VERSION "canboat-NMEA2000-curated"

NS_ :

BS_:

BU_: Vector__XXX
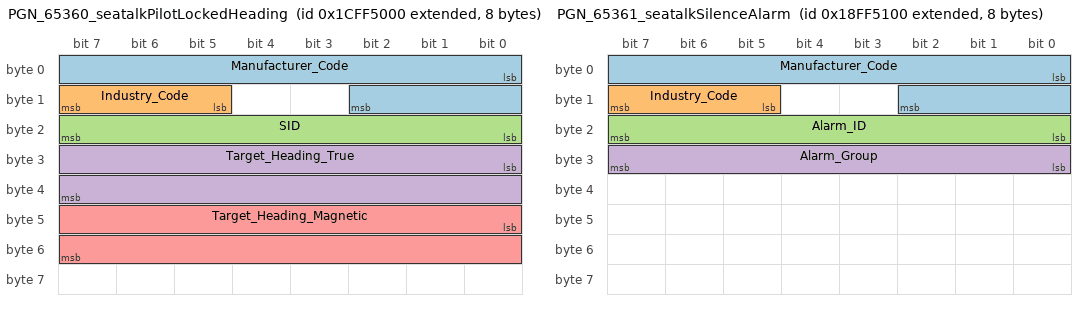
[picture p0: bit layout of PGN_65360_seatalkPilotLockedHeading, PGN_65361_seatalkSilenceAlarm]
BO_ 2633977856 PGN_65360_seatalkPilotLockedHeading: 8 Vector__XXX
 SG_ Manufacturer_Code : 0|11@1+ (1.0,0) [0|2047] "" Vector__XXX
 SG_ Industry_Code : 13|3@1+ (1.0,0) [0|7] "" Vector__XXX
 SG_ SID : 16|8@1+ (1.0,0) [0|255] "" Vector__XXX
 SG_ Target_Heading_True : 24|16@1+ (0.0001,0) [0.0|6.5535000000000005] "" Vector__XXX
 SG_ Target_Heading_Magnetic : 40|16@1+ (0.0001,0) [0.0|6.5535000000000005] "" Vector__XXX

BO_ 2566869248 PGN_65361_seatalkSilenceAlarm: 8 Vector__XXX
 SG_ Manufacturer_Code : 0|11@1+ (1.0,0) [0|2047] "" Vector__XXX
 SG_ Industry_Code : 13|3@1+ (1.0,0) [0|7] "" Vector__XXX
 SG_ Alarm_ID : 16|8@1+ (1.0,0) [0|255] "" Vector__XXX
 SG_ Alarm_Group : 24|8@1+ (1.0,0) [0|255] "" Vector__XXX

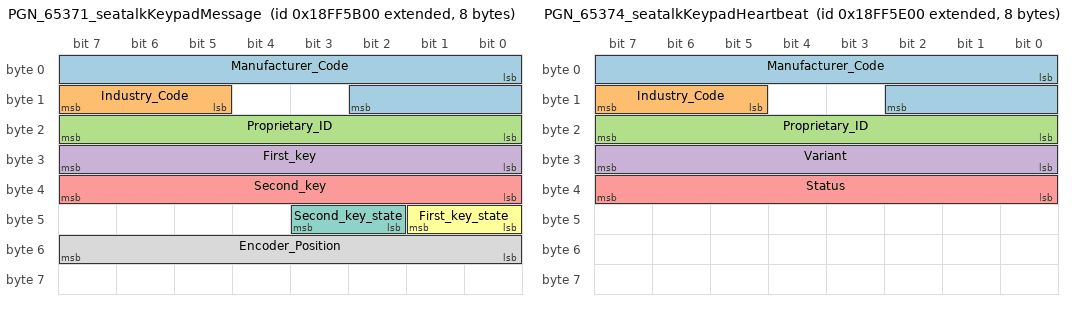
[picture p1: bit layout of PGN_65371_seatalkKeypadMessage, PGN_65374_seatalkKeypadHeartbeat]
BO_ 2566871808 PGN_65371_seatalkKeypadMessage: 8 Vector__XXX
 SG_ Manufacturer_Code : 0|11@1+ (1.0,0) [0|2047] "" Vector__XXX
 SG_ Industry_Code : 13|3@1+ (1.0,0) [0|7] "" Vector__XXX
 SG_ Proprietary_ID : 16|8@1+ (1.0,0) [0|255] "" Vector__XXX
 SG_ First_key : 24|8@1+ (1.0,0) [0|255] "" Vector__XXX
 SG_ Second_key : 32|8@1+ (1.0,0) [0|255] "" Vector__XXX
 SG_ First_key_state : 40|2@1+ (1.0,0) [0|3] "" Vector__XXX
 SG_ Second_key_state : 42|2@1+ (1.0,0) [0|3] "" Vector__XXX
 SG_ Encoder_Position : 48|8@1+ (1.0,0) [0|255] "" Vector__XXX

BO_ 2566872576 PGN_65374_seatalkKeypadHeartbeat: 8 Vector__XXX
 SG_ Manufacturer_Code : 0|11@1+ (1.0,0) [0|2047] "" Vector__XXX
 SG_ Industry_Code : 13|3@1+ (1.0,0) [0|7] "" Vector__XXX
 SG_ Proprietary_ID : 16|8@1+ (1.0,0) [0|255] "" Vector__XXX
 SG_ Variant : 24|8@1+ (1.0,0) [0|255] "" Vector__XXX
 SG_ Status : 32|8@1+ (1.0,0) [0|255] "" Vector__XXX

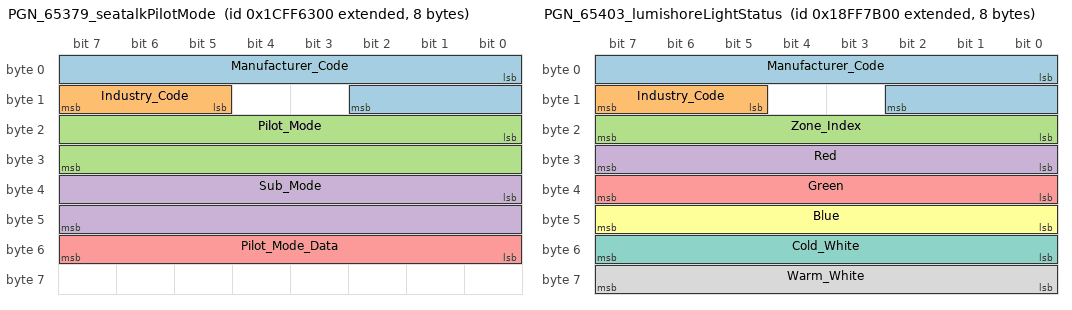
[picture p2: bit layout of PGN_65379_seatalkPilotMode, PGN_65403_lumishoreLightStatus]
BO_ 2633982720 PGN_65379_seatalkPilotMode: 8 Vector__XXX
 SG_ Manufacturer_Code : 0|11@1+ (1.0,0) [0|2047] "" Vector__XXX
 SG_ Industry_Code : 13|3@1+ (1.0,0) [0|7] "" Vector__XXX
 SG_ Pilot_Mode : 16|16@1+ (1.0,0) [0|65535] "" Vector__XXX
 SG_ Sub_Mode : 32|16@1+ (1.0,0) [0|65535] "" Vector__XXX
 SG_ Pilot_Mode_Data : 48|8@1+ (1.0,0) [0|255] "" Vector__XXX

BO_ 2566880000 PGN_65403_lumishoreLightStatus: 8 Vector__XXX
 SG_ Manufacturer_Code : 0|11@1+ (1.0,0) [0|2047] "" Vector__XXX
 SG_ Industry_Code : 13|3@1+ (1.0,0) [0|7] "" Vector__XXX
 SG_ Zone_Index : 16|8@1+ (1.0,0) [0|255] "" Vector__XXX
 SG_ Red : 24|8@1+ (1.0,0) [0|255] "" Vector__XXX
 SG_ Green : 32|8@1+ (1.0,0) [0|255] "" Vector__XXX
 SG_ Blue : 40|8@1+ (1.0,0) [0|255] "" Vector__XXX
 SG_ Cold_White : 48|8@1+ (1.0,0) [0|255] "" Vector__XXX
 SG_ Warm_White : 56|8@1+ (1.0,0) [0|255] "" Vector__XXX

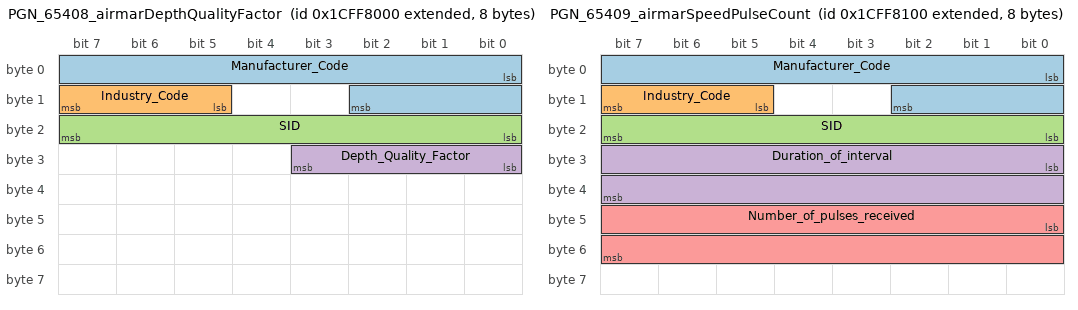
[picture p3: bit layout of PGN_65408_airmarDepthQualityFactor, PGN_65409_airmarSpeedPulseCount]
BO_ 2633990144 PGN_65408_airmarDepthQualityFactor: 8 Vector__XXX
 SG_ Manufacturer_Code : 0|11@1+ (1.0,0) [0|2047] "" Vector__XXX
 SG_ Industry_Code : 13|3@1+ (1.0,0) [0|7] "" Vector__XXX
 SG_ SID : 16|8@1+ (1.0,0) [0|255] "" Vector__XXX
 SG_ Depth_Quality_Factor : 24|4@1+ (1.0,0) [0|15] "" Vector__XXX

BO_ 2633990400 PGN_65409_airmarSpeedPulseCount: 8 Vector__XXX
 SG_ Manufacturer_Code : 0|11@1+ (1.0,0) [0|2047] "" Vector__XXX
 SG_ Industry_Code : 13|3@1+ (1.0,0) [0|7] "" Vector__XXX
 SG_ SID : 16|8@1+ (1.0,0) [0|255] "" Vector__XXX
 SG_ Duration_of_interval : 24|16@1+ (0.001,0) [0.0|65.535] "" Vector__XXX
 SG_ Number_of_pulses_received : 40|16@1+ (1.0,0) [0|65535] "" Vector__XXX

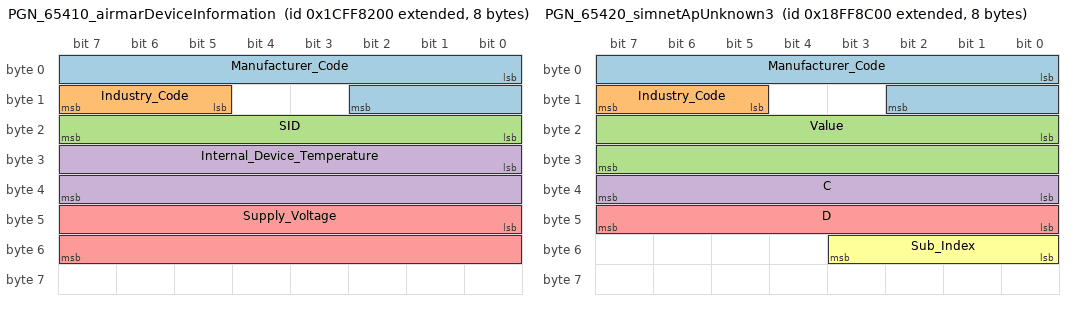
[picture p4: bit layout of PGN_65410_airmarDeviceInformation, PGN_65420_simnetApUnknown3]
BO_ 2633990656 PGN_65410_airmarDeviceInformation: 8 Vector__XXX
 SG_ Manufacturer_Code : 0|11@1+ (1.0,0) [0|2047] "" Vector__XXX
 SG_ Industry_Code : 13|3@1+ (1.0,0) [0|7] "" Vector__XXX
 SG_ SID : 16|8@1+ (1.0,0) [0|255] "" Vector__XXX
 SG_ Internal_Device_Temperature : 24|16@1+ (0.01,0) [0.0|655.35] "" Vector__XXX
 SG_ Supply_Voltage : 40|16@1+ (0.01,0) [0.0|655.35] "" Vector__XXX

BO_ 2566884352 PGN_65420_simnetApUnknown3: 8 Vector__XXX
 SG_ Manufacturer_Code : 0|11@1+ (1.0,0) [0|2047] "" Vector__XXX
 SG_ Industry_Code : 13|3@1+ (1.0,0) [0|7] "" Vector__XXX
 SG_ Value : 16|16@1+ (1.0,0) [0|65535] "" Vector__XXX
 SG_ C : 32|8@1+ (1.0,0) [0|255] "" Vector__XXX
 SG_ D : 40|8@1+ (1.0,0) [0|255] "" Vector__XXX
 SG_ Sub_Index : 48|4@1+ (1.0,0) [0|15] "" Vector__XXX

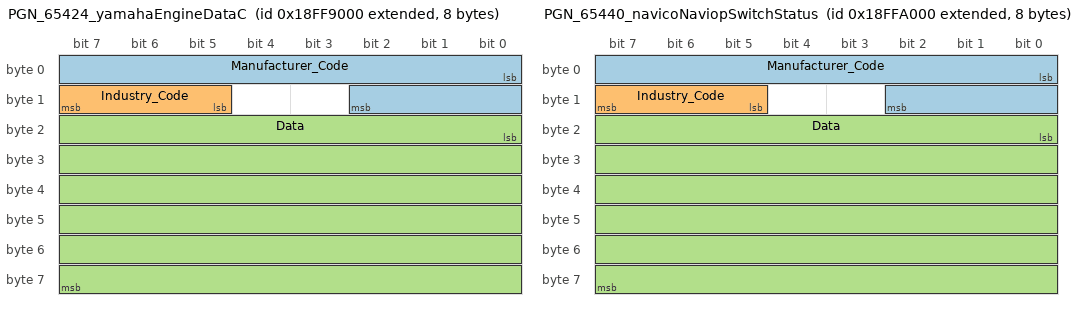
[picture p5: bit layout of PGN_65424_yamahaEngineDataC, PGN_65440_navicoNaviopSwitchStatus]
BO_ 2566885376 PGN_65424_yamahaEngineDataC: 8 Vector__XXX
 SG_ Manufacturer_Code : 0|11@1+ (1.0,0) [0|2047] "" Vector__XXX
 SG_ Industry_Code : 13|3@1+ (1.0,0) [0|7] "" Vector__XXX
 SG_ Data : 16|48@1+ (1.0,0) [0|281474976710655] "" Vector__XXX

BO_ 2566889472 PGN_65440_navicoNaviopSwitchStatus: 8 Vector__XXX
 SG_ Manufacturer_Code : 0|11@1+ (1.0,0) [0|2047] "" Vector__XXX
 SG_ Industry_Code : 13|3@1+ (1.0,0) [0|7] "" Vector__XXX
 SG_ Data : 16|48@1+ (1.0,0) [0|281474976710655] "" Vector__XXX

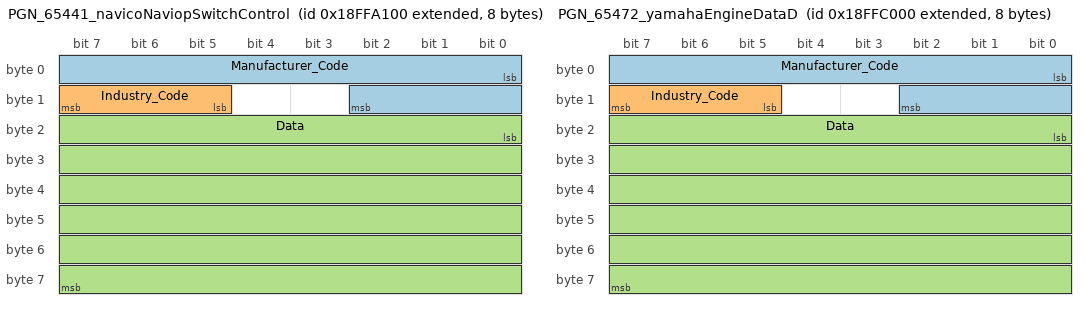
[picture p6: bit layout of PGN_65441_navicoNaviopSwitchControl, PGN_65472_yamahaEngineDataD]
BO_ 2566889728 PGN_65441_navicoNaviopSwitchControl: 8 Vector__XXX
 SG_ Manufacturer_Code : 0|11@1+ (1.0,0) [0|2047] "" Vector__XXX
 SG_ Industry_Code : 13|3@1+ (1.0,0) [0|7] "" Vector__XXX
 SG_ Data : 16|48@1+ (1.0,0) [0|281474976710655] "" Vector__XXX

BO_ 2566897664 PGN_65472_yamahaEngineDataD: 8 Vector__XXX
 SG_ Manufacturer_Code : 0|11@1+ (1.0,0) [0|2047] "" Vector__XXX
 SG_ Industry_Code : 13|3@1+ (1.0,0) [0|7] "" Vector__XXX
 SG_ Data : 16|48@1+ (1.0,0) [0|281474976710655] "" Vector__XXX

BO_ 2566899712 PGN_65480_simnetAutopilotMode: 8 Vector__XXX
 SG_ Manufacturer_Code : 0|11@1+ (1.0,0) [0|2047] "" Vector__XXX
 SG_ Industry_Code : 13|3@1+ (1.0,0) [0|7] "" Vector__XXX

BO_ 2381119488 PGN_126208: 223 Vector__XXX
 SG_ Data : 0|1784@1+ (1.0,0) [0|1090215279796298345343057319992441691038624747443985361781209060500115864369550760897269927218265076257224706224150656474098235960303036328065314058501678867531182833105052489870268422279120576700031813116210596361941430020414688522690787050244934600671795757515093047026287646566366777283893649942831776083163858446641848270013788759459916945946844663111358071639842481472666169361795887031940572252862030682746818684507336852618633070135215708762463263460541984102045620907003420426453486084172633338261276848631947315738747720031010815] "" Vector__XXX

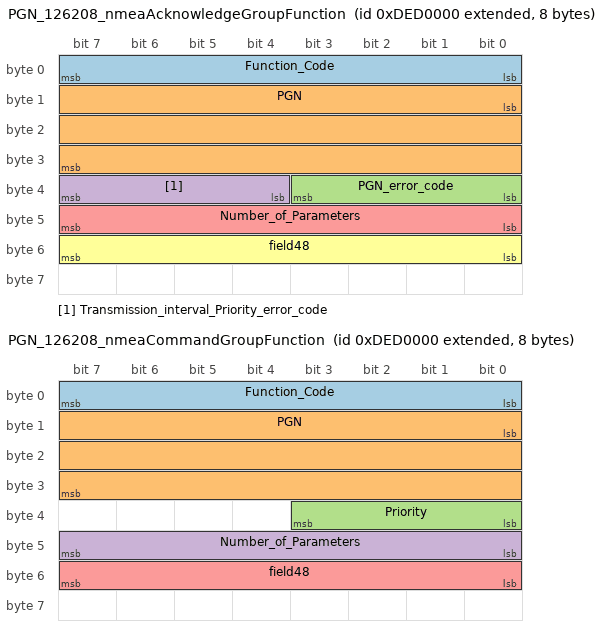
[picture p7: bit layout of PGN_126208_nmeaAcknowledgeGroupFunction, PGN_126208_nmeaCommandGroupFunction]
BO_ 2381119488 PGN_126208_nmeaAcknowledgeGroupFunction: 8 Vector__XXX
 SG_ Function_Code : 0|8@1+ (1.0,0) [0|255] "" Vector__XXX
 SG_ PGN : 8|24@1+ (1.0,0) [0.0|262143.0] "" Vector__XXX
 SG_ PGN_error_code : 32|4@1+ (1.0,0) [0|15] "" Vector__XXX
 SG_ Transmission_interval_Priority_error_code : 36|4@1+ (1.0,0) [0|15] "" Vector__XXX
 SG_ Number_of_Parameters : 40|8@1+ (1.0,0) [0|255] "" Vector__XXX
 SG_ field48 : 48|8@1+ (1.0,0) [0|255] "" Vector__XXX

BO_ 2381119488 PGN_126208_nmeaCommandGroupFunction: 8 Vector__XXX
 SG_ Function_Code : 0|8@1+ (1.0,0) [0|255] "" Vector__XXX
 SG_ PGN : 8|24@1+ (1.0,0) [0.0|262143.0] "" Vector__XXX
 SG_ Priority : 32|4@1+ (1.0,0) [0|15] "" Vector__XXX
 SG_ Number_of_Parameters : 40|8@1+ (1.0,0) [0|255] "" Vector__XXX
 SG_ field48 : 48|8@1+ (1.0,0) [0|255] "" Vector__XXX

BO_ 2381119488 PGN_126208_nmeaReadFieldsGroupFunction: 11 Vector__XXX
 SG_ Function_Code : 0|8@1+ (1.0,0) [0|255] "" Vector__XXX
 SG_ PGN : 8|24@1+ (1.0,0) [0.0|262143.0] "" Vector__XXX
 SG_ Manufacturer_Code : 32|11@1+ (1.0,0) [0|2047] "" Vector__XXX
 SG_ Industry_Code : 45|3@1+ (1.0,0) [0|7] "" Vector__XXX
 SG_ Unique_ID : 48|8@1+ (1.0,0) [0|255] "" Vector__XXX
 SG_ Number_of_Selection_Pairs : 56|8@1+ (1.0,0) [0|255] "" Vector__XXX
 SG_ Number_of_Parameters : 64|8@1+ (1.0,0) [0|255] "" Vector__XXX
 SG_ field72 : 72|8@1+ (1.0,0) [0|255] "" Vector__XXX
 SG_ field80 : 80|8@1+ (1.0,0) [0|255] "" Vector__XXX

BO_ 2381119488 PGN_126208_nmeaReadFieldsReplyGroupFunction: 11 Vector__XXX
 SG_ Function_Code : 0|8@1+ (1.0,0) [0|255] "" Vector__XXX
 SG_ PGN : 8|24@1+ (1.0,0) [0.0|262143.0] "" Vector__XXX
 SG_ Manufacturer_Code : 32|11@1+ (1.0,0) [0|2047] "" Vector__XXX
 SG_ Industry_Code : 45|3@1+ (1.0,0) [0|7] "" Vector__XXX
 SG_ Unique_ID : 48|8@1+ (1.0,0) [0|255] "" Vector__XXX
 SG_ Number_of_Selection_Pairs : 56|8@1+ (1.0,0) [0|255] "" Vector__XXX
 SG_ Number_of_Parameters : 64|8@1+ (1.0,0) [0|255] "" Vector__XXX
 SG_ field72 : 72|8@1+ (1.0,0) [0|255] "" Vector__XXX
 SG_ field80 : 80|8@1+ (1.0,0) [0|255] "" Vector__XXX

BO_ 2381119488 PGN_126208_nmeaRequestGroupFunction: 12 Vector__XXX
 SG_ Function_Code : 0|8@1+ (1.0,0) [0|255] "" Vector__XXX
 SG_ PGN : 8|24@1+ (1.0,0) [0.0|262143.0] "" Vector__XXX
 SG_ Transmission_interval : 32|32@1+ (0.001,0) [0.0|4294967.295] "" Vector__XXX
 SG_ Transmission_interval_offset : 64|16@1+ (0.01,0) [0.0|655.35] "" Vector__XXX
 SG_ Number_of_Parameters : 80|8@1+ (1.0,0) [0|255] "" Vector__XXX
 SG_ field88 : 88|8@1+ (1.0,0) [0|255] "" Vector__XXX

BO_ 2381119488 PGN_126208_nmeaWriteFieldsGroupFunction: 11 Vector__XXX
 SG_ Function_Code : 0|8@1+ (1.0,0) [0|255] "" Vector__XXX
 SG_ PGN : 8|24@1+ (1.0,0) [0.0|262143.0] "" Vector__XXX
 SG_ Manufacturer_Code : 32|11@1+ (1.0,0) [0|2047] "" Vector__XXX
 SG_ Industry_Code : 45|3@1+ (1.0,0) [0|7] "" Vector__XXX
 SG_ Unique_ID : 48|8@1+ (1.0,0) [0|255] "" Vector__XXX
 SG_ Number_of_Selection_Pairs : 56|8@1+ (1.0,0) [0|255] "" Vector__XXX
 SG_ Number_of_Parameters : 64|8@1+ (1.0,0) [0|255] "" Vector__XXX
 SG_ field72 : 72|8@1+ (1.0,0) [0|255] "" Vector__XXX
 SG_ field80 : 80|8@1+ (1.0,0) [0|255] "" Vector__XXX

BO_ 2381119488 PGN_126208_nmeaWriteFieldsReplyGroupFunction: 11 Vector__XXX
 SG_ Function_Code : 0|8@1+ (1.0,0) [0|255] "" Vector__XXX
 SG_ PGN : 8|24@1+ (1.0,0) [0.0|262143.0] "" Vector__XXX
 SG_ Manufacturer_Code : 32|11@1+ (1.0,0) [0|2047] "" Vector__XXX
 SG_ Industry_Code : 45|3@1+ (1.0,0) [0|7] "" Vector__XXX
 SG_ Unique_ID : 48|8@1+ (1.0,0) [0|255] "" Vector__XXX
 SG_ Number_of_Selection_Pairs : 56|8@1+ (1.0,0) [0|255] "" Vector__XXX
 SG_ Number_of_Parameters : 64|8@1+ (1.0,0) [0|255] "" Vector__XXX
 SG_ field72 : 72|8@1+ (1.0,0) [0|255] "" Vector__XXX
 SG_ field80 : 80|8@1+ (1.0,0) [0|255] "" Vector__XXX

BO_ 2582511616 PGN_126464_pgnListTransmitAndReceive: 8 Vector__XXX
 SG_ Function_Code : 0|8@1+ (1.0,0) [0|255] "" Vector__XXX
 SG_ field8 : 8|8@1+ (1.0,0) [0|255] "" Vector__XXX

BO_ 2582577152 PGN_126720_0x1ef00ManufacturerProprietaryFastPacketAddressed: 223 Vector__XXX

BO_ 2582577152 PGN_126720_airmarAddressableMultiFrame: 8 Vector__XXX

BO_ 2582577152 PGN_126720_airmarAttitudeOffset: 9 Vector__XXX

BO_ 2582577152 PGN_126720_airmarCalibrateCompass: 24 Vector__XXX

BO_ 2582577152 PGN_126720_airmarCalibrateDepth: 8 Vector__XXX

BO_ 2582577152 PGN_126720_airmarCalibrateSpeed: 8 Vector__XXX

BO_ 2582577152 PGN_126720_airmarCalibrateTemperature: 8 Vector__XXX

BO_ 2582577152 PGN_126720_airmarNmea2000Options: 8 Vector__XXX

BO_ 2582577152 PGN_126720_airmarSimulateMode: 8 Vector__XXX

BO_ 2582577152 PGN_126720_airmarSpeedFilterIir: 8 Vector__XXX

BO_ 2582577152 PGN_126720_airmarSpeedFilterNone: 8 Vector__XXX

BO_ 2582577152 PGN_126720_airmarTemperatureFilterIir: 8 Vector__XXX

BO_ 2582577152 PGN_126720_airmarTemperatureFilterNone: 8 Vector__XXX

BO_ 2582577152 PGN_126720_airmarTrueWindOptions: 8 Vector__XXX

BO_ 2582577152 PGN_126720_carlingDcConfigurationCommand: 13 Vector__XXX

BO_ 2582577152 PGN_126720_fusionMediaControl: 8 Vector__XXX

BO_ 2582577152 PGN_126720_fusionMenuActionCommand: 11 Vector__XXX

BO_ 2582577152 PGN_126720_fusionRequestMenuCount: 8 Vector__XXX

BO_ 2582577152 PGN_126720_fusionRequestMenuItems: 14 Vector__XXX

BO_ 2582577152 PGN_126720_fusionRequestStatus: 8 Vector__XXX

BO_ 2582577152 PGN_126720_fusionSetAllVolumes: 8 Vector__XXX

BO_ 2582577152 PGN_126720_fusionSetMute: 8 Vector__XXX

BO_ 2582577152 PGN_126720_fusionSetPower: 8 Vector__XXX

BO_ 2582577152 PGN_126720_fusionSetSetting: 12 Vector__XXX

BO_ 2582577152 PGN_126720_fusionSetSource: 8 Vector__XXX

BO_ 2582577152 PGN_126720_fusionSetZoneVolume: 8 Vector__XXX

BO_ 2582577152 PGN_126720_fusionSiriusControl: 8 Vector__XXX

BO_ 2582577152 PGN_126720_garminAhrsAttCogSourceValidFlag: 12 Vector__XXX

BO_ 2582577152 PGN_126720_garminAhrsAttDeviceFlags: 12 Vector__XXX

BO_ 2582577152 PGN_126720_garminAhrsAttNonDefaultCalibrationMatrixPresent: 9 Vector__XXX

BO_ 2582577152 PGN_126720_garminAhrsAttSetNorthState: 9 Vector__XXX

BO_ 2582577152 PGN_126720_garminColorMode: 11 Vector__XXX

BO_ 2582577152 PGN_126720_garminDayMode: 11 Vector__XXX

BO_ 2582577152 PGN_126720_garminNightMode: 11 Vector__XXX

BO_ 2582577152 PGN_126720_lumishoreProprietary: 225 Vector__XXX

BO_ 2582577152 PGN_126720_maretronDeviationCalibrationResponse: 8 Vector__XXX

BO_ 2582577152 PGN_126720_maretronProprietaryConfiguration: 230 Vector__XXX

BO_ 2582577152 PGN_126720_seatalk1DeviceIdentification: 8 Vector__XXX

BO_ 2582577152 PGN_126720_seatalk1DisplayBrightness: 9 Vector__XXX

BO_ 2582577152 PGN_126720_seatalk1DisplayColor: 9 Vector__XXX

BO_ 2582577152 PGN_126720_seatalk1Keystroke: 22 Vector__XXX

BO_ 2582577152 PGN_126720_seatalk1PilotHullType: 14 Vector__XXX

BO_ 2582577152 PGN_126720_seatalk1PilotMode: 21 Vector__XXX

BO_ 2582577152 PGN_126720_seatalkPilotAutoTurn: 9 Vector__XXX

CM_ BO_ 2633977856 "NMEA2000: PGN 65360 - Seatalk: Pilot Locked Heading (type: Single)";
CM_ BO_ 2566869248 "NMEA2000: PGN 65361 - Seatalk: Silence Alarm (type: Single)";
CM_ BO_ 2566871808 "NMEA2000: PGN 65371 - Seatalk: Keypad Message (type: Single)";
CM_ BO_ 2566872576 "NMEA2000: PGN 65374 - SeaTalk: Keypad Heartbeat (type: Single)";
CM_ BO_ 2633982720 "NMEA2000: PGN 65379 - Seatalk: Pilot Mode (type: Single)";
CM_ BO_ 2566880000 "NMEA2000: PGN 65403 - Lumishore: Light Status (type: Single)";
CM_ BO_ 2633990144 "NMEA2000: PGN 65408 - Airmar: Depth Quality Factor (type: Single)";
CM_ BO_ 2633990400 "NMEA2000: PGN 65409 - Airmar: Speed Pulse Count (type: Single)";
CM_ BO_ 2633990656 "NMEA2000: PGN 65410 - Airmar: Device Information (type: Single)";
CM_ BO_ 2566884352 "NMEA2000: PGN 65420 - Simnet: AP Unknown 3 (type: Single)";
CM_ BO_ 2566885376 "NMEA2000: PGN 65424 - Yamaha: Engine Data C (type: Single)";
CM_ BO_ 2566889472 "NMEA2000: PGN 65440 - Navico: Naviop Switch Status (type: Single)";
CM_ BO_ 2566889728 "NMEA2000: PGN 65441 - Navico: Naviop Switch Control (type: Single)";
CM_ BO_ 2566897664 "NMEA2000: PGN 65472 - Yamaha: Engine Data D (type: Single)";
CM_ BO_ 2566899712 "NMEA2000: PGN 65480 - Simnet: Autopilot Mode (type: Single)";
CM_ BO_ 2381119488 "NMEA2000: PGN 126208 - 0x1ED00 - 0x1EE00: Standardized fast-packet addressed (type: Fast)";
CM_ BO_ 2381119488 "NMEA2000: PGN 126208 - NMEA - Acknowledge group function (type: Fast)";
CM_ BO_ 2381119488 "NMEA2000: PGN 126208 - NMEA - Command group function (type: Fast)";
CM_ BO_ 2381119488 "NMEA2000: PGN 126208 - NMEA - Read Fields group function (type: Fast)";
CM_ BO_ 2381119488 "NMEA2000: PGN 126208 - NMEA - Read Fields reply group function (type: Fast)";
CM_ BO_ 2381119488 "NMEA2000: PGN 126208 - NMEA - Request group function (type: Fast)";
CM_ BO_ 2381119488 "NMEA2000: PGN 126208 - NMEA - Write Fields group function (type: Fast)";
CM_ BO_ 2381119488 "NMEA2000: PGN 126208 - NMEA - Write Fields reply group function (type: Fast)";
CM_ BO_ 2582511616 "NMEA2000: PGN 126464 - PGN List (Transmit and Receive) (type: Fast)";
CM_ BO_ 2582577152 "NMEA2000: PGN 126720 - 0x1EF00: Manufacturer Proprietary fast-packet addressed (type: Fast)";
CM_ BO_ 2582577152 "NMEA2000: PGN 126720 - Airmar: Addressable Multi-Frame (type: Fast)";
CM_ BO_ 2582577152 "NMEA2000: PGN 126720 - Airmar: Attitude Offset (type: Fast)";
CM_ BO_ 2582577152 "NMEA2000: PGN 126720 - Airmar: Calibrate Compass (type: Fast)";
CM_ BO_ 2582577152 "NMEA2000: PGN 126720 - Airmar: Calibrate Depth (type: Fast)";
CM_ BO_ 2582577152 "NMEA2000: PGN 126720 - Airmar: Calibrate Speed (type: Fast)";
CM_ BO_ 2582577152 "NMEA2000: PGN 126720 - Airmar: Calibrate Temperature (type: Fast)";
CM_ BO_ 2582577152 "NMEA2000: PGN 126720 - Airmar: NMEA 2000 options (type: Fast)";
CM_ BO_ 2582577152 "NMEA2000: PGN 126720 - Airmar: Simulate Mode (type: Fast)";
CM_ BO_ 2582577152 "NMEA2000: PGN 126720 - Airmar: Speed Filter IIR (type: Fast)";
CM_ BO_ 2582577152 "NMEA2000: PGN 126720 - Airmar: Speed Filter None (type: Fast)";
CM_ BO_ 2582577152 "NMEA2000: PGN 126720 - Airmar: Temperature Filter IIR (type: Fast)";
CM_ BO_ 2582577152 "NMEA2000: PGN 126720 - Airmar: Temperature Filter None (type: Fast)";
CM_ BO_ 2582577152 "NMEA2000: PGN 126720 - Airmar: True Wind Options (type: Fast)";
CM_ BO_ 2582577152 "NMEA2000: PGN 126720 - Carling: DC Configuration Command (type: Fast)";
CM_ BO_ 2582577152 "NMEA2000: PGN 126720 - Fusion: Media Control (type: Fast)";
CM_ BO_ 2582577152 "NMEA2000: PGN 126720 - Fusion: Menu Action Command (type: Fast)";
CM_ BO_ 2582577152 "NMEA2000: PGN 126720 - Fusion: Request Menu Count (type: Fast)";
CM_ BO_ 2582577152 "NMEA2000: PGN 126720 - Fusion: Request Menu Items (type: Fast)";
CM_ BO_ 2582577152 "NMEA2000: PGN 126720 - Fusion: Request Status (type: Fast)";
CM_ BO_ 2582577152 "NMEA2000: PGN 126720 - Fusion: Set All Volumes (type: Fast)";
CM_ BO_ 2582577152 "NMEA2000: PGN 126720 - Fusion: Set Mute (type: Fast)";
CM_ BO_ 2582577152 "NMEA2000: PGN 126720 - Fusion: Set Power (type: Fast)";
CM_ BO_ 2582577152 "NMEA2000: PGN 126720 - Fusion: Set Setting (type: Fast)";
CM_ BO_ 2582577152 "NMEA2000: PGN 126720 - Fusion: Set Source (type: Fast)";
CM_ BO_ 2582577152 "NMEA2000: PGN 126720 - Fusion: Set Zone Volume (type: Fast)";
CM_ BO_ 2582577152 "NMEA2000: PGN 126720 - Fusion: Sirius Control (type: Fast)";
CM_ BO_ 2582577152 "NMEA2000: PGN 126720 - Garmin AHRS ATT: COG Source Valid Flag (type: Fast)";
CM_ BO_ 2582577152 "NMEA2000: PGN 126720 - Garmin AHRS ATT: Device Flags (type: Fast)";
CM_ BO_ 2582577152 "NMEA2000: PGN 126720 - Garmin AHRS ATT: Non-default Calibration Matrix Present (type: Fast)";
CM_ BO_ 2582577152 "NMEA2000: PGN 126720 - Garmin AHRS ATT: Set North State (type: Fast)";
CM_ BO_ 2582577152 "NMEA2000: PGN 126720 - Garmin: Color mode (type: Fast)";
CM_ BO_ 2582577152 "NMEA2000: PGN 126720 - Garmin: Day Mode (type: Fast)";
CM_ BO_ 2582577152 "NMEA2000: PGN 126720 - Garmin: Night Mode (type: Fast)";
CM_ BO_ 2582577152 "NMEA2000: PGN 126720 - Lumishore: Proprietary (type: Fast)";
CM_ BO_ 2582577152 "NMEA2000: PGN 126720 - Maretron: Deviation Calibration Response (type: Fast)";
CM_ BO_ 2582577152 "NMEA2000: PGN 126720 - Maretron: Proprietary Configuration (type: Fast)";
CM_ BO_ 2582577152 "NMEA2000: PGN 126720 - Seatalk1: Device Identification (type: Fast)";
CM_ BO_ 2582577152 "NMEA2000: PGN 126720 - Seatalk1: Display Brightness (type: Fast)";
CM_ BO_ 2582577152 "NMEA2000: PGN 126720 - Seatalk1: Display Color (type: Fast)";
CM_ BO_ 2582577152 "NMEA2000: PGN 126720 - Seatalk1: Keystroke (type: Fast)";
CM_ BO_ 2582577152 "NMEA2000: PGN 126720 - Seatalk1: Pilot Hull Type (type: Fast)";
CM_ BO_ 2582577152 "NMEA2000: PGN 126720 - Seatalk1: Pilot Mode (type: Fast)";
CM_ BO_ 2582577152 "NMEA2000: PGN 126720 - Seatalk: Pilot Auto Turn (type: Fast)";
CM_ SG_ 2633977856 Manufacturer_Code "Raymarine; canboat type: LOOKUP";
CM_ SG_ 2633977856 Industry_Code "Marine Industry; canboat type: LOOKUP";
CM_ SG_ 2633977856 SID "canboat type: UINT8";
CM_ SG_ 2633977856 Target_Heading_True "canboat type: ANGLE_UFIX16";
CM_ SG_ 2633977856 Target_Heading_Magnetic "canboat type: ANGLE_UFIX16";
CM_ SG_ 2566869248 Manufacturer_Code "Raymarine; canboat type: LOOKUP";
CM_ SG_ 2566869248 Industry_Code "Marine Industry; canboat type: LOOKUP";
CM_ SG_ 2566869248 Alarm_ID "canboat type: LOOKUP";
CM_ SG_ 2566869248 Alarm_Group "canboat type: LOOKUP";
CM_ SG_ 2566871808 Manufacturer_Code "Raymarine; canboat type: LOOKUP";
CM_ SG_ 2566871808 Industry_Code "Marine Industry; canboat type: LOOKUP";
CM_ SG_ 2566871808 Proprietary_ID "canboat type: UINT8";
CM_ SG_ 2566871808 First_key "canboat type: UINT8";
CM_ SG_ 2566871808 Second_key "canboat type: UINT8";
CM_ SG_ 2566871808 First_key_state "canboat type: UNSIGNED_INTEGER";
CM_ SG_ 2566871808 Second_key_state "canboat type: UNSIGNED_INTEGER";
CM_ SG_ 2566871808 Encoder_Position "canboat type: UINT8";
CM_ SG_ 2566872576 Manufacturer_Code "Raymarine; canboat type: LOOKUP";
CM_ SG_ 2566872576 Industry_Code "Marine Industry; canboat type: LOOKUP";
CM_ SG_ 2566872576 Proprietary_ID "canboat type: UINT8";
CM_ SG_ 2566872576 Variant "canboat type: UINT8";
CM_ SG_ 2566872576 Status "canboat type: UINT8";
CM_ SG_ 2633982720 Manufacturer_Code "Raymarine; canboat type: LOOKUP";
CM_ SG_ 2633982720 Industry_Code "Marine Industry; canboat type: LOOKUP";
CM_ SG_ 2633982720 Pilot_Mode "canboat type: LOOKUP";
CM_ SG_ 2633982720 Sub_Mode "canboat type: BINARY";
CM_ SG_ 2633982720 Pilot_Mode_Data "canboat type: BINARY";
CM_ SG_ 2566880000 Manufacturer_Code "Lumishore; canboat type: LOOKUP";
CM_ SG_ 2566880000 Industry_Code "Marine Industry; canboat type: LOOKUP";
CM_ SG_ 2566880000 Zone_Index "canboat type: UINT8";
CM_ SG_ 2566880000 Red "canboat type: UINT8";
CM_ SG_ 2566880000 Green "canboat type: UINT8";
CM_ SG_ 2566880000 Blue "canboat type: UINT8";
CM_ SG_ 2566880000 Cold_White "canboat type: UINT8";
CM_ SG_ 2566880000 Warm_White "canboat type: UINT8";
CM_ SG_ 2633990144 Manufacturer_Code "Airmar; canboat type: LOOKUP";
CM_ SG_ 2633990144 Industry_Code "Marine Industry; canboat type: LOOKUP";
CM_ SG_ 2633990144 SID "canboat type: UINT8";
CM_ SG_ 2633990144 Depth_Quality_Factor "canboat type: LOOKUP";
CM_ SG_ 2633990400 Manufacturer_Code "Airmar; canboat type: LOOKUP";
CM_ SG_ 2633990400 Industry_Code "Marine Industry; canboat type: LOOKUP";
CM_ SG_ 2633990400 SID "canboat type: UINT8";
CM_ SG_ 2633990400 Duration_of_interval "canboat type: DURATION_UFIX16_MS";
CM_ SG_ 2633990400 Number_of_pulses_received "canboat type: UINT16";
CM_ SG_ 2633990656 Manufacturer_Code "Airmar; canboat type: LOOKUP";
CM_ SG_ 2633990656 Industry_Code "Marine Industry; canboat type: LOOKUP";
CM_ SG_ 2633990656 SID "canboat type: UINT8";
CM_ SG_ 2633990656 Internal_Device_Temperature "canboat type: TEMPERATURE";
CM_ SG_ 2633990656 Supply_Voltage "canboat type: VOLTAGE_UFIX16_10MV";
CM_ SG_ 2566884352 Manufacturer_Code "Simrad; canboat type: LOOKUP";
CM_ SG_ 2566884352 Industry_Code "Marine Industry; canboat type: LOOKUP";
CM_ SG_ 2566884352 Value "canboat type: UINT16";
CM_ SG_ 2566884352 C "canboat type: UINT8";
CM_ SG_ 2566884352 D "canboat type: UINT8";
CM_ SG_ 2566884352 Sub_Index "Selects the reported variable (0 and 1 seen); canboat type: UNSIGNED_INTEGER";
CM_ SG_ 2566885376 Manufacturer_Code "Mystic Valley Communications; canboat type: LOOKUP";
CM_ SG_ 2566885376 Industry_Code "Marine Industry; canboat type: LOOKUP";
CM_ SG_ 2566885376 Data "canboat type: BINARY";
CM_ SG_ 2566889472 Manufacturer_Code "Navico; canboat type: LOOKUP";
CM_ SG_ 2566889472 Industry_Code "Marine Industry; canboat type: LOOKUP";
CM_ SG_ 2566889472 Data "canboat type: BINARY";
CM_ SG_ 2566889728 Manufacturer_Code "Navico; canboat type: LOOKUP";
CM_ SG_ 2566889728 Industry_Code "Marine Industry; canboat type: LOOKUP";
CM_ SG_ 2566889728 Data "canboat type: BINARY";
CM_ SG_ 2566897664 Manufacturer_Code "Mystic Valley Communications; canboat type: LOOKUP";
CM_ SG_ 2566897664 Industry_Code "Marine Industry; canboat type: LOOKUP";
CM_ SG_ 2566897664 Data "canboat type: BINARY";
CM_ SG_ 2566899712 Manufacturer_Code "Simrad; canboat type: LOOKUP";
CM_ SG_ 2566899712 Industry_Code "Marine Industry; canboat type: LOOKUP";
CM_ SG_ 2381119488 Data "canboat type: BINARY";
CM_ SG_ 2381119488 Function_Code "Acknowledge; canboat type: LOOKUP";
CM_ SG_ 2381119488 PGN "Commanded PGN; canboat type: PGN";
CM_ SG_ 2381119488 PGN_error_code "canboat type: LOOKUP";
CM_ SG_ 2381119488 Transmission_interval_Priority_error_code "canboat type: LOOKUP";
CM_ SG_ 2381119488 Number_of_Parameters "canboat type: UINT8";
CM_ SG_ 2381119488 field48 "canboat type: NUMBER";
CM_ SG_ 2381119488 Function_Code "Command; canboat type: LOOKUP";
CM_ SG_ 2381119488 PGN "Commanded PGN; canboat type: PGN";
CM_ SG_ 2381119488 Priority "canboat type: LOOKUP";
CM_ SG_ 2381119488 Number_of_Parameters "How many parameter pairs will follow; canboat type: UINT8";
CM_ SG_ 2381119488 field48 "canboat type: NUMBER";
CM_ SG_ 2381119488 Function_Code "Read Fields; canboat type: LOOKUP";
CM_ SG_ 2381119488 PGN "Commanded PGN; canboat type: PGN";
CM_ SG_ 2381119488 Manufacturer_Code "Only in PGN when Commanded PGN is proprietary; canboat type: LOOKUP";
CM_ SG_ 2381119488 Industry_Code "Only in PGN when Commanded PGN is proprietary; canboat type: LOOKUP";
CM_ SG_ 2381119488 Unique_ID "canboat type: UINT8";
CM_ SG_ 2381119488 Number_of_Selection_Pairs "canboat type: UINT8";
CM_ SG_ 2381119488 Number_of_Parameters "canboat type: UINT8";
CM_ SG_ 2381119488 field72 "canboat type: NUMBER";
CM_ SG_ 2381119488 field80 "canboat type: NUMBER";
CM_ SG_ 2381119488 Function_Code "Read Fields Reply; canboat type: LOOKUP";
CM_ SG_ 2381119488 PGN "Commanded PGN; canboat type: PGN";
CM_ SG_ 2381119488 Manufacturer_Code "Only in PGN when Commanded PGN is proprietary; canboat type: LOOKUP";
CM_ SG_ 2381119488 Industry_Code "Only in PGN when Commanded PGN is proprietary; canboat type: LOOKUP";
CM_ SG_ 2381119488 Unique_ID "canboat type: UINT8";
CM_ SG_ 2381119488 Number_of_Selection_Pairs "canboat type: UINT8";
CM_ SG_ 2381119488 Number_of_Parameters "canboat type: UINT8";
CM_ SG_ 2381119488 field72 "canboat type: NUMBER";
CM_ SG_ 2381119488 field80 "canboat type: NUMBER";
CM_ SG_ 2381119488 Function_Code "Request; canboat type: LOOKUP";
CM_ SG_ 2381119488 PGN "Requested PGN; canboat type: PGN";
CM_ SG_ 2381119488 Transmission_interval "0x0: Turn off transmission; 0xFFFF FFFE = Restore default interval, 0xFFFF FFFF in this field and 0xFFFF in field 4 = Transmit now without changing timing variables; canboat type: DURATION_UFIX32_MS";
CM_ SG_ 2381119488 Transmission_interval_offset "canboat type: DURATION_UFIX16_CS";
CM_ SG_ 2381119488 Number_of_Parameters "How many parameter pairs will follow; canboat type: UINT8";
CM_ SG_ 2381119488 field88 "canboat type: NUMBER";
CM_ SG_ 2381119488 Function_Code "Write Fields; canboat type: LOOKUP";
CM_ SG_ 2381119488 PGN "Commanded PGN; canboat type: PGN";
CM_ SG_ 2381119488 Manufacturer_Code "Only in PGN when Commanded PGN is proprietary; canboat type: LOOKUP";
CM_ SG_ 2381119488 Industry_Code "Only in PGN when Commanded PGN is proprietary; canboat type: LOOKUP";
CM_ SG_ 2381119488 Unique_ID "canboat type: UINT8";
CM_ SG_ 2381119488 Number_of_Selection_Pairs "canboat type: UINT8";
CM_ SG_ 2381119488 Number_of_Parameters "canboat type: UINT8";
CM_ SG_ 2381119488 field72 "canboat type: NUMBER";
CM_ SG_ 2381119488 field80 "canboat type: NUMBER";
CM_ SG_ 2381119488 Function_Code "Write Fields Reply; canboat type: LOOKUP";
CM_ SG_ 2381119488 PGN "Commanded PGN; canboat type: PGN";
CM_ SG_ 2381119488 Manufacturer_Code "Only in PGN when Commanded PGN is proprietary; canboat type: LOOKUP";
CM_ SG_ 2381119488 Industry_Code "Only in PGN when Commanded PGN is proprietary; canboat type: LOOKUP";
CM_ SG_ 2381119488 Unique_ID "canboat type: UINT8";
CM_ SG_ 2381119488 Number_of_Selection_Pairs "canboat type: UINT8";
CM_ SG_ 2381119488 Number_of_Parameters "canboat type: UINT8";
CM_ SG_ 2381119488 field72 "canboat type: NUMBER";
CM_ SG_ 2381119488 field80 "canboat type: NUMBER";
CM_ SG_ 2582511616 Function_Code "canboat type: LOOKUP";
CM_ SG_ 2582511616 field8 "canboat type: NUMBER";
VAL_ 2633977856 Manufacturer_Code 69 "ARKS Enterprises" 78 "FW Murphy/Enovation Controls" 80 "Twin Disc" 85 "Kohler Power Systems" 88 "Hemisphere GPS" 135 "Airmar" 137 "Maretron" 140 "Lowrance" 144 "Mercury Marine" 147 "Nautibus Electronic" 148 "Blue Water Data" 154 "Westerbeke" 157 "ISSPRO" 161 "Offshore Systems (UK)" 163 "Evinrude/BRP" 165 "CPAC Systems" 168 "Xantrex Technology" 169 "Marlin Technologies" 172 "Yanmar Marine" 174 "Volvo Penta" 176 "Carling Technologies Inc. (Moritz Aerospace)" 185 "Beede Instruments" 192 "Floscan Instrument" 193 "Nobeltec" 198 "Mystic Valley Communications" 199 "Actia" 201 "Disenos Y Technologia" 211 "Digital Switching Systems" 215 "Xintex/Atena" 224 "EMMI NETWORK" 228 "ZF" 229 "Garmin" 233 "Yacht Monitoring Solutions" 235 "Sailormade Marine Telemetry/Tetra Technology" 243 "Eride" 257 "Honda Motor" 272 "Groco" 273 "Actisense" 274 "Amphenol LTW Technology" 275 "Navico" 283 "Hamilton Jet" 285 "Sea Recovery" 286 "Coelmo SRL Italy" 295 "BEP Marine" 304 "Empir Bus" 305 "NovAtel" 306 "Sleipner Motor" 307 "MBW Technologies" 315 "ICOM" 328 "Qwerty" 329 "Dief" 341 "Boening Automationstechnologie" 345 "Korean Maritime University" 351 "Thrane and Thrane" 355 "Mastervolt" 356 "Fischer Panda Generators" 358 "Victron Energy" 370 "Rolls Royce Marine" 373 "Electronic Design" 374 "Northern Lights" 378 "Glendinning" 381 "B & G" 384 "Rose Point Navigation Systems" 385 "Johnson Outdoors Marine Electronics Inc Geonav" 394 "Capi 2" 396 "Beyond Measure" 400 "Livorsi Marine" 404 "ComNav" 409 "Chetco" 419 "Fusion Electronics" 421 "Standard Horizon" 422 "True Heading" 426 "Egersund Marine Electronics" 427 "em-trak Marine Electronics" 431 "Tohatsu Co, JP" 437 "Digital Yacht" 438 "Comar Systems Limited" 440 "Cummins" 443 "VDO (aka Continental-Corporation)" 451 "Parker Hannifin aka Village Marine Tech" 459 "Alltek Marine Electronics" 460 "SAN GIORGIO S.E.I.N" 466 "Veethree Electronics & Marine" 470 "SI-TEX Marine Electronics" 471 "Sea Cross Marine" 475 "GME aka Standard Communications" 476 "Humminbird Marine Electronics" 478 "Ocean Sat" 481 "Chetco Digital Instruments" 493 "Watcheye" 499 "Lcj Capteurs" 502 "Attwood Marine" 503 "Naviop S.R.L." 504 "Vesper Marine" 510 "Marinesoft" 513 "Simarine" 517 "NoLand Engineering" 518 "Transas USA" 529 "National Instruments Korea" 530 "National Marine Electronics Association" 532 "Onwa Marine" 540 "Webasto" 571 "Marinecraft (South Korea)" 573 "McMurdo Group aka Orolia" 578 "Advansea" 579 "KVH" 580 "San Jose Technology" 583 "Yacht Control" 586 "Suzuki Motor" 591 "US Coast Guard" 595 "Ship Module aka Customware" 600 "Aquatic AV" 605 "Aventics" 606 "Intellian" 612 "SamwonIT" 614 "Arlt Tecnologies" 637 "Bavaria Yachts" 641 "Diverse Yacht Services" 644 "Wema U.S.A dba KUS" 658 "Shenzhen Jiuzhou Himunication" 688 "Rockford" 699 "Harman International" 704 "JL Audio" 708 "Lars Thrane" 715 "Autonnic" 717 "Yacht Devices" 734 "REAP Systems" 735 "AEM Performance Electronics" 739 "LxNav" 741 "Littelfuse, Inc (formerly Carling Technologies)" 743 "DaeMyung" 744 "Woosung" 748 "ISOTTA IFRA srl" 773 "Clarion US" 776 "HMI Systems" 777 "Ocean Signal" 778 "Seakeeper" 781 "Poly Planar" 785 "Fischer Panda DE" 795 "Broyda Industries" 796 "Canadian Automotive" 797 "Tides Marine" 798 "Lumishore" 799 "Still Water Designs and Audio" 802 "BJ Technologies (Beneteau)" 803 "Gill Sensors" 811 "Blue Water Desalination" 815 "FLIR" 824 "Undheim Systems" 826 "Lewmar" 838 "TeamSurv" 844 "Fell Marine" 847 "Oceanvolt" 862 "Prospec" 868 "Data Panel" 890 "L3 Technologies" 894 "Rhodan Marine Systems" 896 "Nexfour Solutions" 905 "ASA Electronics" 909 "Marines Co (South Korea)" 911 "Nautic-on" 917 "Sentinel" 929 "JL Marine Systems" 930 "Ecotronix" 944 "Zontisa Marine" 951 "EXOR International" 962 "Timbolier Industries" 963 "TJC Micro" 968 "Cox Powertrain" 969 "Blue Seas" 981 "Kobelt Manufacturing" 992 "Blue Ocean IOT" 997 "Xenta Systems" 999 "Signal K" 1004 "Ultraflex" 1008 "Lintest SmartBoat" 1011 "Soundmax" 1020 "Team Italia Marine (Onyx Marine Automation s.r.l)" 1021 "Entratech" 1022 "ITC" 1029 "The Marine Guardian" 1047 "Sonic" 1051 "ProNav" 1053 "Vetus Maxwell INC." 1056 "Lithium Pros" 1059 "Boatrax" 1062 "Marol Co ltd" 1065 "CALYPSO Instruments" 1066 "Spot Zero Water" 1069 "Lithionics Battery" 1070 "Quick-teck Electronics" 1075 "Uniden America" 1083 "Nauticoncept" 1084 "Shadow-Caster LED lighting" 1085 "Wet Sounds" 1088 "E-T-A Circuit Breakers" 1092 "Scheiber" 1100 "Smart Yachts International Limited" 1109 "Dockmate" 1114 "Bobs Machine" 1118 "L3Harris ASV" 1119 "Balmar" 1120 "Elettromedia" 1127 "Electromaax" 1140 "Across Oceans Systems" 1145 "Kiwi Yachting" 1150 "BSB Artificial Intelligence" 1151 "Orca Technologies" 1154 "TBS Electronics" 1158 "Technoton Electroics" 1160 "MG Energy Systems" 1169 "Sea Machine Robotics" 1171 "Vista Manufacturing" 1183 "Zipwake" 1186 "Sailmon" 1192 "Airmoniq Pro Kft" 1194 "Sierra Marine" 1200 "Xinuo Information Technology (Xiamen)" 1218 "Septentrio" 1233 "NKE Marine Electronics" 1238 "SuperTrack Aps" 1239 "Honda Electronics" 1245 "Raritan Engineering" 1249 "Integrated Power Solutions AG" 1260 "Interactive Technologies" 1283 "LTG-Tech" 1299 "Energy Solutions (UK)" 1300 "WATT Fuel Cell" 1302 "Pro Mainer" 1305 "Dragonfly Energy" 1306 "Koden Electronics" 1311 "Humphree" 1316 "Hinkley Yachts" 1317 "Global Marine Management GmbH (GMM)" 1320 "Triskel Marine" 1330 "Warwick Control Technologies" 1331 "Dolphin Charger" 1337 "Barnacle Systems" 1348 "Radian IoT" 1353 "Ocean LED Marine" 1359 "BluNav" 1361 "OVA (Nantong Saiyang Electronics Co., Ltd)" 1368 "RAD Propulsion" 1369 "Electric Yacht" 1372 "Elco Motor Yachts" 1384 "Tecnoseal Foundry S.r.l" 1385 "Pro Charging Systems" 1389 "EVEX" 1398 "Gobius Sensor Technology" 1403 "Arco Marine" 1408 "Lenco Marine" 1413 "Naocontrol" 1417 "Revatek" 1438 "Aeolionics" 1439 "PredictWind" 1440 "Egis Mobile Electric" 1445 "Starboard Yacht Group" 1446 "Roswell Marine" 1451 "ePropulsion (Guangdong ePropulsion Technology Ltd.)" 1452 "Micro-Air" 1453 "Vital Battery" 1458 "Ride Controller" 1460 "Tocaro Blue" 1461 "Vanquish Yachts" 1471 "FT Technologies" 1478 "Alps Alpine" 1481 "E-Force Marine" 1482 "CMC Marine" 1483 "Nanjing Sandemarine Information Technology" 1850 "Teleflex Marine (SeaStar Solutions)" 1851 "Raymarine" 1852 "Navionics" 1853 "Japan Radio" 1854 "Northstar Technologies" 1855 "Furuno" 1856 "Trimble" 1857 "Simrad" 1858 "Litton" 1859 "Kvasar" 1860 "MMP" 1861 "Vector Cantech" 1862 "Yamaha Marine" 1863 "Faria Instruments" ;
VAL_ 2633977856 Industry_Code 0 "Global" 1 "Highway" 2 "Agriculture" 3 "Construction" 4 "Marine Industry" 5 "Industrial" ;
VAL_ 2566869248 Manufacturer_Code 69 "ARKS Enterprises" 78 "FW Murphy/Enovation Controls" 80 "Twin Disc" 85 "Kohler Power Systems" 88 "Hemisphere GPS" 135 "Airmar" 137 "Maretron" 140 "Lowrance" 144 "Mercury Marine" 147 "Nautibus Electronic" 148 "Blue Water Data" 154 "Westerbeke" 157 "ISSPRO" 161 "Offshore Systems (UK)" 163 "Evinrude/BRP" 165 "CPAC Systems" 168 "Xantrex Technology" 169 "Marlin Technologies" 172 "Yanmar Marine" 174 "Volvo Penta" 176 "Carling Technologies Inc. (Moritz Aerospace)" 185 "Beede Instruments" 192 "Floscan Instrument" 193 "Nobeltec" 198 "Mystic Valley Communications" 199 "Actia" 201 "Disenos Y Technologia" 211 "Digital Switching Systems" 215 "Xintex/Atena" 224 "EMMI NETWORK" 228 "ZF" 229 "Garmin" 233 "Yacht Monitoring Solutions" 235 "Sailormade Marine Telemetry/Tetra Technology" 243 "Eride" 257 "Honda Motor" 272 "Groco" 273 "Actisense" 274 "Amphenol LTW Technology" 275 "Navico" 283 "Hamilton Jet" 285 "Sea Recovery" 286 "Coelmo SRL Italy" 295 "BEP Marine" 304 "Empir Bus" 305 "NovAtel" 306 "Sleipner Motor" 307 "MBW Technologies" 315 "ICOM" 328 "Qwerty" 329 "Dief" 341 "Boening Automationstechnologie" 345 "Korean Maritime University" 351 "Thrane and Thrane" 355 "Mastervolt" 356 "Fischer Panda Generators" 358 "Victron Energy" 370 "Rolls Royce Marine" 373 "Electronic Design" 374 "Northern Lights" 378 "Glendinning" 381 "B & G" 384 "Rose Point Navigation Systems" 385 "Johnson Outdoors Marine Electronics Inc Geonav" 394 "Capi 2" 396 "Beyond Measure" 400 "Livorsi Marine" 404 "ComNav" 409 "Chetco" 419 "Fusion Electronics" 421 "Standard Horizon" 422 "True Heading" 426 "Egersund Marine Electronics" 427 "em-trak Marine Electronics" 431 "Tohatsu Co, JP" 437 "Digital Yacht" 438 "Comar Systems Limited" 440 "Cummins" 443 "VDO (aka Continental-Corporation)" 451 "Parker Hannifin aka Village Marine Tech" 459 "Alltek Marine Electronics" 460 "SAN GIORGIO S.E.I.N" 466 "Veethree Electronics & Marine" 470 "SI-TEX Marine Electronics" 471 "Sea Cross Marine" 475 "GME aka Standard Communications" 476 "Humminbird Marine Electronics" 478 "Ocean Sat" 481 "Chetco Digital Instruments" 493 "Watcheye" 499 "Lcj Capteurs" 502 "Attwood Marine" 503 "Naviop S.R.L." 504 "Vesper Marine" 510 "Marinesoft" 513 "Simarine" 517 "NoLand Engineering" 518 "Transas USA" 529 "National Instruments Korea" 530 "National Marine Electronics Association" 532 "Onwa Marine" 540 "Webasto" 571 "Marinecraft (South Korea)" 573 "McMurdo Group aka Orolia" 578 "Advansea" 579 "KVH" 580 "San Jose Technology" 583 "Yacht Control" 586 "Suzuki Motor" 591 "US Coast Guard" 595 "Ship Module aka Customware" 600 "Aquatic AV" 605 "Aventics" 606 "Intellian" 612 "SamwonIT" 614 "Arlt Tecnologies" 637 "Bavaria Yachts" 641 "Diverse Yacht Services" 644 "Wema U.S.A dba KUS" 658 "Shenzhen Jiuzhou Himunication" 688 "Rockford" 699 "Harman International" 704 "JL Audio" 708 "Lars Thrane" 715 "Autonnic" 717 "Yacht Devices" 734 "REAP Systems" 735 "AEM Performance Electronics" 739 "LxNav" 741 "Littelfuse, Inc (formerly Carling Technologies)" 743 "DaeMyung" 744 "Woosung" 748 "ISOTTA IFRA srl" 773 "Clarion US" 776 "HMI Systems" 777 "Ocean Signal" 778 "Seakeeper" 781 "Poly Planar" 785 "Fischer Panda DE" 795 "Broyda Industries" 796 "Canadian Automotive" 797 "Tides Marine" 798 "Lumishore" 799 "Still Water Designs and Audio" 802 "BJ Technologies (Beneteau)" 803 "Gill Sensors" 811 "Blue Water Desalination" 815 "FLIR" 824 "Undheim Systems" 826 "Lewmar" 838 "TeamSurv" 844 "Fell Marine" 847 "Oceanvolt" 862 "Prospec" 868 "Data Panel" 890 "L3 Technologies" 894 "Rhodan Marine Systems" 896 "Nexfour Solutions" 905 "ASA Electronics" 909 "Marines Co (South Korea)" 911 "Nautic-on" 917 "Sentinel" 929 "JL Marine Systems" 930 "Ecotronix" 944 "Zontisa Marine" 951 "EXOR International" 962 "Timbolier Industries" 963 "TJC Micro" 968 "Cox Powertrain" 969 "Blue Seas" 981 "Kobelt Manufacturing" 992 "Blue Ocean IOT" 997 "Xenta Systems" 999 "Signal K" 1004 "Ultraflex" 1008 "Lintest SmartBoat" 1011 "Soundmax" 1020 "Team Italia Marine (Onyx Marine Automation s.r.l)" 1021 "Entratech" 1022 "ITC" 1029 "The Marine Guardian" 1047 "Sonic" 1051 "ProNav" 1053 "Vetus Maxwell INC." 1056 "Lithium Pros" 1059 "Boatrax" 1062 "Marol Co ltd" 1065 "CALYPSO Instruments" 1066 "Spot Zero Water" 1069 "Lithionics Battery" 1070 "Quick-teck Electronics" 1075 "Uniden America" 1083 "Nauticoncept" 1084 "Shadow-Caster LED lighting" 1085 "Wet Sounds" 1088 "E-T-A Circuit Breakers" 1092 "Scheiber" 1100 "Smart Yachts International Limited" 1109 "Dockmate" 1114 "Bobs Machine" 1118 "L3Harris ASV" 1119 "Balmar" 1120 "Elettromedia" 1127 "Electromaax" 1140 "Across Oceans Systems" 1145 "Kiwi Yachting" 1150 "BSB Artificial Intelligence" 1151 "Orca Technologies" 1154 "TBS Electronics" 1158 "Technoton Electroics" 1160 "MG Energy Systems" 1169 "Sea Machine Robotics" 1171 "Vista Manufacturing" 1183 "Zipwake" 1186 "Sailmon" 1192 "Airmoniq Pro Kft" 1194 "Sierra Marine" 1200 "Xinuo Information Technology (Xiamen)" 1218 "Septentrio" 1233 "NKE Marine Electronics" 1238 "SuperTrack Aps" 1239 "Honda Electronics" 1245 "Raritan Engineering" 1249 "Integrated Power Solutions AG" 1260 "Interactive Technologies" 1283 "LTG-Tech" 1299 "Energy Solutions (UK)" 1300 "WATT Fuel Cell" 1302 "Pro Mainer" 1305 "Dragonfly Energy" 1306 "Koden Electronics" 1311 "Humphree" 1316 "Hinkley Yachts" 1317 "Global Marine Management GmbH (GMM)" 1320 "Triskel Marine" 1330 "Warwick Control Technologies" 1331 "Dolphin Charger" 1337 "Barnacle Systems" 1348 "Radian IoT" 1353 "Ocean LED Marine" 1359 "BluNav" 1361 "OVA (Nantong Saiyang Electronics Co., Ltd)" 1368 "RAD Propulsion" 1369 "Electric Yacht" 1372 "Elco Motor Yachts" 1384 "Tecnoseal Foundry S.r.l" 1385 "Pro Charging Systems" 1389 "EVEX" 1398 "Gobius Sensor Technology" 1403 "Arco Marine" 1408 "Lenco Marine" 1413 "Naocontrol" 1417 "Revatek" 1438 "Aeolionics" 1439 "PredictWind" 1440 "Egis Mobile Electric" 1445 "Starboard Yacht Group" 1446 "Roswell Marine" 1451 "ePropulsion (Guangdong ePropulsion Technology Ltd.)" 1452 "Micro-Air" 1453 "Vital Battery" 1458 "Ride Controller" 1460 "Tocaro Blue" 1461 "Vanquish Yachts" 1471 "FT Technologies" 1478 "Alps Alpine" 1481 "E-Force Marine" 1482 "CMC Marine" 1483 "Nanjing Sandemarine Information Technology" 1850 "Teleflex Marine (SeaStar Solutions)" 1851 "Raymarine" 1852 "Navionics" 1853 "Japan Radio" 1854 "Northstar Technologies" 1855 "Furuno" 1856 "Trimble" 1857 "Simrad" 1858 "Litton" 1859 "Kvasar" 1860 "MMP" 1861 "Vector Cantech" 1862 "Yamaha Marine" 1863 "Faria Instruments" ;
VAL_ 2566869248 Industry_Code 0 "Global" 1 "Highway" 2 "Agriculture" 3 "Construction" 4 "Marine Industry" 5 "Industrial" ;
VAL_ 2566869248 Alarm_ID 0 "No Alarm" 1 "Shallow Depth" 2 "Deep Depth" 3 "Shallow Anchor" 4 "Deep Anchor" 5 "Off Course" 6 "AWA High" 7 "AWA Low" 8 "AWS High" 9 "AWS Low" 10 "TWA High" 11 "TWA Low" 12 "TWS High" 13 "TWS Low" 14 "WP Arrival" 15 "Boat Speed High" 16 "Boat Speed Low" 17 "Sea Temperature High" 18 "Sea Temperature Low" 19 "Pilot Watch" 20 "Pilot Off Course" 21 "Pilot Wind Shift" 22 "Pilot Low Battery" 23 "Pilot Last Minute Of Watch" 24 "Pilot No NMEA Data" 25 "Pilot Large XTE" 26 "Pilot NMEA DataError" 27 "Pilot CU Disconnected" 28 "Pilot Auto Release" 29 "Pilot Way Point Advance" 30 "Pilot Drive Stopped" 31 "Pilot Type Unspecified" 32 "Pilot Calibration Required" 33 "Pilot Last Heading" 34 "Pilot No Pilot" 35 "Pilot Route Complete" 36 "Pilot Variable Text" 37 "GPS Failure" 38 "MOB" 39 "Seatalk1 Anchor" 40 "Pilot Swapped Motor Power" 41 "Pilot Standby Too Fast To Fish" 42 "Pilot No GPS Fix" 43 "Pilot No GPS COG" 44 "Pilot Start Up" 45 "Pilot Too Slow" 46 "Pilot No Compass" 47 "Pilot Rate Gyro Fault" 48 "Pilot Current Limit" 49 "Pilot Way Point Advance Port" 50 "Pilot Way Point Advance Stbd" 51 "Pilot No Wind Data" 52 "Pilot No Speed Data" 53 "Pilot Seatalk Fail1" 54 "Pilot Seatalk Fail2" 55 "Pilot Warning Too Fast To Fish" 56 "Pilot Auto Dockside Fail" 57 "Pilot Turn Too Fast" 58 "Pilot No Nav Data" 59 "Pilot Lost Waypoint Data" 60 "Pilot EEPROM Corrupt" 61 "Pilot Rudder Feedback Fail" 62 "Pilot Autolearn Fail1" 63 "Pilot Autolearn Fail2" 64 "Pilot Autolearn Fail3" 65 "Pilot Autolearn Fail4" 66 "Pilot Autolearn Fail5" 67 "Pilot Autolearn Fail6" 68 "Pilot Warning Cal Required" 69 "Pilot Warning OffCourse" 70 "Pilot Warning XTE" 71 "Pilot Warning Wind Shift" 72 "Pilot Warning Drive Short" 73 "Pilot Warning Clutch Short" 74 "Pilot Warning Solenoid Short" 75 "Pilot Joystick Fault" 76 "Pilot No Joystick Data" 80 "Pilot Invalid Command" 81 "AIS TX Malfunction" 82 "AIS Antenna VSWR fault" 83 "AIS Rx channel 1 malfunction" 84 "AIS Rx channel 2 malfunction" 85 "AIS No sensor position in use" 86 "AIS No valid SOG information" 87 "AIS No valid COG information" 88 "AIS 12V alarm" 89 "AIS 6V alarm" 90 "AIS Noise threshold exceeded channel A" 91 "AIS Noise threshold exceeded channel B" 92 "AIS Transmitter PA fault" 93 "AIS 3V3 alarm" 94 "AIS Rx channel 70 malfunction" 95 "AIS Heading lost/invalid" 96 "AIS internal GPS lost" 97 "AIS No sensor position" 98 "AIS Lock failure" 99 "AIS Internal GGA timeout" 100 "AIS Protocol stack restart" 101 "Pilot No IPS communications" 102 "Pilot Power-On or Sleep-Switch Reset While Engaged" 103 "Pilot Unexpected Reset While Engaged" 104 "AIS Dangerous Target" 105 "AIS Lost Target" 106 "AIS Safety Related Message (used to silence)" 107 "AIS Connection Lost" 108 "No Fix" 112 "Pilot Compass Calibration Complete" 113 "AIS Transmitter Disabled - MMSI Required" 122 "Bluetooth Device Low Battery" 123 "Bluetooth Device Sleep Mode" 124 "Bluetooth Device High Battery Temperature" 125 "Bluetooth Device Lost Communications" ;
VAL_ 2566869248 Alarm_Group 0 "Instrument" 1 "Autopilot" 2 "Radar" 3 "Chart Plotter" 4 "AIS" 5 "Bluetooth Accessory" ;
VAL_ 2566871808 Manufacturer_Code 69 "ARKS Enterprises" 78 "FW Murphy/Enovation Controls" 80 "Twin Disc" 85 "Kohler Power Systems" 88 "Hemisphere GPS" 135 "Airmar" 137 "Maretron" 140 "Lowrance" 144 "Mercury Marine" 147 "Nautibus Electronic" 148 "Blue Water Data" 154 "Westerbeke" 157 "ISSPRO" 161 "Offshore Systems (UK)" 163 "Evinrude/BRP" 165 "CPAC Systems" 168 "Xantrex Technology" 169 "Marlin Technologies" 172 "Yanmar Marine" 174 "Volvo Penta" 176 "Carling Technologies Inc. (Moritz Aerospace)" 185 "Beede Instruments" 192 "Floscan Instrument" 193 "Nobeltec" 198 "Mystic Valley Communications" 199 "Actia" 201 "Disenos Y Technologia" 211 "Digital Switching Systems" 215 "Xintex/Atena" 224 "EMMI NETWORK" 228 "ZF" 229 "Garmin" 233 "Yacht Monitoring Solutions" 235 "Sailormade Marine Telemetry/Tetra Technology" 243 "Eride" 257 "Honda Motor" 272 "Groco" 273 "Actisense" 274 "Amphenol LTW Technology" 275 "Navico" 283 "Hamilton Jet" 285 "Sea Recovery" 286 "Coelmo SRL Italy" 295 "BEP Marine" 304 "Empir Bus" 305 "NovAtel" 306 "Sleipner Motor" 307 "MBW Technologies" 315 "ICOM" 328 "Qwerty" 329 "Dief" 341 "Boening Automationstechnologie" 345 "Korean Maritime University" 351 "Thrane and Thrane" 355 "Mastervolt" 356 "Fischer Panda Generators" 358 "Victron Energy" 370 "Rolls Royce Marine" 373 "Electronic Design" 374 "Northern Lights" 378 "Glendinning" 381 "B & G" 384 "Rose Point Navigation Systems" 385 "Johnson Outdoors Marine Electronics Inc Geonav" 394 "Capi 2" 396 "Beyond Measure" 400 "Livorsi Marine" 404 "ComNav" 409 "Chetco" 419 "Fusion Electronics" 421 "Standard Horizon" 422 "True Heading" 426 "Egersund Marine Electronics" 427 "em-trak Marine Electronics" 431 "Tohatsu Co, JP" 437 "Digital Yacht" 438 "Comar Systems Limited" 440 "Cummins" 443 "VDO (aka Continental-Corporation)" 451 "Parker Hannifin aka Village Marine Tech" 459 "Alltek Marine Electronics" 460 "SAN GIORGIO S.E.I.N" 466 "Veethree Electronics & Marine" 470 "SI-TEX Marine Electronics" 471 "Sea Cross Marine" 475 "GME aka Standard Communications" 476 "Humminbird Marine Electronics" 478 "Ocean Sat" 481 "Chetco Digital Instruments" 493 "Watcheye" 499 "Lcj Capteurs" 502 "Attwood Marine" 503 "Naviop S.R.L." 504 "Vesper Marine" 510 "Marinesoft" 513 "Simarine" 517 "NoLand Engineering" 518 "Transas USA" 529 "National Instruments Korea" 530 "National Marine Electronics Association" 532 "Onwa Marine" 540 "Webasto" 571 "Marinecraft (South Korea)" 573 "McMurdo Group aka Orolia" 578 "Advansea" 579 "KVH" 580 "San Jose Technology" 583 "Yacht Control" 586 "Suzuki Motor" 591 "US Coast Guard" 595 "Ship Module aka Customware" 600 "Aquatic AV" 605 "Aventics" 606 "Intellian" 612 "SamwonIT" 614 "Arlt Tecnologies" 637 "Bavaria Yachts" 641 "Diverse Yacht Services" 644 "Wema U.S.A dba KUS" 658 "Shenzhen Jiuzhou Himunication" 688 "Rockford" 699 "Harman International" 704 "JL Audio" 708 "Lars Thrane" 715 "Autonnic" 717 "Yacht Devices" 734 "REAP Systems" 735 "AEM Performance Electronics" 739 "LxNav" 741 "Littelfuse, Inc (formerly Carling Technologies)" 743 "DaeMyung" 744 "Woosung" 748 "ISOTTA IFRA srl" 773 "Clarion US" 776 "HMI Systems" 777 "Ocean Signal" 778 "Seakeeper" 781 "Poly Planar" 785 "Fischer Panda DE" 795 "Broyda Industries" 796 "Canadian Automotive" 797 "Tides Marine" 798 "Lumishore" 799 "Still Water Designs and Audio" 802 "BJ Technologies (Beneteau)" 803 "Gill Sensors" 811 "Blue Water Desalination" 815 "FLIR" 824 "Undheim Systems" 826 "Lewmar" 838 "TeamSurv" 844 "Fell Marine" 847 "Oceanvolt" 862 "Prospec" 868 "Data Panel" 890 "L3 Technologies" 894 "Rhodan Marine Systems" 896 "Nexfour Solutions" 905 "ASA Electronics" 909 "Marines Co (South Korea)" 911 "Nautic-on" 917 "Sentinel" 929 "JL Marine Systems" 930 "Ecotronix" 944 "Zontisa Marine" 951 "EXOR International" 962 "Timbolier Industries" 963 "TJC Micro" 968 "Cox Powertrain" 969 "Blue Seas" 981 "Kobelt Manufacturing" 992 "Blue Ocean IOT" 997 "Xenta Systems" 999 "Signal K" 1004 "Ultraflex" 1008 "Lintest SmartBoat" 1011 "Soundmax" 1020 "Team Italia Marine (Onyx Marine Automation s.r.l)" 1021 "Entratech" 1022 "ITC" 1029 "The Marine Guardian" 1047 "Sonic" 1051 "ProNav" 1053 "Vetus Maxwell INC." 1056 "Lithium Pros" 1059 "Boatrax" 1062 "Marol Co ltd" 1065 "CALYPSO Instruments" 1066 "Spot Zero Water" 1069 "Lithionics Battery" 1070 "Quick-teck Electronics" 1075 "Uniden America" 1083 "Nauticoncept" 1084 "Shadow-Caster LED lighting" 1085 "Wet Sounds" 1088 "E-T-A Circuit Breakers" 1092 "Scheiber" 1100 "Smart Yachts International Limited" 1109 "Dockmate" 1114 "Bobs Machine" 1118 "L3Harris ASV" 1119 "Balmar" 1120 "Elettromedia" 1127 "Electromaax" 1140 "Across Oceans Systems" 1145 "Kiwi Yachting" 1150 "BSB Artificial Intelligence" 1151 "Orca Technologies" 1154 "TBS Electronics" 1158 "Technoton Electroics" 1160 "MG Energy Systems" 1169 "Sea Machine Robotics" 1171 "Vista Manufacturing" 1183 "Zipwake" 1186 "Sailmon" 1192 "Airmoniq Pro Kft" 1194 "Sierra Marine" 1200 "Xinuo Information Technology (Xiamen)" 1218 "Septentrio" 1233 "NKE Marine Electronics" 1238 "SuperTrack Aps" 1239 "Honda Electronics" 1245 "Raritan Engineering" 1249 "Integrated Power Solutions AG" 1260 "Interactive Technologies" 1283 "LTG-Tech" 1299 "Energy Solutions (UK)" 1300 "WATT Fuel Cell" 1302 "Pro Mainer" 1305 "Dragonfly Energy" 1306 "Koden Electronics" 1311 "Humphree" 1316 "Hinkley Yachts" 1317 "Global Marine Management GmbH (GMM)" 1320 "Triskel Marine" 1330 "Warwick Control Technologies" 1331 "Dolphin Charger" 1337 "Barnacle Systems" 1348 "Radian IoT" 1353 "Ocean LED Marine" 1359 "BluNav" 1361 "OVA (Nantong Saiyang Electronics Co., Ltd)" 1368 "RAD Propulsion" 1369 "Electric Yacht" 1372 "Elco Motor Yachts" 1384 "Tecnoseal Foundry S.r.l" 1385 "Pro Charging Systems" 1389 "EVEX" 1398 "Gobius Sensor Technology" 1403 "Arco Marine" 1408 "Lenco Marine" 1413 "Naocontrol" 1417 "Revatek" 1438 "Aeolionics" 1439 "PredictWind" 1440 "Egis Mobile Electric" 1445 "Starboard Yacht Group" 1446 "Roswell Marine" 1451 "ePropulsion (Guangdong ePropulsion Technology Ltd.)" 1452 "Micro-Air" 1453 "Vital Battery" 1458 "Ride Controller" 1460 "Tocaro Blue" 1461 "Vanquish Yachts" 1471 "FT Technologies" 1478 "Alps Alpine" 1481 "E-Force Marine" 1482 "CMC Marine" 1483 "Nanjing Sandemarine Information Technology" 1850 "Teleflex Marine (SeaStar Solutions)" 1851 "Raymarine" 1852 "Navionics" 1853 "Japan Radio" 1854 "Northstar Technologies" 1855 "Furuno" 1856 "Trimble" 1857 "Simrad" 1858 "Litton" 1859 "Kvasar" 1860 "MMP" 1861 "Vector Cantech" 1862 "Yamaha Marine" 1863 "Faria Instruments" ;
VAL_ 2566871808 Industry_Code 0 "Global" 1 "Highway" 2 "Agriculture" 3 "Construction" 4 "Marine Industry" 5 "Industrial" ;
VAL_ 2566872576 Manufacturer_Code 69 "ARKS Enterprises" 78 "FW Murphy/Enovation Controls" 80 "Twin Disc" 85 "Kohler Power Systems" 88 "Hemisphere GPS" 135 "Airmar" 137 "Maretron" 140 "Lowrance" 144 "Mercury Marine" 147 "Nautibus Electronic" 148 "Blue Water Data" 154 "Westerbeke" 157 "ISSPRO" 161 "Offshore Systems (UK)" 163 "Evinrude/BRP" 165 "CPAC Systems" 168 "Xantrex Technology" 169 "Marlin Technologies" 172 "Yanmar Marine" 174 "Volvo Penta" 176 "Carling Technologies Inc. (Moritz Aerospace)" 185 "Beede Instruments" 192 "Floscan Instrument" 193 "Nobeltec" 198 "Mystic Valley Communications" 199 "Actia" 201 "Disenos Y Technologia" 211 "Digital Switching Systems" 215 "Xintex/Atena" 224 "EMMI NETWORK" 228 "ZF" 229 "Garmin" 233 "Yacht Monitoring Solutions" 235 "Sailormade Marine Telemetry/Tetra Technology" 243 "Eride" 257 "Honda Motor" 272 "Groco" 273 "Actisense" 274 "Amphenol LTW Technology" 275 "Navico" 283 "Hamilton Jet" 285 "Sea Recovery" 286 "Coelmo SRL Italy" 295 "BEP Marine" 304 "Empir Bus" 305 "NovAtel" 306 "Sleipner Motor" 307 "MBW Technologies" 315 "ICOM" 328 "Qwerty" 329 "Dief" 341 "Boening Automationstechnologie" 345 "Korean Maritime University" 351 "Thrane and Thrane" 355 "Mastervolt" 356 "Fischer Panda Generators" 358 "Victron Energy" 370 "Rolls Royce Marine" 373 "Electronic Design" 374 "Northern Lights" 378 "Glendinning" 381 "B & G" 384 "Rose Point Navigation Systems" 385 "Johnson Outdoors Marine Electronics Inc Geonav" 394 "Capi 2" 396 "Beyond Measure" 400 "Livorsi Marine" 404 "ComNav" 409 "Chetco" 419 "Fusion Electronics" 421 "Standard Horizon" 422 "True Heading" 426 "Egersund Marine Electronics" 427 "em-trak Marine Electronics" 431 "Tohatsu Co, JP" 437 "Digital Yacht" 438 "Comar Systems Limited" 440 "Cummins" 443 "VDO (aka Continental-Corporation)" 451 "Parker Hannifin aka Village Marine Tech" 459 "Alltek Marine Electronics" 460 "SAN GIORGIO S.E.I.N" 466 "Veethree Electronics & Marine" 470 "SI-TEX Marine Electronics" 471 "Sea Cross Marine" 475 "GME aka Standard Communications" 476 "Humminbird Marine Electronics" 478 "Ocean Sat" 481 "Chetco Digital Instruments" 493 "Watcheye" 499 "Lcj Capteurs" 502 "Attwood Marine" 503 "Naviop S.R.L." 504 "Vesper Marine" 510 "Marinesoft" 513 "Simarine" 517 "NoLand Engineering" 518 "Transas USA" 529 "National Instruments Korea" 530 "National Marine Electronics Association" 532 "Onwa Marine" 540 "Webasto" 571 "Marinecraft (South Korea)" 573 "McMurdo Group aka Orolia" 578 "Advansea" 579 "KVH" 580 "San Jose Technology" 583 "Yacht Control" 586 "Suzuki Motor" 591 "US Coast Guard" 595 "Ship Module aka Customware" 600 "Aquatic AV" 605 "Aventics" 606 "Intellian" 612 "SamwonIT" 614 "Arlt Tecnologies" 637 "Bavaria Yachts" 641 "Diverse Yacht Services" 644 "Wema U.S.A dba KUS" 658 "Shenzhen Jiuzhou Himunication" 688 "Rockford" 699 "Harman International" 704 "JL Audio" 708 "Lars Thrane" 715 "Autonnic" 717 "Yacht Devices" 734 "REAP Systems" 735 "AEM Performance Electronics" 739 "LxNav" 741 "Littelfuse, Inc (formerly Carling Technologies)" 743 "DaeMyung" 744 "Woosung" 748 "ISOTTA IFRA srl" 773 "Clarion US" 776 "HMI Systems" 777 "Ocean Signal" 778 "Seakeeper" 781 "Poly Planar" 785 "Fischer Panda DE" 795 "Broyda Industries" 796 "Canadian Automotive" 797 "Tides Marine" 798 "Lumishore" 799 "Still Water Designs and Audio" 802 "BJ Technologies (Beneteau)" 803 "Gill Sensors" 811 "Blue Water Desalination" 815 "FLIR" 824 "Undheim Systems" 826 "Lewmar" 838 "TeamSurv" 844 "Fell Marine" 847 "Oceanvolt" 862 "Prospec" 868 "Data Panel" 890 "L3 Technologies" 894 "Rhodan Marine Systems" 896 "Nexfour Solutions" 905 "ASA Electronics" 909 "Marines Co (South Korea)" 911 "Nautic-on" 917 "Sentinel" 929 "JL Marine Systems" 930 "Ecotronix" 944 "Zontisa Marine" 951 "EXOR International" 962 "Timbolier Industries" 963 "TJC Micro" 968 "Cox Powertrain" 969 "Blue Seas" 981 "Kobelt Manufacturing" 992 "Blue Ocean IOT" 997 "Xenta Systems" 999 "Signal K" 1004 "Ultraflex" 1008 "Lintest SmartBoat" 1011 "Soundmax" 1020 "Team Italia Marine (Onyx Marine Automation s.r.l)" 1021 "Entratech" 1022 "ITC" 1029 "The Marine Guardian" 1047 "Sonic" 1051 "ProNav" 1053 "Vetus Maxwell INC." 1056 "Lithium Pros" 1059 "Boatrax" 1062 "Marol Co ltd" 1065 "CALYPSO Instruments" 1066 "Spot Zero Water" 1069 "Lithionics Battery" 1070 "Quick-teck Electronics" 1075 "Uniden America" 1083 "Nauticoncept" 1084 "Shadow-Caster LED lighting" 1085 "Wet Sounds" 1088 "E-T-A Circuit Breakers" 1092 "Scheiber" 1100 "Smart Yachts International Limited" 1109 "Dockmate" 1114 "Bobs Machine" 1118 "L3Harris ASV" 1119 "Balmar" 1120 "Elettromedia" 1127 "Electromaax" 1140 "Across Oceans Systems" 1145 "Kiwi Yachting" 1150 "BSB Artificial Intelligence" 1151 "Orca Technologies" 1154 "TBS Electronics" 1158 "Technoton Electroics" 1160 "MG Energy Systems" 1169 "Sea Machine Robotics" 1171 "Vista Manufacturing" 1183 "Zipwake" 1186 "Sailmon" 1192 "Airmoniq Pro Kft" 1194 "Sierra Marine" 1200 "Xinuo Information Technology (Xiamen)" 1218 "Septentrio" 1233 "NKE Marine Electronics" 1238 "SuperTrack Aps" 1239 "Honda Electronics" 1245 "Raritan Engineering" 1249 "Integrated Power Solutions AG" 1260 "Interactive Technologies" 1283 "LTG-Tech" 1299 "Energy Solutions (UK)" 1300 "WATT Fuel Cell" 1302 "Pro Mainer" 1305 "Dragonfly Energy" 1306 "Koden Electronics" 1311 "Humphree" 1316 "Hinkley Yachts" 1317 "Global Marine Management GmbH (GMM)" 1320 "Triskel Marine" 1330 "Warwick Control Technologies" 1331 "Dolphin Charger" 1337 "Barnacle Systems" 1348 "Radian IoT" 1353 "Ocean LED Marine" 1359 "BluNav" 1361 "OVA (Nantong Saiyang Electronics Co., Ltd)" 1368 "RAD Propulsion" 1369 "Electric Yacht" 1372 "Elco Motor Yachts" 1384 "Tecnoseal Foundry S.r.l" 1385 "Pro Charging Systems" 1389 "EVEX" 1398 "Gobius Sensor Technology" 1403 "Arco Marine" 1408 "Lenco Marine" 1413 "Naocontrol" 1417 "Revatek" 1438 "Aeolionics" 1439 "PredictWind" 1440 "Egis Mobile Electric" 1445 "Starboard Yacht Group" 1446 "Roswell Marine" 1451 "ePropulsion (Guangdong ePropulsion Technology Ltd.)" 1452 "Micro-Air" 1453 "Vital Battery" 1458 "Ride Controller" 1460 "Tocaro Blue" 1461 "Vanquish Yachts" 1471 "FT Technologies" 1478 "Alps Alpine" 1481 "E-Force Marine" 1482 "CMC Marine" 1483 "Nanjing Sandemarine Information Technology" 1850 "Teleflex Marine (SeaStar Solutions)" 1851 "Raymarine" 1852 "Navionics" 1853 "Japan Radio" 1854 "Northstar Technologies" 1855 "Furuno" 1856 "Trimble" 1857 "Simrad" 1858 "Litton" 1859 "Kvasar" 1860 "MMP" 1861 "Vector Cantech" 1862 "Yamaha Marine" 1863 "Faria Instruments" ;
VAL_ 2566872576 Industry_Code 0 "Global" 1 "Highway" 2 "Agriculture" 3 "Construction" 4 "Marine Industry" 5 "Industrial" ;
VAL_ 2633982720 Manufacturer_Code 69 "ARKS Enterprises" 78 "FW Murphy/Enovation Controls" 80 "Twin Disc" 85 "Kohler Power Systems" 88 "Hemisphere GPS" 135 "Airmar" 137 "Maretron" 140 "Lowrance" 144 "Mercury Marine" 147 "Nautibus Electronic" 148 "Blue Water Data" 154 "Westerbeke" 157 "ISSPRO" 161 "Offshore Systems (UK)" 163 "Evinrude/BRP" 165 "CPAC Systems" 168 "Xantrex Technology" 169 "Marlin Technologies" 172 "Yanmar Marine" 174 "Volvo Penta" 176 "Carling Technologies Inc. (Moritz Aerospace)" 185 "Beede Instruments" 192 "Floscan Instrument" 193 "Nobeltec" 198 "Mystic Valley Communications" 199 "Actia" 201 "Disenos Y Technologia" 211 "Digital Switching Systems" 215 "Xintex/Atena" 224 "EMMI NETWORK" 228 "ZF" 229 "Garmin" 233 "Yacht Monitoring Solutions" 235 "Sailormade Marine Telemetry/Tetra Technology" 243 "Eride" 257 "Honda Motor" 272 "Groco" 273 "Actisense" 274 "Amphenol LTW Technology" 275 "Navico" 283 "Hamilton Jet" 285 "Sea Recovery" 286 "Coelmo SRL Italy" 295 "BEP Marine" 304 "Empir Bus" 305 "NovAtel" 306 "Sleipner Motor" 307 "MBW Technologies" 315 "ICOM" 328 "Qwerty" 329 "Dief" 341 "Boening Automationstechnologie" 345 "Korean Maritime University" 351 "Thrane and Thrane" 355 "Mastervolt" 356 "Fischer Panda Generators" 358 "Victron Energy" 370 "Rolls Royce Marine" 373 "Electronic Design" 374 "Northern Lights" 378 "Glendinning" 381 "B & G" 384 "Rose Point Navigation Systems" 385 "Johnson Outdoors Marine Electronics Inc Geonav" 394 "Capi 2" 396 "Beyond Measure" 400 "Livorsi Marine" 404 "ComNav" 409 "Chetco" 419 "Fusion Electronics" 421 "Standard Horizon" 422 "True Heading" 426 "Egersund Marine Electronics" 427 "em-trak Marine Electronics" 431 "Tohatsu Co, JP" 437 "Digital Yacht" 438 "Comar Systems Limited" 440 "Cummins" 443 "VDO (aka Continental-Corporation)" 451 "Parker Hannifin aka Village Marine Tech" 459 "Alltek Marine Electronics" 460 "SAN GIORGIO S.E.I.N" 466 "Veethree Electronics & Marine" 470 "SI-TEX Marine Electronics" 471 "Sea Cross Marine" 475 "GME aka Standard Communications" 476 "Humminbird Marine Electronics" 478 "Ocean Sat" 481 "Chetco Digital Instruments" 493 "Watcheye" 499 "Lcj Capteurs" 502 "Attwood Marine" 503 "Naviop S.R.L." 504 "Vesper Marine" 510 "Marinesoft" 513 "Simarine" 517 "NoLand Engineering" 518 "Transas USA" 529 "National Instruments Korea" 530 "National Marine Electronics Association" 532 "Onwa Marine" 540 "Webasto" 571 "Marinecraft (South Korea)" 573 "McMurdo Group aka Orolia" 578 "Advansea" 579 "KVH" 580 "San Jose Technology" 583 "Yacht Control" 586 "Suzuki Motor" 591 "US Coast Guard" 595 "Ship Module aka Customware" 600 "Aquatic AV" 605 "Aventics" 606 "Intellian" 612 "SamwonIT" 614 "Arlt Tecnologies" 637 "Bavaria Yachts" 641 "Diverse Yacht Services" 644 "Wema U.S.A dba KUS" 658 "Shenzhen Jiuzhou Himunication" 688 "Rockford" 699 "Harman International" 704 "JL Audio" 708 "Lars Thrane" 715 "Autonnic" 717 "Yacht Devices" 734 "REAP Systems" 735 "AEM Performance Electronics" 739 "LxNav" 741 "Littelfuse, Inc (formerly Carling Technologies)" 743 "DaeMyung" 744 "Woosung" 748 "ISOTTA IFRA srl" 773 "Clarion US" 776 "HMI Systems" 777 "Ocean Signal" 778 "Seakeeper" 781 "Poly Planar" 785 "Fischer Panda DE" 795 "Broyda Industries" 796 "Canadian Automotive" 797 "Tides Marine" 798 "Lumishore" 799 "Still Water Designs and Audio" 802 "BJ Technologies (Beneteau)" 803 "Gill Sensors" 811 "Blue Water Desalination" 815 "FLIR" 824 "Undheim Systems" 826 "Lewmar" 838 "TeamSurv" 844 "Fell Marine" 847 "Oceanvolt" 862 "Prospec" 868 "Data Panel" 890 "L3 Technologies" 894 "Rhodan Marine Systems" 896 "Nexfour Solutions" 905 "ASA Electronics" 909 "Marines Co (South Korea)" 911 "Nautic-on" 917 "Sentinel" 929 "JL Marine Systems" 930 "Ecotronix" 944 "Zontisa Marine" 951 "EXOR International" 962 "Timbolier Industries" 963 "TJC Micro" 968 "Cox Powertrain" 969 "Blue Seas" 981 "Kobelt Manufacturing" 992 "Blue Ocean IOT" 997 "Xenta Systems" 999 "Signal K" 1004 "Ultraflex" 1008 "Lintest SmartBoat" 1011 "Soundmax" 1020 "Team Italia Marine (Onyx Marine Automation s.r.l)" 1021 "Entratech" 1022 "ITC" 1029 "The Marine Guardian" 1047 "Sonic" 1051 "ProNav" 1053 "Vetus Maxwell INC." 1056 "Lithium Pros" 1059 "Boatrax" 1062 "Marol Co ltd" 1065 "CALYPSO Instruments" 1066 "Spot Zero Water" 1069 "Lithionics Battery" 1070 "Quick-teck Electronics" 1075 "Uniden America" 1083 "Nauticoncept" 1084 "Shadow-Caster LED lighting" 1085 "Wet Sounds" 1088 "E-T-A Circuit Breakers" 1092 "Scheiber" 1100 "Smart Yachts International Limited" 1109 "Dockmate" 1114 "Bobs Machine" 1118 "L3Harris ASV" 1119 "Balmar" 1120 "Elettromedia" 1127 "Electromaax" 1140 "Across Oceans Systems" 1145 "Kiwi Yachting" 1150 "BSB Artificial Intelligence" 1151 "Orca Technologies" 1154 "TBS Electronics" 1158 "Technoton Electroics" 1160 "MG Energy Systems" 1169 "Sea Machine Robotics" 1171 "Vista Manufacturing" 1183 "Zipwake" 1186 "Sailmon" 1192 "Airmoniq Pro Kft" 1194 "Sierra Marine" 1200 "Xinuo Information Technology (Xiamen)" 1218 "Septentrio" 1233 "NKE Marine Electronics" 1238 "SuperTrack Aps" 1239 "Honda Electronics" 1245 "Raritan Engineering" 1249 "Integrated Power Solutions AG" 1260 "Interactive Technologies" 1283 "LTG-Tech" 1299 "Energy Solutions (UK)" 1300 "WATT Fuel Cell" 1302 "Pro Mainer" 1305 "Dragonfly Energy" 1306 "Koden Electronics" 1311 "Humphree" 1316 "Hinkley Yachts" 1317 "Global Marine Management GmbH (GMM)" 1320 "Triskel Marine" 1330 "Warwick Control Technologies" 1331 "Dolphin Charger" 1337 "Barnacle Systems" 1348 "Radian IoT" 1353 "Ocean LED Marine" 1359 "BluNav" 1361 "OVA (Nantong Saiyang Electronics Co., Ltd)" 1368 "RAD Propulsion" 1369 "Electric Yacht" 1372 "Elco Motor Yachts" 1384 "Tecnoseal Foundry S.r.l" 1385 "Pro Charging Systems" 1389 "EVEX" 1398 "Gobius Sensor Technology" 1403 "Arco Marine" 1408 "Lenco Marine" 1413 "Naocontrol" 1417 "Revatek" 1438 "Aeolionics" 1439 "PredictWind" 1440 "Egis Mobile Electric" 1445 "Starboard Yacht Group" 1446 "Roswell Marine" 1451 "ePropulsion (Guangdong ePropulsion Technology Ltd.)" 1452 "Micro-Air" 1453 "Vital Battery" 1458 "Ride Controller" 1460 "Tocaro Blue" 1461 "Vanquish Yachts" 1471 "FT Technologies" 1478 "Alps Alpine" 1481 "E-Force Marine" 1482 "CMC Marine" 1483 "Nanjing Sandemarine Information Technology" 1850 "Teleflex Marine (SeaStar Solutions)" 1851 "Raymarine" 1852 "Navionics" 1853 "Japan Radio" 1854 "Northstar Technologies" 1855 "Furuno" 1856 "Trimble" 1857 "Simrad" 1858 "Litton" 1859 "Kvasar" 1860 "MMP" 1861 "Vector Cantech" 1862 "Yamaha Marine" 1863 "Faria Instruments" ;
VAL_ 2633982720 Industry_Code 0 "Global" 1 "Highway" 2 "Agriculture" 3 "Construction" 4 "Marine Industry" 5 "Industrial" ;
VAL_ 2633982720 Pilot_Mode 0 "Standby" 64 "Auto, compass commanded" 256 "Vane, Wind Mode" 384 "Track Mode" 385 "No Drift, COG referenced (In track, course changes)" ;
VAL_ 2566880000 Manufacturer_Code 69 "ARKS Enterprises" 78 "FW Murphy/Enovation Controls" 80 "Twin Disc" 85 "Kohler Power Systems" 88 "Hemisphere GPS" 135 "Airmar" 137 "Maretron" 140 "Lowrance" 144 "Mercury Marine" 147 "Nautibus Electronic" 148 "Blue Water Data" 154 "Westerbeke" 157 "ISSPRO" 161 "Offshore Systems (UK)" 163 "Evinrude/BRP" 165 "CPAC Systems" 168 "Xantrex Technology" 169 "Marlin Technologies" 172 "Yanmar Marine" 174 "Volvo Penta" 176 "Carling Technologies Inc. (Moritz Aerospace)" 185 "Beede Instruments" 192 "Floscan Instrument" 193 "Nobeltec" 198 "Mystic Valley Communications" 199 "Actia" 201 "Disenos Y Technologia" 211 "Digital Switching Systems" 215 "Xintex/Atena" 224 "EMMI NETWORK" 228 "ZF" 229 "Garmin" 233 "Yacht Monitoring Solutions" 235 "Sailormade Marine Telemetry/Tetra Technology" 243 "Eride" 257 "Honda Motor" 272 "Groco" 273 "Actisense" 274 "Amphenol LTW Technology" 275 "Navico" 283 "Hamilton Jet" 285 "Sea Recovery" 286 "Coelmo SRL Italy" 295 "BEP Marine" 304 "Empir Bus" 305 "NovAtel" 306 "Sleipner Motor" 307 "MBW Technologies" 315 "ICOM" 328 "Qwerty" 329 "Dief" 341 "Boening Automationstechnologie" 345 "Korean Maritime University" 351 "Thrane and Thrane" 355 "Mastervolt" 356 "Fischer Panda Generators" 358 "Victron Energy" 370 "Rolls Royce Marine" 373 "Electronic Design" 374 "Northern Lights" 378 "Glendinning" 381 "B & G" 384 "Rose Point Navigation Systems" 385 "Johnson Outdoors Marine Electronics Inc Geonav" 394 "Capi 2" 396 "Beyond Measure" 400 "Livorsi Marine" 404 "ComNav" 409 "Chetco" 419 "Fusion Electronics" 421 "Standard Horizon" 422 "True Heading" 426 "Egersund Marine Electronics" 427 "em-trak Marine Electronics" 431 "Tohatsu Co, JP" 437 "Digital Yacht" 438 "Comar Systems Limited" 440 "Cummins" 443 "VDO (aka Continental-Corporation)" 451 "Parker Hannifin aka Village Marine Tech" 459 "Alltek Marine Electronics" 460 "SAN GIORGIO S.E.I.N" 466 "Veethree Electronics & Marine" 470 "SI-TEX Marine Electronics" 471 "Sea Cross Marine" 475 "GME aka Standard Communications" 476 "Humminbird Marine Electronics" 478 "Ocean Sat" 481 "Chetco Digital Instruments" 493 "Watcheye" 499 "Lcj Capteurs" 502 "Attwood Marine" 503 "Naviop S.R.L." 504 "Vesper Marine" 510 "Marinesoft" 513 "Simarine" 517 "NoLand Engineering" 518 "Transas USA" 529 "National Instruments Korea" 530 "National Marine Electronics Association" 532 "Onwa Marine" 540 "Webasto" 571 "Marinecraft (South Korea)" 573 "McMurdo Group aka Orolia" 578 "Advansea" 579 "KVH" 580 "San Jose Technology" 583 "Yacht Control" 586 "Suzuki Motor" 591 "US Coast Guard" 595 "Ship Module aka Customware" 600 "Aquatic AV" 605 "Aventics" 606 "Intellian" 612 "SamwonIT" 614 "Arlt Tecnologies" 637 "Bavaria Yachts" 641 "Diverse Yacht Services" 644 "Wema U.S.A dba KUS" 658 "Shenzhen Jiuzhou Himunication" 688 "Rockford" 699 "Harman International" 704 "JL Audio" 708 "Lars Thrane" 715 "Autonnic" 717 "Yacht Devices" 734 "REAP Systems" 735 "AEM Performance Electronics" 739 "LxNav" 741 "Littelfuse, Inc (formerly Carling Technologies)" 743 "DaeMyung" 744 "Woosung" 748 "ISOTTA IFRA srl" 773 "Clarion US" 776 "HMI Systems" 777 "Ocean Signal" 778 "Seakeeper" 781 "Poly Planar" 785 "Fischer Panda DE" 795 "Broyda Industries" 796 "Canadian Automotive" 797 "Tides Marine" 798 "Lumishore" 799 "Still Water Designs and Audio" 802 "BJ Technologies (Beneteau)" 803 "Gill Sensors" 811 "Blue Water Desalination" 815 "FLIR" 824 "Undheim Systems" 826 "Lewmar" 838 "TeamSurv" 844 "Fell Marine" 847 "Oceanvolt" 862 "Prospec" 868 "Data Panel" 890 "L3 Technologies" 894 "Rhodan Marine Systems" 896 "Nexfour Solutions" 905 "ASA Electronics" 909 "Marines Co (South Korea)" 911 "Nautic-on" 917 "Sentinel" 929 "JL Marine Systems" 930 "Ecotronix" 944 "Zontisa Marine" 951 "EXOR International" 962 "Timbolier Industries" 963 "TJC Micro" 968 "Cox Powertrain" 969 "Blue Seas" 981 "Kobelt Manufacturing" 992 "Blue Ocean IOT" 997 "Xenta Systems" 999 "Signal K" 1004 "Ultraflex" 1008 "Lintest SmartBoat" 1011 "Soundmax" 1020 "Team Italia Marine (Onyx Marine Automation s.r.l)" 1021 "Entratech" 1022 "ITC" 1029 "The Marine Guardian" 1047 "Sonic" 1051 "ProNav" 1053 "Vetus Maxwell INC." 1056 "Lithium Pros" 1059 "Boatrax" 1062 "Marol Co ltd" 1065 "CALYPSO Instruments" 1066 "Spot Zero Water" 1069 "Lithionics Battery" 1070 "Quick-teck Electronics" 1075 "Uniden America" 1083 "Nauticoncept" 1084 "Shadow-Caster LED lighting" 1085 "Wet Sounds" 1088 "E-T-A Circuit Breakers" 1092 "Scheiber" 1100 "Smart Yachts International Limited" 1109 "Dockmate" 1114 "Bobs Machine" 1118 "L3Harris ASV" 1119 "Balmar" 1120 "Elettromedia" 1127 "Electromaax" 1140 "Across Oceans Systems" 1145 "Kiwi Yachting" 1150 "BSB Artificial Intelligence" 1151 "Orca Technologies" 1154 "TBS Electronics" 1158 "Technoton Electroics" 1160 "MG Energy Systems" 1169 "Sea Machine Robotics" 1171 "Vista Manufacturing" 1183 "Zipwake" 1186 "Sailmon" 1192 "Airmoniq Pro Kft" 1194 "Sierra Marine" 1200 "Xinuo Information Technology (Xiamen)" 1218 "Septentrio" 1233 "NKE Marine Electronics" 1238 "SuperTrack Aps" 1239 "Honda Electronics" 1245 "Raritan Engineering" 1249 "Integrated Power Solutions AG" 1260 "Interactive Technologies" 1283 "LTG-Tech" 1299 "Energy Solutions (UK)" 1300 "WATT Fuel Cell" 1302 "Pro Mainer" 1305 "Dragonfly Energy" 1306 "Koden Electronics" 1311 "Humphree" 1316 "Hinkley Yachts" 1317 "Global Marine Management GmbH (GMM)" 1320 "Triskel Marine" 1330 "Warwick Control Technologies" 1331 "Dolphin Charger" 1337 "Barnacle Systems" 1348 "Radian IoT" 1353 "Ocean LED Marine" 1359 "BluNav" 1361 "OVA (Nantong Saiyang Electronics Co., Ltd)" 1368 "RAD Propulsion" 1369 "Electric Yacht" 1372 "Elco Motor Yachts" 1384 "Tecnoseal Foundry S.r.l" 1385 "Pro Charging Systems" 1389 "EVEX" 1398 "Gobius Sensor Technology" 1403 "Arco Marine" 1408 "Lenco Marine" 1413 "Naocontrol" 1417 "Revatek" 1438 "Aeolionics" 1439 "PredictWind" 1440 "Egis Mobile Electric" 1445 "Starboard Yacht Group" 1446 "Roswell Marine" 1451 "ePropulsion (Guangdong ePropulsion Technology Ltd.)" 1452 "Micro-Air" 1453 "Vital Battery" 1458 "Ride Controller" 1460 "Tocaro Blue" 1461 "Vanquish Yachts" 1471 "FT Technologies" 1478 "Alps Alpine" 1481 "E-Force Marine" 1482 "CMC Marine" 1483 "Nanjing Sandemarine Information Technology" 1850 "Teleflex Marine (SeaStar Solutions)" 1851 "Raymarine" 1852 "Navionics" 1853 "Japan Radio" 1854 "Northstar Technologies" 1855 "Furuno" 1856 "Trimble" 1857 "Simrad" 1858 "Litton" 1859 "Kvasar" 1860 "MMP" 1861 "Vector Cantech" 1862 "Yamaha Marine" 1863 "Faria Instruments" ;
VAL_ 2566880000 Industry_Code 0 "Global" 1 "Highway" 2 "Agriculture" 3 "Construction" 4 "Marine Industry" 5 "Industrial" ;
VAL_ 2633990144 Manufacturer_Code 69 "ARKS Enterprises" 78 "FW Murphy/Enovation Controls" 80 "Twin Disc" 85 "Kohler Power Systems" 88 "Hemisphere GPS" 135 "Airmar" 137 "Maretron" 140 "Lowrance" 144 "Mercury Marine" 147 "Nautibus Electronic" 148 "Blue Water Data" 154 "Westerbeke" 157 "ISSPRO" 161 "Offshore Systems (UK)" 163 "Evinrude/BRP" 165 "CPAC Systems" 168 "Xantrex Technology" 169 "Marlin Technologies" 172 "Yanmar Marine" 174 "Volvo Penta" 176 "Carling Technologies Inc. (Moritz Aerospace)" 185 "Beede Instruments" 192 "Floscan Instrument" 193 "Nobeltec" 198 "Mystic Valley Communications" 199 "Actia" 201 "Disenos Y Technologia" 211 "Digital Switching Systems" 215 "Xintex/Atena" 224 "EMMI NETWORK" 228 "ZF" 229 "Garmin" 233 "Yacht Monitoring Solutions" 235 "Sailormade Marine Telemetry/Tetra Technology" 243 "Eride" 257 "Honda Motor" 272 "Groco" 273 "Actisense" 274 "Amphenol LTW Technology" 275 "Navico" 283 "Hamilton Jet" 285 "Sea Recovery" 286 "Coelmo SRL Italy" 295 "BEP Marine" 304 "Empir Bus" 305 "NovAtel" 306 "Sleipner Motor" 307 "MBW Technologies" 315 "ICOM" 328 "Qwerty" 329 "Dief" 341 "Boening Automationstechnologie" 345 "Korean Maritime University" 351 "Thrane and Thrane" 355 "Mastervolt" 356 "Fischer Panda Generators" 358 "Victron Energy" 370 "Rolls Royce Marine" 373 "Electronic Design" 374 "Northern Lights" 378 "Glendinning" 381 "B & G" 384 "Rose Point Navigation Systems" 385 "Johnson Outdoors Marine Electronics Inc Geonav" 394 "Capi 2" 396 "Beyond Measure" 400 "Livorsi Marine" 404 "ComNav" 409 "Chetco" 419 "Fusion Electronics" 421 "Standard Horizon" 422 "True Heading" 426 "Egersund Marine Electronics" 427 "em-trak Marine Electronics" 431 "Tohatsu Co, JP" 437 "Digital Yacht" 438 "Comar Systems Limited" 440 "Cummins" 443 "VDO (aka Continental-Corporation)" 451 "Parker Hannifin aka Village Marine Tech" 459 "Alltek Marine Electronics" 460 "SAN GIORGIO S.E.I.N" 466 "Veethree Electronics & Marine" 470 "SI-TEX Marine Electronics" 471 "Sea Cross Marine" 475 "GME aka Standard Communications" 476 "Humminbird Marine Electronics" 478 "Ocean Sat" 481 "Chetco Digital Instruments" 493 "Watcheye" 499 "Lcj Capteurs" 502 "Attwood Marine" 503 "Naviop S.R.L." 504 "Vesper Marine" 510 "Marinesoft" 513 "Simarine" 517 "NoLand Engineering" 518 "Transas USA" 529 "National Instruments Korea" 530 "National Marine Electronics Association" 532 "Onwa Marine" 540 "Webasto" 571 "Marinecraft (South Korea)" 573 "McMurdo Group aka Orolia" 578 "Advansea" 579 "KVH" 580 "San Jose Technology" 583 "Yacht Control" 586 "Suzuki Motor" 591 "US Coast Guard" 595 "Ship Module aka Customware" 600 "Aquatic AV" 605 "Aventics" 606 "Intellian" 612 "SamwonIT" 614 "Arlt Tecnologies" 637 "Bavaria Yachts" 641 "Diverse Yacht Services" 644 "Wema U.S.A dba KUS" 658 "Shenzhen Jiuzhou Himunication" 688 "Rockford" 699 "Harman International" 704 "JL Audio" 708 "Lars Thrane" 715 "Autonnic" 717 "Yacht Devices" 734 "REAP Systems" 735 "AEM Performance Electronics" 739 "LxNav" 741 "Littelfuse, Inc (formerly Carling Technologies)" 743 "DaeMyung" 744 "Woosung" 748 "ISOTTA IFRA srl" 773 "Clarion US" 776 "HMI Systems" 777 "Ocean Signal" 778 "Seakeeper" 781 "Poly Planar" 785 "Fischer Panda DE" 795 "Broyda Industries" 796 "Canadian Automotive" 797 "Tides Marine" 798 "Lumishore" 799 "Still Water Designs and Audio" 802 "BJ Technologies (Beneteau)" 803 "Gill Sensors" 811 "Blue Water Desalination" 815 "FLIR" 824 "Undheim Systems" 826 "Lewmar" 838 "TeamSurv" 844 "Fell Marine" 847 "Oceanvolt" 862 "Prospec" 868 "Data Panel" 890 "L3 Technologies" 894 "Rhodan Marine Systems" 896 "Nexfour Solutions" 905 "ASA Electronics" 909 "Marines Co (South Korea)" 911 "Nautic-on" 917 "Sentinel" 929 "JL Marine Systems" 930 "Ecotronix" 944 "Zontisa Marine" 951 "EXOR International" 962 "Timbolier Industries" 963 "TJC Micro" 968 "Cox Powertrain" 969 "Blue Seas" 981 "Kobelt Manufacturing" 992 "Blue Ocean IOT" 997 "Xenta Systems" 999 "Signal K" 1004 "Ultraflex" 1008 "Lintest SmartBoat" 1011 "Soundmax" 1020 "Team Italia Marine (Onyx Marine Automation s.r.l)" 1021 "Entratech" 1022 "ITC" 1029 "The Marine Guardian" 1047 "Sonic" 1051 "ProNav" 1053 "Vetus Maxwell INC." 1056 "Lithium Pros" 1059 "Boatrax" 1062 "Marol Co ltd" 1065 "CALYPSO Instruments" 1066 "Spot Zero Water" 1069 "Lithionics Battery" 1070 "Quick-teck Electronics" 1075 "Uniden America" 1083 "Nauticoncept" 1084 "Shadow-Caster LED lighting" 1085 "Wet Sounds" 1088 "E-T-A Circuit Breakers" 1092 "Scheiber" 1100 "Smart Yachts International Limited" 1109 "Dockmate" 1114 "Bobs Machine" 1118 "L3Harris ASV" 1119 "Balmar" 1120 "Elettromedia" 1127 "Electromaax" 1140 "Across Oceans Systems" 1145 "Kiwi Yachting" 1150 "BSB Artificial Intelligence" 1151 "Orca Technologies" 1154 "TBS Electronics" 1158 "Technoton Electroics" 1160 "MG Energy Systems" 1169 "Sea Machine Robotics" 1171 "Vista Manufacturing" 1183 "Zipwake" 1186 "Sailmon" 1192 "Airmoniq Pro Kft" 1194 "Sierra Marine" 1200 "Xinuo Information Technology (Xiamen)" 1218 "Septentrio" 1233 "NKE Marine Electronics" 1238 "SuperTrack Aps" 1239 "Honda Electronics" 1245 "Raritan Engineering" 1249 "Integrated Power Solutions AG" 1260 "Interactive Technologies" 1283 "LTG-Tech" 1299 "Energy Solutions (UK)" 1300 "WATT Fuel Cell" 1302 "Pro Mainer" 1305 "Dragonfly Energy" 1306 "Koden Electronics" 1311 "Humphree" 1316 "Hinkley Yachts" 1317 "Global Marine Management GmbH (GMM)" 1320 "Triskel Marine" 1330 "Warwick Control Technologies" 1331 "Dolphin Charger" 1337 "Barnacle Systems" 1348 "Radian IoT" 1353 "Ocean LED Marine" 1359 "BluNav" 1361 "OVA (Nantong Saiyang Electronics Co., Ltd)" 1368 "RAD Propulsion" 1369 "Electric Yacht" 1372 "Elco Motor Yachts" 1384 "Tecnoseal Foundry S.r.l" 1385 "Pro Charging Systems" 1389 "EVEX" 1398 "Gobius Sensor Technology" 1403 "Arco Marine" 1408 "Lenco Marine" 1413 "Naocontrol" 1417 "Revatek" 1438 "Aeolionics" 1439 "PredictWind" 1440 "Egis Mobile Electric" 1445 "Starboard Yacht Group" 1446 "Roswell Marine" 1451 "ePropulsion (Guangdong ePropulsion Technology Ltd.)" 1452 "Micro-Air" 1453 "Vital Battery" 1458 "Ride Controller" 1460 "Tocaro Blue" 1461 "Vanquish Yachts" 1471 "FT Technologies" 1478 "Alps Alpine" 1481 "E-Force Marine" 1482 "CMC Marine" 1483 "Nanjing Sandemarine Information Technology" 1850 "Teleflex Marine (SeaStar Solutions)" 1851 "Raymarine" 1852 "Navionics" 1853 "Japan Radio" 1854 "Northstar Technologies" 1855 "Furuno" 1856 "Trimble" 1857 "Simrad" 1858 "Litton" 1859 "Kvasar" 1860 "MMP" 1861 "Vector Cantech" 1862 "Yamaha Marine" 1863 "Faria Instruments" ;
VAL_ 2633990144 Industry_Code 0 "Global" 1 "Highway" 2 "Agriculture" 3 "Construction" 4 "Marine Industry" 5 "Industrial" ;
VAL_ 2633990144 Depth_Quality_Factor 0 "Depth unlocked" 1 "Quality 10%" 2 "Quality 20%" 3 "Quality 30%" 4 "Quality 40%" 5 "Quality 50%" 6 "Quality 60%" 7 "Quality 70%" 8 "Quality 80%" 9 "Quality 90%" 10 "Quality 100%" ;
VAL_ 2633990400 Manufacturer_Code 69 "ARKS Enterprises" 78 "FW Murphy/Enovation Controls" 80 "Twin Disc" 85 "Kohler Power Systems" 88 "Hemisphere GPS" 135 "Airmar" 137 "Maretron" 140 "Lowrance" 144 "Mercury Marine" 147 "Nautibus Electronic" 148 "Blue Water Data" 154 "Westerbeke" 157 "ISSPRO" 161 "Offshore Systems (UK)" 163 "Evinrude/BRP" 165 "CPAC Systems" 168 "Xantrex Technology" 169 "Marlin Technologies" 172 "Yanmar Marine" 174 "Volvo Penta" 176 "Carling Technologies Inc. (Moritz Aerospace)" 185 "Beede Instruments" 192 "Floscan Instrument" 193 "Nobeltec" 198 "Mystic Valley Communications" 199 "Actia" 201 "Disenos Y Technologia" 211 "Digital Switching Systems" 215 "Xintex/Atena" 224 "EMMI NETWORK" 228 "ZF" 229 "Garmin" 233 "Yacht Monitoring Solutions" 235 "Sailormade Marine Telemetry/Tetra Technology" 243 "Eride" 257 "Honda Motor" 272 "Groco" 273 "Actisense" 274 "Amphenol LTW Technology" 275 "Navico" 283 "Hamilton Jet" 285 "Sea Recovery" 286 "Coelmo SRL Italy" 295 "BEP Marine" 304 "Empir Bus" 305 "NovAtel" 306 "Sleipner Motor" 307 "MBW Technologies" 315 "ICOM" 328 "Qwerty" 329 "Dief" 341 "Boening Automationstechnologie" 345 "Korean Maritime University" 351 "Thrane and Thrane" 355 "Mastervolt" 356 "Fischer Panda Generators" 358 "Victron Energy" 370 "Rolls Royce Marine" 373 "Electronic Design" 374 "Northern Lights" 378 "Glendinning" 381 "B & G" 384 "Rose Point Navigation Systems" 385 "Johnson Outdoors Marine Electronics Inc Geonav" 394 "Capi 2" 396 "Beyond Measure" 400 "Livorsi Marine" 404 "ComNav" 409 "Chetco" 419 "Fusion Electronics" 421 "Standard Horizon" 422 "True Heading" 426 "Egersund Marine Electronics" 427 "em-trak Marine Electronics" 431 "Tohatsu Co, JP" 437 "Digital Yacht" 438 "Comar Systems Limited" 440 "Cummins" 443 "VDO (aka Continental-Corporation)" 451 "Parker Hannifin aka Village Marine Tech" 459 "Alltek Marine Electronics" 460 "SAN GIORGIO S.E.I.N" 466 "Veethree Electronics & Marine" 470 "SI-TEX Marine Electronics" 471 "Sea Cross Marine" 475 "GME aka Standard Communications" 476 "Humminbird Marine Electronics" 478 "Ocean Sat" 481 "Chetco Digital Instruments" 493 "Watcheye" 499 "Lcj Capteurs" 502 "Attwood Marine" 503 "Naviop S.R.L." 504 "Vesper Marine" 510 "Marinesoft" 513 "Simarine" 517 "NoLand Engineering" 518 "Transas USA" 529 "National Instruments Korea" 530 "National Marine Electronics Association" 532 "Onwa Marine" 540 "Webasto" 571 "Marinecraft (South Korea)" 573 "McMurdo Group aka Orolia" 578 "Advansea" 579 "KVH" 580 "San Jose Technology" 583 "Yacht Control" 586 "Suzuki Motor" 591 "US Coast Guard" 595 "Ship Module aka Customware" 600 "Aquatic AV" 605 "Aventics" 606 "Intellian" 612 "SamwonIT" 614 "Arlt Tecnologies" 637 "Bavaria Yachts" 641 "Diverse Yacht Services" 644 "Wema U.S.A dba KUS" 658 "Shenzhen Jiuzhou Himunication" 688 "Rockford" 699 "Harman International" 704 "JL Audio" 708 "Lars Thrane" 715 "Autonnic" 717 "Yacht Devices" 734 "REAP Systems" 735 "AEM Performance Electronics" 739 "LxNav" 741 "Littelfuse, Inc (formerly Carling Technologies)" 743 "DaeMyung" 744 "Woosung" 748 "ISOTTA IFRA srl" 773 "Clarion US" 776 "HMI Systems" 777 "Ocean Signal" 778 "Seakeeper" 781 "Poly Planar" 785 "Fischer Panda DE" 795 "Broyda Industries" 796 "Canadian Automotive" 797 "Tides Marine" 798 "Lumishore" 799 "Still Water Designs and Audio" 802 "BJ Technologies (Beneteau)" 803 "Gill Sensors" 811 "Blue Water Desalination" 815 "FLIR" 824 "Undheim Systems" 826 "Lewmar" 838 "TeamSurv" 844 "Fell Marine" 847 "Oceanvolt" 862 "Prospec" 868 "Data Panel" 890 "L3 Technologies" 894 "Rhodan Marine Systems" 896 "Nexfour Solutions" 905 "ASA Electronics" 909 "Marines Co (South Korea)" 911 "Nautic-on" 917 "Sentinel" 929 "JL Marine Systems" 930 "Ecotronix" 944 "Zontisa Marine" 951 "EXOR International" 962 "Timbolier Industries" 963 "TJC Micro" 968 "Cox Powertrain" 969 "Blue Seas" 981 "Kobelt Manufacturing" 992 "Blue Ocean IOT" 997 "Xenta Systems" 999 "Signal K" 1004 "Ultraflex" 1008 "Lintest SmartBoat" 1011 "Soundmax" 1020 "Team Italia Marine (Onyx Marine Automation s.r.l)" 1021 "Entratech" 1022 "ITC" 1029 "The Marine Guardian" 1047 "Sonic" 1051 "ProNav" 1053 "Vetus Maxwell INC." 1056 "Lithium Pros" 1059 "Boatrax" 1062 "Marol Co ltd" 1065 "CALYPSO Instruments" 1066 "Spot Zero Water" 1069 "Lithionics Battery" 1070 "Quick-teck Electronics" 1075 "Uniden America" 1083 "Nauticoncept" 1084 "Shadow-Caster LED lighting" 1085 "Wet Sounds" 1088 "E-T-A Circuit Breakers" 1092 "Scheiber" 1100 "Smart Yachts International Limited" 1109 "Dockmate" 1114 "Bobs Machine" 1118 "L3Harris ASV" 1119 "Balmar" 1120 "Elettromedia" 1127 "Electromaax" 1140 "Across Oceans Systems" 1145 "Kiwi Yachting" 1150 "BSB Artificial Intelligence" 1151 "Orca Technologies" 1154 "TBS Electronics" 1158 "Technoton Electroics" 1160 "MG Energy Systems" 1169 "Sea Machine Robotics" 1171 "Vista Manufacturing" 1183 "Zipwake" 1186 "Sailmon" 1192 "Airmoniq Pro Kft" 1194 "Sierra Marine" 1200 "Xinuo Information Technology (Xiamen)" 1218 "Septentrio" 1233 "NKE Marine Electronics" 1238 "SuperTrack Aps" 1239 "Honda Electronics" 1245 "Raritan Engineering" 1249 "Integrated Power Solutions AG" 1260 "Interactive Technologies" 1283 "LTG-Tech" 1299 "Energy Solutions (UK)" 1300 "WATT Fuel Cell" 1302 "Pro Mainer" 1305 "Dragonfly Energy" 1306 "Koden Electronics" 1311 "Humphree" 1316 "Hinkley Yachts" 1317 "Global Marine Management GmbH (GMM)" 1320 "Triskel Marine" 1330 "Warwick Control Technologies" 1331 "Dolphin Charger" 1337 "Barnacle Systems" 1348 "Radian IoT" 1353 "Ocean LED Marine" 1359 "BluNav" 1361 "OVA (Nantong Saiyang Electronics Co., Ltd)" 1368 "RAD Propulsion" 1369 "Electric Yacht" 1372 "Elco Motor Yachts" 1384 "Tecnoseal Foundry S.r.l" 1385 "Pro Charging Systems" 1389 "EVEX" 1398 "Gobius Sensor Technology" 1403 "Arco Marine" 1408 "Lenco Marine" 1413 "Naocontrol" 1417 "Revatek" 1438 "Aeolionics" 1439 "PredictWind" 1440 "Egis Mobile Electric" 1445 "Starboard Yacht Group" 1446 "Roswell Marine" 1451 "ePropulsion (Guangdong ePropulsion Technology Ltd.)" 1452 "Micro-Air" 1453 "Vital Battery" 1458 "Ride Controller" 1460 "Tocaro Blue" 1461 "Vanquish Yachts" 1471 "FT Technologies" 1478 "Alps Alpine" 1481 "E-Force Marine" 1482 "CMC Marine" 1483 "Nanjing Sandemarine Information Technology" 1850 "Teleflex Marine (SeaStar Solutions)" 1851 "Raymarine" 1852 "Navionics" 1853 "Japan Radio" 1854 "Northstar Technologies" 1855 "Furuno" 1856 "Trimble" 1857 "Simrad" 1858 "Litton" 1859 "Kvasar" 1860 "MMP" 1861 "Vector Cantech" 1862 "Yamaha Marine" 1863 "Faria Instruments" ;
VAL_ 2633990400 Industry_Code 0 "Global" 1 "Highway" 2 "Agriculture" 3 "Construction" 4 "Marine Industry" 5 "Industrial" ;
VAL_ 2633990656 Manufacturer_Code 69 "ARKS Enterprises" 78 "FW Murphy/Enovation Controls" 80 "Twin Disc" 85 "Kohler Power Systems" 88 "Hemisphere GPS" 135 "Airmar" 137 "Maretron" 140 "Lowrance" 144 "Mercury Marine" 147 "Nautibus Electronic" 148 "Blue Water Data" 154 "Westerbeke" 157 "ISSPRO" 161 "Offshore Systems (UK)" 163 "Evinrude/BRP" 165 "CPAC Systems" 168 "Xantrex Technology" 169 "Marlin Technologies" 172 "Yanmar Marine" 174 "Volvo Penta" 176 "Carling Technologies Inc. (Moritz Aerospace)" 185 "Beede Instruments" 192 "Floscan Instrument" 193 "Nobeltec" 198 "Mystic Valley Communications" 199 "Actia" 201 "Disenos Y Technologia" 211 "Digital Switching Systems" 215 "Xintex/Atena" 224 "EMMI NETWORK" 228 "ZF" 229 "Garmin" 233 "Yacht Monitoring Solutions" 235 "Sailormade Marine Telemetry/Tetra Technology" 243 "Eride" 257 "Honda Motor" 272 "Groco" 273 "Actisense" 274 "Amphenol LTW Technology" 275 "Navico" 283 "Hamilton Jet" 285 "Sea Recovery" 286 "Coelmo SRL Italy" 295 "BEP Marine" 304 "Empir Bus" 305 "NovAtel" 306 "Sleipner Motor" 307 "MBW Technologies" 315 "ICOM" 328 "Qwerty" 329 "Dief" 341 "Boening Automationstechnologie" 345 "Korean Maritime University" 351 "Thrane and Thrane" 355 "Mastervolt" 356 "Fischer Panda Generators" 358 "Victron Energy" 370 "Rolls Royce Marine" 373 "Electronic Design" 374 "Northern Lights" 378 "Glendinning" 381 "B & G" 384 "Rose Point Navigation Systems" 385 "Johnson Outdoors Marine Electronics Inc Geonav" 394 "Capi 2" 396 "Beyond Measure" 400 "Livorsi Marine" 404 "ComNav" 409 "Chetco" 419 "Fusion Electronics" 421 "Standard Horizon" 422 "True Heading" 426 "Egersund Marine Electronics" 427 "em-trak Marine Electronics" 431 "Tohatsu Co, JP" 437 "Digital Yacht" 438 "Comar Systems Limited" 440 "Cummins" 443 "VDO (aka Continental-Corporation)" 451 "Parker Hannifin aka Village Marine Tech" 459 "Alltek Marine Electronics" 460 "SAN GIORGIO S.E.I.N" 466 "Veethree Electronics & Marine" 470 "SI-TEX Marine Electronics" 471 "Sea Cross Marine" 475 "GME aka Standard Communications" 476 "Humminbird Marine Electronics" 478 "Ocean Sat" 481 "Chetco Digital Instruments" 493 "Watcheye" 499 "Lcj Capteurs" 502 "Attwood Marine" 503 "Naviop S.R.L." 504 "Vesper Marine" 510 "Marinesoft" 513 "Simarine" 517 "NoLand Engineering" 518 "Transas USA" 529 "National Instruments Korea" 530 "National Marine Electronics Association" 532 "Onwa Marine" 540 "Webasto" 571 "Marinecraft (South Korea)" 573 "McMurdo Group aka Orolia" 578 "Advansea" 579 "KVH" 580 "San Jose Technology" 583 "Yacht Control" 586 "Suzuki Motor" 591 "US Coast Guard" 595 "Ship Module aka Customware" 600 "Aquatic AV" 605 "Aventics" 606 "Intellian" 612 "SamwonIT" 614 "Arlt Tecnologies" 637 "Bavaria Yachts" 641 "Diverse Yacht Services" 644 "Wema U.S.A dba KUS" 658 "Shenzhen Jiuzhou Himunication" 688 "Rockford" 699 "Harman International" 704 "JL Audio" 708 "Lars Thrane" 715 "Autonnic" 717 "Yacht Devices" 734 "REAP Systems" 735 "AEM Performance Electronics" 739 "LxNav" 741 "Littelfuse, Inc (formerly Carling Technologies)" 743 "DaeMyung" 744 "Woosung" 748 "ISOTTA IFRA srl" 773 "Clarion US" 776 "HMI Systems" 777 "Ocean Signal" 778 "Seakeeper" 781 "Poly Planar" 785 "Fischer Panda DE" 795 "Broyda Industries" 796 "Canadian Automotive" 797 "Tides Marine" 798 "Lumishore" 799 "Still Water Designs and Audio" 802 "BJ Technologies (Beneteau)" 803 "Gill Sensors" 811 "Blue Water Desalination" 815 "FLIR" 824 "Undheim Systems" 826 "Lewmar" 838 "TeamSurv" 844 "Fell Marine" 847 "Oceanvolt" 862 "Prospec" 868 "Data Panel" 890 "L3 Technologies" 894 "Rhodan Marine Systems" 896 "Nexfour Solutions" 905 "ASA Electronics" 909 "Marines Co (South Korea)" 911 "Nautic-on" 917 "Sentinel" 929 "JL Marine Systems" 930 "Ecotronix" 944 "Zontisa Marine" 951 "EXOR International" 962 "Timbolier Industries" 963 "TJC Micro" 968 "Cox Powertrain" 969 "Blue Seas" 981 "Kobelt Manufacturing" 992 "Blue Ocean IOT" 997 "Xenta Systems" 999 "Signal K" 1004 "Ultraflex" 1008 "Lintest SmartBoat" 1011 "Soundmax" 1020 "Team Italia Marine (Onyx Marine Automation s.r.l)" 1021 "Entratech" 1022 "ITC" 1029 "The Marine Guardian" 1047 "Sonic" 1051 "ProNav" 1053 "Vetus Maxwell INC." 1056 "Lithium Pros" 1059 "Boatrax" 1062 "Marol Co ltd" 1065 "CALYPSO Instruments" 1066 "Spot Zero Water" 1069 "Lithionics Battery" 1070 "Quick-teck Electronics" 1075 "Uniden America" 1083 "Nauticoncept" 1084 "Shadow-Caster LED lighting" 1085 "Wet Sounds" 1088 "E-T-A Circuit Breakers" 1092 "Scheiber" 1100 "Smart Yachts International Limited" 1109 "Dockmate" 1114 "Bobs Machine" 1118 "L3Harris ASV" 1119 "Balmar" 1120 "Elettromedia" 1127 "Electromaax" 1140 "Across Oceans Systems" 1145 "Kiwi Yachting" 1150 "BSB Artificial Intelligence" 1151 "Orca Technologies" 1154 "TBS Electronics" 1158 "Technoton Electroics" 1160 "MG Energy Systems" 1169 "Sea Machine Robotics" 1171 "Vista Manufacturing" 1183 "Zipwake" 1186 "Sailmon" 1192 "Airmoniq Pro Kft" 1194 "Sierra Marine" 1200 "Xinuo Information Technology (Xiamen)" 1218 "Septentrio" 1233 "NKE Marine Electronics" 1238 "SuperTrack Aps" 1239 "Honda Electronics" 1245 "Raritan Engineering" 1249 "Integrated Power Solutions AG" 1260 "Interactive Technologies" 1283 "LTG-Tech" 1299 "Energy Solutions (UK)" 1300 "WATT Fuel Cell" 1302 "Pro Mainer" 1305 "Dragonfly Energy" 1306 "Koden Electronics" 1311 "Humphree" 1316 "Hinkley Yachts" 1317 "Global Marine Management GmbH (GMM)" 1320 "Triskel Marine" 1330 "Warwick Control Technologies" 1331 "Dolphin Charger" 1337 "Barnacle Systems" 1348 "Radian IoT" 1353 "Ocean LED Marine" 1359 "BluNav" 1361 "OVA (Nantong Saiyang Electronics Co., Ltd)" 1368 "RAD Propulsion" 1369 "Electric Yacht" 1372 "Elco Motor Yachts" 1384 "Tecnoseal Foundry S.r.l" 1385 "Pro Charging Systems" 1389 "EVEX" 1398 "Gobius Sensor Technology" 1403 "Arco Marine" 1408 "Lenco Marine" 1413 "Naocontrol" 1417 "Revatek" 1438 "Aeolionics" 1439 "PredictWind" 1440 "Egis Mobile Electric" 1445 "Starboard Yacht Group" 1446 "Roswell Marine" 1451 "ePropulsion (Guangdong ePropulsion Technology Ltd.)" 1452 "Micro-Air" 1453 "Vital Battery" 1458 "Ride Controller" 1460 "Tocaro Blue" 1461 "Vanquish Yachts" 1471 "FT Technologies" 1478 "Alps Alpine" 1481 "E-Force Marine" 1482 "CMC Marine" 1483 "Nanjing Sandemarine Information Technology" 1850 "Teleflex Marine (SeaStar Solutions)" 1851 "Raymarine" 1852 "Navionics" 1853 "Japan Radio" 1854 "Northstar Technologies" 1855 "Furuno" 1856 "Trimble" 1857 "Simrad" 1858 "Litton" 1859 "Kvasar" 1860 "MMP" 1861 "Vector Cantech" 1862 "Yamaha Marine" 1863 "Faria Instruments" ;
VAL_ 2633990656 Industry_Code 0 "Global" 1 "Highway" 2 "Agriculture" 3 "Construction" 4 "Marine Industry" 5 "Industrial" ;
VAL_ 2566884352 Manufacturer_Code 69 "ARKS Enterprises" 78 "FW Murphy/Enovation Controls" 80 "Twin Disc" 85 "Kohler Power Systems" 88 "Hemisphere GPS" 135 "Airmar" 137 "Maretron" 140 "Lowrance" 144 "Mercury Marine" 147 "Nautibus Electronic" 148 "Blue Water Data" 154 "Westerbeke" 157 "ISSPRO" 161 "Offshore Systems (UK)" 163 "Evinrude/BRP" 165 "CPAC Systems" 168 "Xantrex Technology" 169 "Marlin Technologies" 172 "Yanmar Marine" 174 "Volvo Penta" 176 "Carling Technologies Inc. (Moritz Aerospace)" 185 "Beede Instruments" 192 "Floscan Instrument" 193 "Nobeltec" 198 "Mystic Valley Communications" 199 "Actia" 201 "Disenos Y Technologia" 211 "Digital Switching Systems" 215 "Xintex/Atena" 224 "EMMI NETWORK" 228 "ZF" 229 "Garmin" 233 "Yacht Monitoring Solutions" 235 "Sailormade Marine Telemetry/Tetra Technology" 243 "Eride" 257 "Honda Motor" 272 "Groco" 273 "Actisense" 274 "Amphenol LTW Technology" 275 "Navico" 283 "Hamilton Jet" 285 "Sea Recovery" 286 "Coelmo SRL Italy" 295 "BEP Marine" 304 "Empir Bus" 305 "NovAtel" 306 "Sleipner Motor" 307 "MBW Technologies" 315 "ICOM" 328 "Qwerty" 329 "Dief" 341 "Boening Automationstechnologie" 345 "Korean Maritime University" 351 "Thrane and Thrane" 355 "Mastervolt" 356 "Fischer Panda Generators" 358 "Victron Energy" 370 "Rolls Royce Marine" 373 "Electronic Design" 374 "Northern Lights" 378 "Glendinning" 381 "B & G" 384 "Rose Point Navigation Systems" 385 "Johnson Outdoors Marine Electronics Inc Geonav" 394 "Capi 2" 396 "Beyond Measure" 400 "Livorsi Marine" 404 "ComNav" 409 "Chetco" 419 "Fusion Electronics" 421 "Standard Horizon" 422 "True Heading" 426 "Egersund Marine Electronics" 427 "em-trak Marine Electronics" 431 "Tohatsu Co, JP" 437 "Digital Yacht" 438 "Comar Systems Limited" 440 "Cummins" 443 "VDO (aka Continental-Corporation)" 451 "Parker Hannifin aka Village Marine Tech" 459 "Alltek Marine Electronics" 460 "SAN GIORGIO S.E.I.N" 466 "Veethree Electronics & Marine" 470 "SI-TEX Marine Electronics" 471 "Sea Cross Marine" 475 "GME aka Standard Communications" 476 "Humminbird Marine Electronics" 478 "Ocean Sat" 481 "Chetco Digital Instruments" 493 "Watcheye" 499 "Lcj Capteurs" 502 "Attwood Marine" 503 "Naviop S.R.L." 504 "Vesper Marine" 510 "Marinesoft" 513 "Simarine" 517 "NoLand Engineering" 518 "Transas USA" 529 "National Instruments Korea" 530 "National Marine Electronics Association" 532 "Onwa Marine" 540 "Webasto" 571 "Marinecraft (South Korea)" 573 "McMurdo Group aka Orolia" 578 "Advansea" 579 "KVH" 580 "San Jose Technology" 583 "Yacht Control" 586 "Suzuki Motor" 591 "US Coast Guard" 595 "Ship Module aka Customware" 600 "Aquatic AV" 605 "Aventics" 606 "Intellian" 612 "SamwonIT" 614 "Arlt Tecnologies" 637 "Bavaria Yachts" 641 "Diverse Yacht Services" 644 "Wema U.S.A dba KUS" 658 "Shenzhen Jiuzhou Himunication" 688 "Rockford" 699 "Harman International" 704 "JL Audio" 708 "Lars Thrane" 715 "Autonnic" 717 "Yacht Devices" 734 "REAP Systems" 735 "AEM Performance Electronics" 739 "LxNav" 741 "Littelfuse, Inc (formerly Carling Technologies)" 743 "DaeMyung" 744 "Woosung" 748 "ISOTTA IFRA srl" 773 "Clarion US" 776 "HMI Systems" 777 "Ocean Signal" 778 "Seakeeper" 781 "Poly Planar" 785 "Fischer Panda DE" 795 "Broyda Industries" 796 "Canadian Automotive" 797 "Tides Marine" 798 "Lumishore" 799 "Still Water Designs and Audio" 802 "BJ Technologies (Beneteau)" 803 "Gill Sensors" 811 "Blue Water Desalination" 815 "FLIR" 824 "Undheim Systems" 826 "Lewmar" 838 "TeamSurv" 844 "Fell Marine" 847 "Oceanvolt" 862 "Prospec" 868 "Data Panel" 890 "L3 Technologies" 894 "Rhodan Marine Systems" 896 "Nexfour Solutions" 905 "ASA Electronics" 909 "Marines Co (South Korea)" 911 "Nautic-on" 917 "Sentinel" 929 "JL Marine Systems" 930 "Ecotronix" 944 "Zontisa Marine" 951 "EXOR International" 962 "Timbolier Industries" 963 "TJC Micro" 968 "Cox Powertrain" 969 "Blue Seas" 981 "Kobelt Manufacturing" 992 "Blue Ocean IOT" 997 "Xenta Systems" 999 "Signal K" 1004 "Ultraflex" 1008 "Lintest SmartBoat" 1011 "Soundmax" 1020 "Team Italia Marine (Onyx Marine Automation s.r.l)" 1021 "Entratech" 1022 "ITC" 1029 "The Marine Guardian" 1047 "Sonic" 1051 "ProNav" 1053 "Vetus Maxwell INC." 1056 "Lithium Pros" 1059 "Boatrax" 1062 "Marol Co ltd" 1065 "CALYPSO Instruments" 1066 "Spot Zero Water" 1069 "Lithionics Battery" 1070 "Quick-teck Electronics" 1075 "Uniden America" 1083 "Nauticoncept" 1084 "Shadow-Caster LED lighting" 1085 "Wet Sounds" 1088 "E-T-A Circuit Breakers" 1092 "Scheiber" 1100 "Smart Yachts International Limited" 1109 "Dockmate" 1114 "Bobs Machine" 1118 "L3Harris ASV" 1119 "Balmar" 1120 "Elettromedia" 1127 "Electromaax" 1140 "Across Oceans Systems" 1145 "Kiwi Yachting" 1150 "BSB Artificial Intelligence" 1151 "Orca Technologies" 1154 "TBS Electronics" 1158 "Technoton Electroics" 1160 "MG Energy Systems" 1169 "Sea Machine Robotics" 1171 "Vista Manufacturing" 1183 "Zipwake" 1186 "Sailmon" 1192 "Airmoniq Pro Kft" 1194 "Sierra Marine" 1200 "Xinuo Information Technology (Xiamen)" 1218 "Septentrio" 1233 "NKE Marine Electronics" 1238 "SuperTrack Aps" 1239 "Honda Electronics" 1245 "Raritan Engineering" 1249 "Integrated Power Solutions AG" 1260 "Interactive Technologies" 1283 "LTG-Tech" 1299 "Energy Solutions (UK)" 1300 "WATT Fuel Cell" 1302 "Pro Mainer" 1305 "Dragonfly Energy" 1306 "Koden Electronics" 1311 "Humphree" 1316 "Hinkley Yachts" 1317 "Global Marine Management GmbH (GMM)" 1320 "Triskel Marine" 1330 "Warwick Control Technologies" 1331 "Dolphin Charger" 1337 "Barnacle Systems" 1348 "Radian IoT" 1353 "Ocean LED Marine" 1359 "BluNav" 1361 "OVA (Nantong Saiyang Electronics Co., Ltd)" 1368 "RAD Propulsion" 1369 "Electric Yacht" 1372 "Elco Motor Yachts" 1384 "Tecnoseal Foundry S.r.l" 1385 "Pro Charging Systems" 1389 "EVEX" 1398 "Gobius Sensor Technology" 1403 "Arco Marine" 1408 "Lenco Marine" 1413 "Naocontrol" 1417 "Revatek" 1438 "Aeolionics" 1439 "PredictWind" 1440 "Egis Mobile Electric" 1445 "Starboard Yacht Group" 1446 "Roswell Marine" 1451 "ePropulsion (Guangdong ePropulsion Technology Ltd.)" 1452 "Micro-Air" 1453 "Vital Battery" 1458 "Ride Controller" 1460 "Tocaro Blue" 1461 "Vanquish Yachts" 1471 "FT Technologies" 1478 "Alps Alpine" 1481 "E-Force Marine" 1482 "CMC Marine" 1483 "Nanjing Sandemarine Information Technology" 1850 "Teleflex Marine (SeaStar Solutions)" 1851 "Raymarine" 1852 "Navionics" 1853 "Japan Radio" 1854 "Northstar Technologies" 1855 "Furuno" 1856 "Trimble" 1857 "Simrad" 1858 "Litton" 1859 "Kvasar" 1860 "MMP" 1861 "Vector Cantech" 1862 "Yamaha Marine" 1863 "Faria Instruments" ;
VAL_ 2566884352 Industry_Code 0 "Global" 1 "Highway" 2 "Agriculture" 3 "Construction" 4 "Marine Industry" 5 "Industrial" ;
VAL_ 2566885376 Manufacturer_Code 69 "ARKS Enterprises" 78 "FW Murphy/Enovation Controls" 80 "Twin Disc" 85 "Kohler Power Systems" 88 "Hemisphere GPS" 135 "Airmar" 137 "Maretron" 140 "Lowrance" 144 "Mercury Marine" 147 "Nautibus Electronic" 148 "Blue Water Data" 154 "Westerbeke" 157 "ISSPRO" 161 "Offshore Systems (UK)" 163 "Evinrude/BRP" 165 "CPAC Systems" 168 "Xantrex Technology" 169 "Marlin Technologies" 172 "Yanmar Marine" 174 "Volvo Penta" 176 "Carling Technologies Inc. (Moritz Aerospace)" 185 "Beede Instruments" 192 "Floscan Instrument" 193 "Nobeltec" 198 "Mystic Valley Communications" 199 "Actia" 201 "Disenos Y Technologia" 211 "Digital Switching Systems" 215 "Xintex/Atena" 224 "EMMI NETWORK" 228 "ZF" 229 "Garmin" 233 "Yacht Monitoring Solutions" 235 "Sailormade Marine Telemetry/Tetra Technology" 243 "Eride" 257 "Honda Motor" 272 "Groco" 273 "Actisense" 274 "Amphenol LTW Technology" 275 "Navico" 283 "Hamilton Jet" 285 "Sea Recovery" 286 "Coelmo SRL Italy" 295 "BEP Marine" 304 "Empir Bus" 305 "NovAtel" 306 "Sleipner Motor" 307 "MBW Technologies" 315 "ICOM" 328 "Qwerty" 329 "Dief" 341 "Boening Automationstechnologie" 345 "Korean Maritime University" 351 "Thrane and Thrane" 355 "Mastervolt" 356 "Fischer Panda Generators" 358 "Victron Energy" 370 "Rolls Royce Marine" 373 "Electronic Design" 374 "Northern Lights" 378 "Glendinning" 381 "B & G" 384 "Rose Point Navigation Systems" 385 "Johnson Outdoors Marine Electronics Inc Geonav" 394 "Capi 2" 396 "Beyond Measure" 400 "Livorsi Marine" 404 "ComNav" 409 "Chetco" 419 "Fusion Electronics" 421 "Standard Horizon" 422 "True Heading" 426 "Egersund Marine Electronics" 427 "em-trak Marine Electronics" 431 "Tohatsu Co, JP" 437 "Digital Yacht" 438 "Comar Systems Limited" 440 "Cummins" 443 "VDO (aka Continental-Corporation)" 451 "Parker Hannifin aka Village Marine Tech" 459 "Alltek Marine Electronics" 460 "SAN GIORGIO S.E.I.N" 466 "Veethree Electronics & Marine" 470 "SI-TEX Marine Electronics" 471 "Sea Cross Marine" 475 "GME aka Standard Communications" 476 "Humminbird Marine Electronics" 478 "Ocean Sat" 481 "Chetco Digital Instruments" 493 "Watcheye" 499 "Lcj Capteurs" 502 "Attwood Marine" 503 "Naviop S.R.L." 504 "Vesper Marine" 510 "Marinesoft" 513 "Simarine" 517 "NoLand Engineering" 518 "Transas USA" 529 "National Instruments Korea" 530 "National Marine Electronics Association" 532 "Onwa Marine" 540 "Webasto" 571 "Marinecraft (South Korea)" 573 "McMurdo Group aka Orolia" 578 "Advansea" 579 "KVH" 580 "San Jose Technology" 583 "Yacht Control" 586 "Suzuki Motor" 591 "US Coast Guard" 595 "Ship Module aka Customware" 600 "Aquatic AV" 605 "Aventics" 606 "Intellian" 612 "SamwonIT" 614 "Arlt Tecnologies" 637 "Bavaria Yachts" 641 "Diverse Yacht Services" 644 "Wema U.S.A dba KUS" 658 "Shenzhen Jiuzhou Himunication" 688 "Rockford" 699 "Harman International" 704 "JL Audio" 708 "Lars Thrane" 715 "Autonnic" 717 "Yacht Devices" 734 "REAP Systems" 735 "AEM Performance Electronics" 739 "LxNav" 741 "Littelfuse, Inc (formerly Carling Technologies)" 743 "DaeMyung" 744 "Woosung" 748 "ISOTTA IFRA srl" 773 "Clarion US" 776 "HMI Systems" 777 "Ocean Signal" 778 "Seakeeper" 781 "Poly Planar" 785 "Fischer Panda DE" 795 "Broyda Industries" 796 "Canadian Automotive" 797 "Tides Marine" 798 "Lumishore" 799 "Still Water Designs and Audio" 802 "BJ Technologies (Beneteau)" 803 "Gill Sensors" 811 "Blue Water Desalination" 815 "FLIR" 824 "Undheim Systems" 826 "Lewmar" 838 "TeamSurv" 844 "Fell Marine" 847 "Oceanvolt" 862 "Prospec" 868 "Data Panel" 890 "L3 Technologies" 894 "Rhodan Marine Systems" 896 "Nexfour Solutions" 905 "ASA Electronics" 909 "Marines Co (South Korea)" 911 "Nautic-on" 917 "Sentinel" 929 "JL Marine Systems" 930 "Ecotronix" 944 "Zontisa Marine" 951 "EXOR International" 962 "Timbolier Industries" 963 "TJC Micro" 968 "Cox Powertrain" 969 "Blue Seas" 981 "Kobelt Manufacturing" 992 "Blue Ocean IOT" 997 "Xenta Systems" 999 "Signal K" 1004 "Ultraflex" 1008 "Lintest SmartBoat" 1011 "Soundmax" 1020 "Team Italia Marine (Onyx Marine Automation s.r.l)" 1021 "Entratech" 1022 "ITC" 1029 "The Marine Guardian" 1047 "Sonic" 1051 "ProNav" 1053 "Vetus Maxwell INC." 1056 "Lithium Pros" 1059 "Boatrax" 1062 "Marol Co ltd" 1065 "CALYPSO Instruments" 1066 "Spot Zero Water" 1069 "Lithionics Battery" 1070 "Quick-teck Electronics" 1075 "Uniden America" 1083 "Nauticoncept" 1084 "Shadow-Caster LED lighting" 1085 "Wet Sounds" 1088 "E-T-A Circuit Breakers" 1092 "Scheiber" 1100 "Smart Yachts International Limited" 1109 "Dockmate" 1114 "Bobs Machine" 1118 "L3Harris ASV" 1119 "Balmar" 1120 "Elettromedia" 1127 "Electromaax" 1140 "Across Oceans Systems" 1145 "Kiwi Yachting" 1150 "BSB Artificial Intelligence" 1151 "Orca Technologies" 1154 "TBS Electronics" 1158 "Technoton Electroics" 1160 "MG Energy Systems" 1169 "Sea Machine Robotics" 1171 "Vista Manufacturing" 1183 "Zipwake" 1186 "Sailmon" 1192 "Airmoniq Pro Kft" 1194 "Sierra Marine" 1200 "Xinuo Information Technology (Xiamen)" 1218 "Septentrio" 1233 "NKE Marine Electronics" 1238 "SuperTrack Aps" 1239 "Honda Electronics" 1245 "Raritan Engineering" 1249 "Integrated Power Solutions AG" 1260 "Interactive Technologies" 1283 "LTG-Tech" 1299 "Energy Solutions (UK)" 1300 "WATT Fuel Cell" 1302 "Pro Mainer" 1305 "Dragonfly Energy" 1306 "Koden Electronics" 1311 "Humphree" 1316 "Hinkley Yachts" 1317 "Global Marine Management GmbH (GMM)" 1320 "Triskel Marine" 1330 "Warwick Control Technologies" 1331 "Dolphin Charger" 1337 "Barnacle Systems" 1348 "Radian IoT" 1353 "Ocean LED Marine" 1359 "BluNav" 1361 "OVA (Nantong Saiyang Electronics Co., Ltd)" 1368 "RAD Propulsion" 1369 "Electric Yacht" 1372 "Elco Motor Yachts" 1384 "Tecnoseal Foundry S.r.l" 1385 "Pro Charging Systems" 1389 "EVEX" 1398 "Gobius Sensor Technology" 1403 "Arco Marine" 1408 "Lenco Marine" 1413 "Naocontrol" 1417 "Revatek" 1438 "Aeolionics" 1439 "PredictWind" 1440 "Egis Mobile Electric" 1445 "Starboard Yacht Group" 1446 "Roswell Marine" 1451 "ePropulsion (Guangdong ePropulsion Technology Ltd.)" 1452 "Micro-Air" 1453 "Vital Battery" 1458 "Ride Controller" 1460 "Tocaro Blue" 1461 "Vanquish Yachts" 1471 "FT Technologies" 1478 "Alps Alpine" 1481 "E-Force Marine" 1482 "CMC Marine" 1483 "Nanjing Sandemarine Information Technology" 1850 "Teleflex Marine (SeaStar Solutions)" 1851 "Raymarine" 1852 "Navionics" 1853 "Japan Radio" 1854 "Northstar Technologies" 1855 "Furuno" 1856 "Trimble" 1857 "Simrad" 1858 "Litton" 1859 "Kvasar" 1860 "MMP" 1861 "Vector Cantech" 1862 "Yamaha Marine" 1863 "Faria Instruments" ;
VAL_ 2566885376 Industry_Code 0 "Global" 1 "Highway" 2 "Agriculture" 3 "Construction" 4 "Marine Industry" 5 "Industrial" ;
VAL_ 2566889472 Manufacturer_Code 69 "ARKS Enterprises" 78 "FW Murphy/Enovation Controls" 80 "Twin Disc" 85 "Kohler Power Systems" 88 "Hemisphere GPS" 135 "Airmar" 137 "Maretron" 140 "Lowrance" 144 "Mercury Marine" 147 "Nautibus Electronic" 148 "Blue Water Data" 154 "Westerbeke" 157 "ISSPRO" 161 "Offshore Systems (UK)" 163 "Evinrude/BRP" 165 "CPAC Systems" 168 "Xantrex Technology" 169 "Marlin Technologies" 172 "Yanmar Marine" 174 "Volvo Penta" 176 "Carling Technologies Inc. (Moritz Aerospace)" 185 "Beede Instruments" 192 "Floscan Instrument" 193 "Nobeltec" 198 "Mystic Valley Communications" 199 "Actia" 201 "Disenos Y Technologia" 211 "Digital Switching Systems" 215 "Xintex/Atena" 224 "EMMI NETWORK" 228 "ZF" 229 "Garmin" 233 "Yacht Monitoring Solutions" 235 "Sailormade Marine Telemetry/Tetra Technology" 243 "Eride" 257 "Honda Motor" 272 "Groco" 273 "Actisense" 274 "Amphenol LTW Technology" 275 "Navico" 283 "Hamilton Jet" 285 "Sea Recovery" 286 "Coelmo SRL Italy" 295 "BEP Marine" 304 "Empir Bus" 305 "NovAtel" 306 "Sleipner Motor" 307 "MBW Technologies" 315 "ICOM" 328 "Qwerty" 329 "Dief" 341 "Boening Automationstechnologie" 345 "Korean Maritime University" 351 "Thrane and Thrane" 355 "Mastervolt" 356 "Fischer Panda Generators" 358 "Victron Energy" 370 "Rolls Royce Marine" 373 "Electronic Design" 374 "Northern Lights" 378 "Glendinning" 381 "B & G" 384 "Rose Point Navigation Systems" 385 "Johnson Outdoors Marine Electronics Inc Geonav" 394 "Capi 2" 396 "Beyond Measure" 400 "Livorsi Marine" 404 "ComNav" 409 "Chetco" 419 "Fusion Electronics" 421 "Standard Horizon" 422 "True Heading" 426 "Egersund Marine Electronics" 427 "em-trak Marine Electronics" 431 "Tohatsu Co, JP" 437 "Digital Yacht" 438 "Comar Systems Limited" 440 "Cummins" 443 "VDO (aka Continental-Corporation)" 451 "Parker Hannifin aka Village Marine Tech" 459 "Alltek Marine Electronics" 460 "SAN GIORGIO S.E.I.N" 466 "Veethree Electronics & Marine" 470 "SI-TEX Marine Electronics" 471 "Sea Cross Marine" 475 "GME aka Standard Communications" 476 "Humminbird Marine Electronics" 478 "Ocean Sat" 481 "Chetco Digital Instruments" 493 "Watcheye" 499 "Lcj Capteurs" 502 "Attwood Marine" 503 "Naviop S.R.L." 504 "Vesper Marine" 510 "Marinesoft" 513 "Simarine" 517 "NoLand Engineering" 518 "Transas USA" 529 "National Instruments Korea" 530 "National Marine Electronics Association" 532 "Onwa Marine" 540 "Webasto" 571 "Marinecraft (South Korea)" 573 "McMurdo Group aka Orolia" 578 "Advansea" 579 "KVH" 580 "San Jose Technology" 583 "Yacht Control" 586 "Suzuki Motor" 591 "US Coast Guard" 595 "Ship Module aka Customware" 600 "Aquatic AV" 605 "Aventics" 606 "Intellian" 612 "SamwonIT" 614 "Arlt Tecnologies" 637 "Bavaria Yachts" 641 "Diverse Yacht Services" 644 "Wema U.S.A dba KUS" 658 "Shenzhen Jiuzhou Himunication" 688 "Rockford" 699 "Harman International" 704 "JL Audio" 708 "Lars Thrane" 715 "Autonnic" 717 "Yacht Devices" 734 "REAP Systems" 735 "AEM Performance Electronics" 739 "LxNav" 741 "Littelfuse, Inc (formerly Carling Technologies)" 743 "DaeMyung" 744 "Woosung" 748 "ISOTTA IFRA srl" 773 "Clarion US" 776 "HMI Systems" 777 "Ocean Signal" 778 "Seakeeper" 781 "Poly Planar" 785 "Fischer Panda DE" 795 "Broyda Industries" 796 "Canadian Automotive" 797 "Tides Marine" 798 "Lumishore" 799 "Still Water Designs and Audio" 802 "BJ Technologies (Beneteau)" 803 "Gill Sensors" 811 "Blue Water Desalination" 815 "FLIR" 824 "Undheim Systems" 826 "Lewmar" 838 "TeamSurv" 844 "Fell Marine" 847 "Oceanvolt" 862 "Prospec" 868 "Data Panel" 890 "L3 Technologies" 894 "Rhodan Marine Systems" 896 "Nexfour Solutions" 905 "ASA Electronics" 909 "Marines Co (South Korea)" 911 "Nautic-on" 917 "Sentinel" 929 "JL Marine Systems" 930 "Ecotronix" 944 "Zontisa Marine" 951 "EXOR International" 962 "Timbolier Industries" 963 "TJC Micro" 968 "Cox Powertrain" 969 "Blue Seas" 981 "Kobelt Manufacturing" 992 "Blue Ocean IOT" 997 "Xenta Systems" 999 "Signal K" 1004 "Ultraflex" 1008 "Lintest SmartBoat" 1011 "Soundmax" 1020 "Team Italia Marine (Onyx Marine Automation s.r.l)" 1021 "Entratech" 1022 "ITC" 1029 "The Marine Guardian" 1047 "Sonic" 1051 "ProNav" 1053 "Vetus Maxwell INC." 1056 "Lithium Pros" 1059 "Boatrax" 1062 "Marol Co ltd" 1065 "CALYPSO Instruments" 1066 "Spot Zero Water" 1069 "Lithionics Battery" 1070 "Quick-teck Electronics" 1075 "Uniden America" 1083 "Nauticoncept" 1084 "Shadow-Caster LED lighting" 1085 "Wet Sounds" 1088 "E-T-A Circuit Breakers" 1092 "Scheiber" 1100 "Smart Yachts International Limited" 1109 "Dockmate" 1114 "Bobs Machine" 1118 "L3Harris ASV" 1119 "Balmar" 1120 "Elettromedia" 1127 "Electromaax" 1140 "Across Oceans Systems" 1145 "Kiwi Yachting" 1150 "BSB Artificial Intelligence" 1151 "Orca Technologies" 1154 "TBS Electronics" 1158 "Technoton Electroics" 1160 "MG Energy Systems" 1169 "Sea Machine Robotics" 1171 "Vista Manufacturing" 1183 "Zipwake" 1186 "Sailmon" 1192 "Airmoniq Pro Kft" 1194 "Sierra Marine" 1200 "Xinuo Information Technology (Xiamen)" 1218 "Septentrio" 1233 "NKE Marine Electronics" 1238 "SuperTrack Aps" 1239 "Honda Electronics" 1245 "Raritan Engineering" 1249 "Integrated Power Solutions AG" 1260 "Interactive Technologies" 1283 "LTG-Tech" 1299 "Energy Solutions (UK)" 1300 "WATT Fuel Cell" 1302 "Pro Mainer" 1305 "Dragonfly Energy" 1306 "Koden Electronics" 1311 "Humphree" 1316 "Hinkley Yachts" 1317 "Global Marine Management GmbH (GMM)" 1320 "Triskel Marine" 1330 "Warwick Control Technologies" 1331 "Dolphin Charger" 1337 "Barnacle Systems" 1348 "Radian IoT" 1353 "Ocean LED Marine" 1359 "BluNav" 1361 "OVA (Nantong Saiyang Electronics Co., Ltd)" 1368 "RAD Propulsion" 1369 "Electric Yacht" 1372 "Elco Motor Yachts" 1384 "Tecnoseal Foundry S.r.l" 1385 "Pro Charging Systems" 1389 "EVEX" 1398 "Gobius Sensor Technology" 1403 "Arco Marine" 1408 "Lenco Marine" 1413 "Naocontrol" 1417 "Revatek" 1438 "Aeolionics" 1439 "PredictWind" 1440 "Egis Mobile Electric" 1445 "Starboard Yacht Group" 1446 "Roswell Marine" 1451 "ePropulsion (Guangdong ePropulsion Technology Ltd.)" 1452 "Micro-Air" 1453 "Vital Battery" 1458 "Ride Controller" 1460 "Tocaro Blue" 1461 "Vanquish Yachts" 1471 "FT Technologies" 1478 "Alps Alpine" 1481 "E-Force Marine" 1482 "CMC Marine" 1483 "Nanjing Sandemarine Information Technology" 1850 "Teleflex Marine (SeaStar Solutions)" 1851 "Raymarine" 1852 "Navionics" 1853 "Japan Radio" 1854 "Northstar Technologies" 1855 "Furuno" 1856 "Trimble" 1857 "Simrad" 1858 "Litton" 1859 "Kvasar" 1860 "MMP" 1861 "Vector Cantech" 1862 "Yamaha Marine" 1863 "Faria Instruments" ;
VAL_ 2566889472 Industry_Code 0 "Global" 1 "Highway" 2 "Agriculture" 3 "Construction" 4 "Marine Industry" 5 "Industrial" ;
VAL_ 2566889728 Manufacturer_Code 69 "ARKS Enterprises" 78 "FW Murphy/Enovation Controls" 80 "Twin Disc" 85 "Kohler Power Systems" 88 "Hemisphere GPS" 135 "Airmar" 137 "Maretron" 140 "Lowrance" 144 "Mercury Marine" 147 "Nautibus Electronic" 148 "Blue Water Data" 154 "Westerbeke" 157 "ISSPRO" 161 "Offshore Systems (UK)" 163 "Evinrude/BRP" 165 "CPAC Systems" 168 "Xantrex Technology" 169 "Marlin Technologies" 172 "Yanmar Marine" 174 "Volvo Penta" 176 "Carling Technologies Inc. (Moritz Aerospace)" 185 "Beede Instruments" 192 "Floscan Instrument" 193 "Nobeltec" 198 "Mystic Valley Communications" 199 "Actia" 201 "Disenos Y Technologia" 211 "Digital Switching Systems" 215 "Xintex/Atena" 224 "EMMI NETWORK" 228 "ZF" 229 "Garmin" 233 "Yacht Monitoring Solutions" 235 "Sailormade Marine Telemetry/Tetra Technology" 243 "Eride" 257 "Honda Motor" 272 "Groco" 273 "Actisense" 274 "Amphenol LTW Technology" 275 "Navico" 283 "Hamilton Jet" 285 "Sea Recovery" 286 "Coelmo SRL Italy" 295 "BEP Marine" 304 "Empir Bus" 305 "NovAtel" 306 "Sleipner Motor" 307 "MBW Technologies" 315 "ICOM" 328 "Qwerty" 329 "Dief" 341 "Boening Automationstechnologie" 345 "Korean Maritime University" 351 "Thrane and Thrane" 355 "Mastervolt" 356 "Fischer Panda Generators" 358 "Victron Energy" 370 "Rolls Royce Marine" 373 "Electronic Design" 374 "Northern Lights" 378 "Glendinning" 381 "B & G" 384 "Rose Point Navigation Systems" 385 "Johnson Outdoors Marine Electronics Inc Geonav" 394 "Capi 2" 396 "Beyond Measure" 400 "Livorsi Marine" 404 "ComNav" 409 "Chetco" 419 "Fusion Electronics" 421 "Standard Horizon" 422 "True Heading" 426 "Egersund Marine Electronics" 427 "em-trak Marine Electronics" 431 "Tohatsu Co, JP" 437 "Digital Yacht" 438 "Comar Systems Limited" 440 "Cummins" 443 "VDO (aka Continental-Corporation)" 451 "Parker Hannifin aka Village Marine Tech" 459 "Alltek Marine Electronics" 460 "SAN GIORGIO S.E.I.N" 466 "Veethree Electronics & Marine" 470 "SI-TEX Marine Electronics" 471 "Sea Cross Marine" 475 "GME aka Standard Communications" 476 "Humminbird Marine Electronics" 478 "Ocean Sat" 481 "Chetco Digital Instruments" 493 "Watcheye" 499 "Lcj Capteurs" 502 "Attwood Marine" 503 "Naviop S.R.L." 504 "Vesper Marine" 510 "Marinesoft" 513 "Simarine" 517 "NoLand Engineering" 518 "Transas USA" 529 "National Instruments Korea" 530 "National Marine Electronics Association" 532 "Onwa Marine" 540 "Webasto" 571 "Marinecraft (South Korea)" 573 "McMurdo Group aka Orolia" 578 "Advansea" 579 "KVH" 580 "San Jose Technology" 583 "Yacht Control" 586 "Suzuki Motor" 591 "US Coast Guard" 595 "Ship Module aka Customware" 600 "Aquatic AV" 605 "Aventics" 606 "Intellian" 612 "SamwonIT" 614 "Arlt Tecnologies" 637 "Bavaria Yachts" 641 "Diverse Yacht Services" 644 "Wema U.S.A dba KUS" 658 "Shenzhen Jiuzhou Himunication" 688 "Rockford" 699 "Harman International" 704 "JL Audio" 708 "Lars Thrane" 715 "Autonnic" 717 "Yacht Devices" 734 "REAP Systems" 735 "AEM Performance Electronics" 739 "LxNav" 741 "Littelfuse, Inc (formerly Carling Technologies)" 743 "DaeMyung" 744 "Woosung" 748 "ISOTTA IFRA srl" 773 "Clarion US" 776 "HMI Systems" 777 "Ocean Signal" 778 "Seakeeper" 781 "Poly Planar" 785 "Fischer Panda DE" 795 "Broyda Industries" 796 "Canadian Automotive" 797 "Tides Marine" 798 "Lumishore" 799 "Still Water Designs and Audio" 802 "BJ Technologies (Beneteau)" 803 "Gill Sensors" 811 "Blue Water Desalination" 815 "FLIR" 824 "Undheim Systems" 826 "Lewmar" 838 "TeamSurv" 844 "Fell Marine" 847 "Oceanvolt" 862 "Prospec" 868 "Data Panel" 890 "L3 Technologies" 894 "Rhodan Marine Systems" 896 "Nexfour Solutions" 905 "ASA Electronics" 909 "Marines Co (South Korea)" 911 "Nautic-on" 917 "Sentinel" 929 "JL Marine Systems" 930 "Ecotronix" 944 "Zontisa Marine" 951 "EXOR International" 962 "Timbolier Industries" 963 "TJC Micro" 968 "Cox Powertrain" 969 "Blue Seas" 981 "Kobelt Manufacturing" 992 "Blue Ocean IOT" 997 "Xenta Systems" 999 "Signal K" 1004 "Ultraflex" 1008 "Lintest SmartBoat" 1011 "Soundmax" 1020 "Team Italia Marine (Onyx Marine Automation s.r.l)" 1021 "Entratech" 1022 "ITC" 1029 "The Marine Guardian" 1047 "Sonic" 1051 "ProNav" 1053 "Vetus Maxwell INC." 1056 "Lithium Pros" 1059 "Boatrax" 1062 "Marol Co ltd" 1065 "CALYPSO Instruments" 1066 "Spot Zero Water" 1069 "Lithionics Battery" 1070 "Quick-teck Electronics" 1075 "Uniden America" 1083 "Nauticoncept" 1084 "Shadow-Caster LED lighting" 1085 "Wet Sounds" 1088 "E-T-A Circuit Breakers" 1092 "Scheiber" 1100 "Smart Yachts International Limited" 1109 "Dockmate" 1114 "Bobs Machine" 1118 "L3Harris ASV" 1119 "Balmar" 1120 "Elettromedia" 1127 "Electromaax" 1140 "Across Oceans Systems" 1145 "Kiwi Yachting" 1150 "BSB Artificial Intelligence" 1151 "Orca Technologies" 1154 "TBS Electronics" 1158 "Technoton Electroics" 1160 "MG Energy Systems" 1169 "Sea Machine Robotics" 1171 "Vista Manufacturing" 1183 "Zipwake" 1186 "Sailmon" 1192 "Airmoniq Pro Kft" 1194 "Sierra Marine" 1200 "Xinuo Information Technology (Xiamen)" 1218 "Septentrio" 1233 "NKE Marine Electronics" 1238 "SuperTrack Aps" 1239 "Honda Electronics" 1245 "Raritan Engineering" 1249 "Integrated Power Solutions AG" 1260 "Interactive Technologies" 1283 "LTG-Tech" 1299 "Energy Solutions (UK)" 1300 "WATT Fuel Cell" 1302 "Pro Mainer" 1305 "Dragonfly Energy" 1306 "Koden Electronics" 1311 "Humphree" 1316 "Hinkley Yachts" 1317 "Global Marine Management GmbH (GMM)" 1320 "Triskel Marine" 1330 "Warwick Control Technologies" 1331 "Dolphin Charger" 1337 "Barnacle Systems" 1348 "Radian IoT" 1353 "Ocean LED Marine" 1359 "BluNav" 1361 "OVA (Nantong Saiyang Electronics Co., Ltd)" 1368 "RAD Propulsion" 1369 "Electric Yacht" 1372 "Elco Motor Yachts" 1384 "Tecnoseal Foundry S.r.l" 1385 "Pro Charging Systems" 1389 "EVEX" 1398 "Gobius Sensor Technology" 1403 "Arco Marine" 1408 "Lenco Marine" 1413 "Naocontrol" 1417 "Revatek" 1438 "Aeolionics" 1439 "PredictWind" 1440 "Egis Mobile Electric" 1445 "Starboard Yacht Group" 1446 "Roswell Marine" 1451 "ePropulsion (Guangdong ePropulsion Technology Ltd.)" 1452 "Micro-Air" 1453 "Vital Battery" 1458 "Ride Controller" 1460 "Tocaro Blue" 1461 "Vanquish Yachts" 1471 "FT Technologies" 1478 "Alps Alpine" 1481 "E-Force Marine" 1482 "CMC Marine" 1483 "Nanjing Sandemarine Information Technology" 1850 "Teleflex Marine (SeaStar Solutions)" 1851 "Raymarine" 1852 "Navionics" 1853 "Japan Radio" 1854 "Northstar Technologies" 1855 "Furuno" 1856 "Trimble" 1857 "Simrad" 1858 "Litton" 1859 "Kvasar" 1860 "MMP" 1861 "Vector Cantech" 1862 "Yamaha Marine" 1863 "Faria Instruments" ;
VAL_ 2566889728 Industry_Code 0 "Global" 1 "Highway" 2 "Agriculture" 3 "Construction" 4 "Marine Industry" 5 "Industrial" ;
VAL_ 2566897664 Manufacturer_Code 69 "ARKS Enterprises" 78 "FW Murphy/Enovation Controls" 80 "Twin Disc" 85 "Kohler Power Systems" 88 "Hemisphere GPS" 135 "Airmar" 137 "Maretron" 140 "Lowrance" 144 "Mercury Marine" 147 "Nautibus Electronic" 148 "Blue Water Data" 154 "Westerbeke" 157 "ISSPRO" 161 "Offshore Systems (UK)" 163 "Evinrude/BRP" 165 "CPAC Systems" 168 "Xantrex Technology" 169 "Marlin Technologies" 172 "Yanmar Marine" 174 "Volvo Penta" 176 "Carling Technologies Inc. (Moritz Aerospace)" 185 "Beede Instruments" 192 "Floscan Instrument" 193 "Nobeltec" 198 "Mystic Valley Communications" 199 "Actia" 201 "Disenos Y Technologia" 211 "Digital Switching Systems" 215 "Xintex/Atena" 224 "EMMI NETWORK" 228 "ZF" 229 "Garmin" 233 "Yacht Monitoring Solutions" 235 "Sailormade Marine Telemetry/Tetra Technology" 243 "Eride" 257 "Honda Motor" 272 "Groco" 273 "Actisense" 274 "Amphenol LTW Technology" 275 "Navico" 283 "Hamilton Jet" 285 "Sea Recovery" 286 "Coelmo SRL Italy" 295 "BEP Marine" 304 "Empir Bus" 305 "NovAtel" 306 "Sleipner Motor" 307 "MBW Technologies" 315 "ICOM" 328 "Qwerty" 329 "Dief" 341 "Boening Automationstechnologie" 345 "Korean Maritime University" 351 "Thrane and Thrane" 355 "Mastervolt" 356 "Fischer Panda Generators" 358 "Victron Energy" 370 "Rolls Royce Marine" 373 "Electronic Design" 374 "Northern Lights" 378 "Glendinning" 381 "B & G" 384 "Rose Point Navigation Systems" 385 "Johnson Outdoors Marine Electronics Inc Geonav" 394 "Capi 2" 396 "Beyond Measure" 400 "Livorsi Marine" 404 "ComNav" 409 "Chetco" 419 "Fusion Electronics" 421 "Standard Horizon" 422 "True Heading" 426 "Egersund Marine Electronics" 427 "em-trak Marine Electronics" 431 "Tohatsu Co, JP" 437 "Digital Yacht" 438 "Comar Systems Limited" 440 "Cummins" 443 "VDO (aka Continental-Corporation)" 451 "Parker Hannifin aka Village Marine Tech" 459 "Alltek Marine Electronics" 460 "SAN GIORGIO S.E.I.N" 466 "Veethree Electronics & Marine" 470 "SI-TEX Marine Electronics" 471 "Sea Cross Marine" 475 "GME aka Standard Communications" 476 "Humminbird Marine Electronics" 478 "Ocean Sat" 481 "Chetco Digital Instruments" 493 "Watcheye" 499 "Lcj Capteurs" 502 "Attwood Marine" 503 "Naviop S.R.L." 504 "Vesper Marine" 510 "Marinesoft" 513 "Simarine" 517 "NoLand Engineering" 518 "Transas USA" 529 "National Instruments Korea" 530 "National Marine Electronics Association" 532 "Onwa Marine" 540 "Webasto" 571 "Marinecraft (South Korea)" 573 "McMurdo Group aka Orolia" 578 "Advansea" 579 "KVH" 580 "San Jose Technology" 583 "Yacht Control" 586 "Suzuki Motor" 591 "US Coast Guard" 595 "Ship Module aka Customware" 600 "Aquatic AV" 605 "Aventics" 606 "Intellian" 612 "SamwonIT" 614 "Arlt Tecnologies" 637 "Bavaria Yachts" 641 "Diverse Yacht Services" 644 "Wema U.S.A dba KUS" 658 "Shenzhen Jiuzhou Himunication" 688 "Rockford" 699 "Harman International" 704 "JL Audio" 708 "Lars Thrane" 715 "Autonnic" 717 "Yacht Devices" 734 "REAP Systems" 735 "AEM Performance Electronics" 739 "LxNav" 741 "Littelfuse, Inc (formerly Carling Technologies)" 743 "DaeMyung" 744 "Woosung" 748 "ISOTTA IFRA srl" 773 "Clarion US" 776 "HMI Systems" 777 "Ocean Signal" 778 "Seakeeper" 781 "Poly Planar" 785 "Fischer Panda DE" 795 "Broyda Industries" 796 "Canadian Automotive" 797 "Tides Marine" 798 "Lumishore" 799 "Still Water Designs and Audio" 802 "BJ Technologies (Beneteau)" 803 "Gill Sensors" 811 "Blue Water Desalination" 815 "FLIR" 824 "Undheim Systems" 826 "Lewmar" 838 "TeamSurv" 844 "Fell Marine" 847 "Oceanvolt" 862 "Prospec" 868 "Data Panel" 890 "L3 Technologies" 894 "Rhodan Marine Systems" 896 "Nexfour Solutions" 905 "ASA Electronics" 909 "Marines Co (South Korea)" 911 "Nautic-on" 917 "Sentinel" 929 "JL Marine Systems" 930 "Ecotronix" 944 "Zontisa Marine" 951 "EXOR International" 962 "Timbolier Industries" 963 "TJC Micro" 968 "Cox Powertrain" 969 "Blue Seas" 981 "Kobelt Manufacturing" 992 "Blue Ocean IOT" 997 "Xenta Systems" 999 "Signal K" 1004 "Ultraflex" 1008 "Lintest SmartBoat" 1011 "Soundmax" 1020 "Team Italia Marine (Onyx Marine Automation s.r.l)" 1021 "Entratech" 1022 "ITC" 1029 "The Marine Guardian" 1047 "Sonic" 1051 "ProNav" 1053 "Vetus Maxwell INC." 1056 "Lithium Pros" 1059 "Boatrax" 1062 "Marol Co ltd" 1065 "CALYPSO Instruments" 1066 "Spot Zero Water" 1069 "Lithionics Battery" 1070 "Quick-teck Electronics" 1075 "Uniden America" 1083 "Nauticoncept" 1084 "Shadow-Caster LED lighting" 1085 "Wet Sounds" 1088 "E-T-A Circuit Breakers" 1092 "Scheiber" 1100 "Smart Yachts International Limited" 1109 "Dockmate" 1114 "Bobs Machine" 1118 "L3Harris ASV" 1119 "Balmar" 1120 "Elettromedia" 1127 "Electromaax" 1140 "Across Oceans Systems" 1145 "Kiwi Yachting" 1150 "BSB Artificial Intelligence" 1151 "Orca Technologies" 1154 "TBS Electronics" 1158 "Technoton Electroics" 1160 "MG Energy Systems" 1169 "Sea Machine Robotics" 1171 "Vista Manufacturing" 1183 "Zipwake" 1186 "Sailmon" 1192 "Airmoniq Pro Kft" 1194 "Sierra Marine" 1200 "Xinuo Information Technology (Xiamen)" 1218 "Septentrio" 1233 "NKE Marine Electronics" 1238 "SuperTrack Aps" 1239 "Honda Electronics" 1245 "Raritan Engineering" 1249 "Integrated Power Solutions AG" 1260 "Interactive Technologies" 1283 "LTG-Tech" 1299 "Energy Solutions (UK)" 1300 "WATT Fuel Cell" 1302 "Pro Mainer" 1305 "Dragonfly Energy" 1306 "Koden Electronics" 1311 "Humphree" 1316 "Hinkley Yachts" 1317 "Global Marine Management GmbH (GMM)" 1320 "Triskel Marine" 1330 "Warwick Control Technologies" 1331 "Dolphin Charger" 1337 "Barnacle Systems" 1348 "Radian IoT" 1353 "Ocean LED Marine" 1359 "BluNav" 1361 "OVA (Nantong Saiyang Electronics Co., Ltd)" 1368 "RAD Propulsion" 1369 "Electric Yacht" 1372 "Elco Motor Yachts" 1384 "Tecnoseal Foundry S.r.l" 1385 "Pro Charging Systems" 1389 "EVEX" 1398 "Gobius Sensor Technology" 1403 "Arco Marine" 1408 "Lenco Marine" 1413 "Naocontrol" 1417 "Revatek" 1438 "Aeolionics" 1439 "PredictWind" 1440 "Egis Mobile Electric" 1445 "Starboard Yacht Group" 1446 "Roswell Marine" 1451 "ePropulsion (Guangdong ePropulsion Technology Ltd.)" 1452 "Micro-Air" 1453 "Vital Battery" 1458 "Ride Controller" 1460 "Tocaro Blue" 1461 "Vanquish Yachts" 1471 "FT Technologies" 1478 "Alps Alpine" 1481 "E-Force Marine" 1482 "CMC Marine" 1483 "Nanjing Sandemarine Information Technology" 1850 "Teleflex Marine (SeaStar Solutions)" 1851 "Raymarine" 1852 "Navionics" 1853 "Japan Radio" 1854 "Northstar Technologies" 1855 "Furuno" 1856 "Trimble" 1857 "Simrad" 1858 "Litton" 1859 "Kvasar" 1860 "MMP" 1861 "Vector Cantech" 1862 "Yamaha Marine" 1863 "Faria Instruments" ;
VAL_ 2566897664 Industry_Code 0 "Global" 1 "Highway" 2 "Agriculture" 3 "Construction" 4 "Marine Industry" 5 "Industrial" ;
VAL_ 2566899712 Manufacturer_Code 69 "ARKS Enterprises" 78 "FW Murphy/Enovation Controls" 80 "Twin Disc" 85 "Kohler Power Systems" 88 "Hemisphere GPS" 135 "Airmar" 137 "Maretron" 140 "Lowrance" 144 "Mercury Marine" 147 "Nautibus Electronic" 148 "Blue Water Data" 154 "Westerbeke" 157 "ISSPRO" 161 "Offshore Systems (UK)" 163 "Evinrude/BRP" 165 "CPAC Systems" 168 "Xantrex Technology" 169 "Marlin Technologies" 172 "Yanmar Marine" 174 "Volvo Penta" 176 "Carling Technologies Inc. (Moritz Aerospace)" 185 "Beede Instruments" 192 "Floscan Instrument" 193 "Nobeltec" 198 "Mystic Valley Communications" 199 "Actia" 201 "Disenos Y Technologia" 211 "Digital Switching Systems" 215 "Xintex/Atena" 224 "EMMI NETWORK" 228 "ZF" 229 "Garmin" 233 "Yacht Monitoring Solutions" 235 "Sailormade Marine Telemetry/Tetra Technology" 243 "Eride" 257 "Honda Motor" 272 "Groco" 273 "Actisense" 274 "Amphenol LTW Technology" 275 "Navico" 283 "Hamilton Jet" 285 "Sea Recovery" 286 "Coelmo SRL Italy" 295 "BEP Marine" 304 "Empir Bus" 305 "NovAtel" 306 "Sleipner Motor" 307 "MBW Technologies" 315 "ICOM" 328 "Qwerty" 329 "Dief" 341 "Boening Automationstechnologie" 345 "Korean Maritime University" 351 "Thrane and Thrane" 355 "Mastervolt" 356 "Fischer Panda Generators" 358 "Victron Energy" 370 "Rolls Royce Marine" 373 "Electronic Design" 374 "Northern Lights" 378 "Glendinning" 381 "B & G" 384 "Rose Point Navigation Systems" 385 "Johnson Outdoors Marine Electronics Inc Geonav" 394 "Capi 2" 396 "Beyond Measure" 400 "Livorsi Marine" 404 "ComNav" 409 "Chetco" 419 "Fusion Electronics" 421 "Standard Horizon" 422 "True Heading" 426 "Egersund Marine Electronics" 427 "em-trak Marine Electronics" 431 "Tohatsu Co, JP" 437 "Digital Yacht" 438 "Comar Systems Limited" 440 "Cummins" 443 "VDO (aka Continental-Corporation)" 451 "Parker Hannifin aka Village Marine Tech" 459 "Alltek Marine Electronics" 460 "SAN GIORGIO S.E.I.N" 466 "Veethree Electronics & Marine" 470 "SI-TEX Marine Electronics" 471 "Sea Cross Marine" 475 "GME aka Standard Communications" 476 "Humminbird Marine Electronics" 478 "Ocean Sat" 481 "Chetco Digital Instruments" 493 "Watcheye" 499 "Lcj Capteurs" 502 "Attwood Marine" 503 "Naviop S.R.L." 504 "Vesper Marine" 510 "Marinesoft" 513 "Simarine" 517 "NoLand Engineering" 518 "Transas USA" 529 "National Instruments Korea" 530 "National Marine Electronics Association" 532 "Onwa Marine" 540 "Webasto" 571 "Marinecraft (South Korea)" 573 "McMurdo Group aka Orolia" 578 "Advansea" 579 "KVH" 580 "San Jose Technology" 583 "Yacht Control" 586 "Suzuki Motor" 591 "US Coast Guard" 595 "Ship Module aka Customware" 600 "Aquatic AV" 605 "Aventics" 606 "Intellian" 612 "SamwonIT" 614 "Arlt Tecnologies" 637 "Bavaria Yachts" 641 "Diverse Yacht Services" 644 "Wema U.S.A dba KUS" 658 "Shenzhen Jiuzhou Himunication" 688 "Rockford" 699 "Harman International" 704 "JL Audio" 708 "Lars Thrane" 715 "Autonnic" 717 "Yacht Devices" 734 "REAP Systems" 735 "AEM Performance Electronics" 739 "LxNav" 741 "Littelfuse, Inc (formerly Carling Technologies)" 743 "DaeMyung" 744 "Woosung" 748 "ISOTTA IFRA srl" 773 "Clarion US" 776 "HMI Systems" 777 "Ocean Signal" 778 "Seakeeper" 781 "Poly Planar" 785 "Fischer Panda DE" 795 "Broyda Industries" 796 "Canadian Automotive" 797 "Tides Marine" 798 "Lumishore" 799 "Still Water Designs and Audio" 802 "BJ Technologies (Beneteau)" 803 "Gill Sensors" 811 "Blue Water Desalination" 815 "FLIR" 824 "Undheim Systems" 826 "Lewmar" 838 "TeamSurv" 844 "Fell Marine" 847 "Oceanvolt" 862 "Prospec" 868 "Data Panel" 890 "L3 Technologies" 894 "Rhodan Marine Systems" 896 "Nexfour Solutions" 905 "ASA Electronics" 909 "Marines Co (South Korea)" 911 "Nautic-on" 917 "Sentinel" 929 "JL Marine Systems" 930 "Ecotronix" 944 "Zontisa Marine" 951 "EXOR International" 962 "Timbolier Industries" 963 "TJC Micro" 968 "Cox Powertrain" 969 "Blue Seas" 981 "Kobelt Manufacturing" 992 "Blue Ocean IOT" 997 "Xenta Systems" 999 "Signal K" 1004 "Ultraflex" 1008 "Lintest SmartBoat" 1011 "Soundmax" 1020 "Team Italia Marine (Onyx Marine Automation s.r.l)" 1021 "Entratech" 1022 "ITC" 1029 "The Marine Guardian" 1047 "Sonic" 1051 "ProNav" 1053 "Vetus Maxwell INC." 1056 "Lithium Pros" 1059 "Boatrax" 1062 "Marol Co ltd" 1065 "CALYPSO Instruments" 1066 "Spot Zero Water" 1069 "Lithionics Battery" 1070 "Quick-teck Electronics" 1075 "Uniden America" 1083 "Nauticoncept" 1084 "Shadow-Caster LED lighting" 1085 "Wet Sounds" 1088 "E-T-A Circuit Breakers" 1092 "Scheiber" 1100 "Smart Yachts International Limited" 1109 "Dockmate" 1114 "Bobs Machine" 1118 "L3Harris ASV" 1119 "Balmar" 1120 "Elettromedia" 1127 "Electromaax" 1140 "Across Oceans Systems" 1145 "Kiwi Yachting" 1150 "BSB Artificial Intelligence" 1151 "Orca Technologies" 1154 "TBS Electronics" 1158 "Technoton Electroics" 1160 "MG Energy Systems" 1169 "Sea Machine Robotics" 1171 "Vista Manufacturing" 1183 "Zipwake" 1186 "Sailmon" 1192 "Airmoniq Pro Kft" 1194 "Sierra Marine" 1200 "Xinuo Information Technology (Xiamen)" 1218 "Septentrio" 1233 "NKE Marine Electronics" 1238 "SuperTrack Aps" 1239 "Honda Electronics" 1245 "Raritan Engineering" 1249 "Integrated Power Solutions AG" 1260 "Interactive Technologies" 1283 "LTG-Tech" 1299 "Energy Solutions (UK)" 1300 "WATT Fuel Cell" 1302 "Pro Mainer" 1305 "Dragonfly Energy" 1306 "Koden Electronics" 1311 "Humphree" 1316 "Hinkley Yachts" 1317 "Global Marine Management GmbH (GMM)" 1320 "Triskel Marine" 1330 "Warwick Control Technologies" 1331 "Dolphin Charger" 1337 "Barnacle Systems" 1348 "Radian IoT" 1353 "Ocean LED Marine" 1359 "BluNav" 1361 "OVA (Nantong Saiyang Electronics Co., Ltd)" 1368 "RAD Propulsion" 1369 "Electric Yacht" 1372 "Elco Motor Yachts" 1384 "Tecnoseal Foundry S.r.l" 1385 "Pro Charging Systems" 1389 "EVEX" 1398 "Gobius Sensor Technology" 1403 "Arco Marine" 1408 "Lenco Marine" 1413 "Naocontrol" 1417 "Revatek" 1438 "Aeolionics" 1439 "PredictWind" 1440 "Egis Mobile Electric" 1445 "Starboard Yacht Group" 1446 "Roswell Marine" 1451 "ePropulsion (Guangdong ePropulsion Technology Ltd.)" 1452 "Micro-Air" 1453 "Vital Battery" 1458 "Ride Controller" 1460 "Tocaro Blue" 1461 "Vanquish Yachts" 1471 "FT Technologies" 1478 "Alps Alpine" 1481 "E-Force Marine" 1482 "CMC Marine" 1483 "Nanjing Sandemarine Information Technology" 1850 "Teleflex Marine (SeaStar Solutions)" 1851 "Raymarine" 1852 "Navionics" 1853 "Japan Radio" 1854 "Northstar Technologies" 1855 "Furuno" 1856 "Trimble" 1857 "Simrad" 1858 "Litton" 1859 "Kvasar" 1860 "MMP" 1861 "Vector Cantech" 1862 "Yamaha Marine" 1863 "Faria Instruments" ;
VAL_ 2566899712 Industry_Code 0 "Global" 1 "Highway" 2 "Agriculture" 3 "Construction" 4 "Marine Industry" 5 "Industrial" ;
VAL_ 2381119488 Function_Code 0 "Request" 1 "Command" 2 "Acknowledge" 3 "Read Fields" 4 "Read Fields Reply" 5 "Write Fields" 6 "Write Fields Reply" ;
VAL_ 2381119488 PGN_error_code 0 "Acknowledge" 1 "PGN not supported" 2 "PGN not available" 3 "Access denied" 4 "Not supported" 5 "Tag not supported" 6 "Read or Write not supported" ;
VAL_ 2381119488 Transmission_interval_Priority_error_code 0 "Acknowledge" 1 "Transmit Interval/Priority not supported" 2 "Transmit Interval too low" 3 "Access denied" 4 "Not supported" ;
VAL_ 2381119488 Function_Code 0 "Request" 1 "Command" 2 "Acknowledge" 3 "Read Fields" 4 "Read Fields Reply" 5 "Write Fields" 6 "Write Fields Reply" ;
VAL_ 2381119488 Priority 0 "0" 1 "1" 2 "2" 3 "3" 4 "4" 5 "5" 6 "6" 7 "7" 8 "Leave unchanged" 9 "Reset to default" ;
VAL_ 2381119488 Function_Code 0 "Request" 1 "Command" 2 "Acknowledge" 3 "Read Fields" 4 "Read Fields Reply" 5 "Write Fields" 6 "Write Fields Reply" ;
VAL_ 2381119488 Manufacturer_Code 69 "ARKS Enterprises" 78 "FW Murphy/Enovation Controls" 80 "Twin Disc" 85 "Kohler Power Systems" 88 "Hemisphere GPS" 135 "Airmar" 137 "Maretron" 140 "Lowrance" 144 "Mercury Marine" 147 "Nautibus Electronic" 148 "Blue Water Data" 154 "Westerbeke" 157 "ISSPRO" 161 "Offshore Systems (UK)" 163 "Evinrude/BRP" 165 "CPAC Systems" 168 "Xantrex Technology" 169 "Marlin Technologies" 172 "Yanmar Marine" 174 "Volvo Penta" 176 "Carling Technologies Inc. (Moritz Aerospace)" 185 "Beede Instruments" 192 "Floscan Instrument" 193 "Nobeltec" 198 "Mystic Valley Communications" 199 "Actia" 201 "Disenos Y Technologia" 211 "Digital Switching Systems" 215 "Xintex/Atena" 224 "EMMI NETWORK" 228 "ZF" 229 "Garmin" 233 "Yacht Monitoring Solutions" 235 "Sailormade Marine Telemetry/Tetra Technology" 243 "Eride" 257 "Honda Motor" 272 "Groco" 273 "Actisense" 274 "Amphenol LTW Technology" 275 "Navico" 283 "Hamilton Jet" 285 "Sea Recovery" 286 "Coelmo SRL Italy" 295 "BEP Marine" 304 "Empir Bus" 305 "NovAtel" 306 "Sleipner Motor" 307 "MBW Technologies" 315 "ICOM" 328 "Qwerty" 329 "Dief" 341 "Boening Automationstechnologie" 345 "Korean Maritime University" 351 "Thrane and Thrane" 355 "Mastervolt" 356 "Fischer Panda Generators" 358 "Victron Energy" 370 "Rolls Royce Marine" 373 "Electronic Design" 374 "Northern Lights" 378 "Glendinning" 381 "B & G" 384 "Rose Point Navigation Systems" 385 "Johnson Outdoors Marine Electronics Inc Geonav" 394 "Capi 2" 396 "Beyond Measure" 400 "Livorsi Marine" 404 "ComNav" 409 "Chetco" 419 "Fusion Electronics" 421 "Standard Horizon" 422 "True Heading" 426 "Egersund Marine Electronics" 427 "em-trak Marine Electronics" 431 "Tohatsu Co, JP" 437 "Digital Yacht" 438 "Comar Systems Limited" 440 "Cummins" 443 "VDO (aka Continental-Corporation)" 451 "Parker Hannifin aka Village Marine Tech" 459 "Alltek Marine Electronics" 460 "SAN GIORGIO S.E.I.N" 466 "Veethree Electronics & Marine" 470 "SI-TEX Marine Electronics" 471 "Sea Cross Marine" 475 "GME aka Standard Communications" 476 "Humminbird Marine Electronics" 478 "Ocean Sat" 481 "Chetco Digital Instruments" 493 "Watcheye" 499 "Lcj Capteurs" 502 "Attwood Marine" 503 "Naviop S.R.L." 504 "Vesper Marine" 510 "Marinesoft" 513 "Simarine" 517 "NoLand Engineering" 518 "Transas USA" 529 "National Instruments Korea" 530 "National Marine Electronics Association" 532 "Onwa Marine" 540 "Webasto" 571 "Marinecraft (South Korea)" 573 "McMurdo Group aka Orolia" 578 "Advansea" 579 "KVH" 580 "San Jose Technology" 583 "Yacht Control" 586 "Suzuki Motor" 591 "US Coast Guard" 595 "Ship Module aka Customware" 600 "Aquatic AV" 605 "Aventics" 606 "Intellian" 612 "SamwonIT" 614 "Arlt Tecnologies" 637 "Bavaria Yachts" 641 "Diverse Yacht Services" 644 "Wema U.S.A dba KUS" 658 "Shenzhen Jiuzhou Himunication" 688 "Rockford" 699 "Harman International" 704 "JL Audio" 708 "Lars Thrane" 715 "Autonnic" 717 "Yacht Devices" 734 "REAP Systems" 735 "AEM Performance Electronics" 739 "LxNav" 741 "Littelfuse, Inc (formerly Carling Technologies)" 743 "DaeMyung" 744 "Woosung" 748 "ISOTTA IFRA srl" 773 "Clarion US" 776 "HMI Systems" 777 "Ocean Signal" 778 "Seakeeper" 781 "Poly Planar" 785 "Fischer Panda DE" 795 "Broyda Industries" 796 "Canadian Automotive" 797 "Tides Marine" 798 "Lumishore" 799 "Still Water Designs and Audio" 802 "BJ Technologies (Beneteau)" 803 "Gill Sensors" 811 "Blue Water Desalination" 815 "FLIR" 824 "Undheim Systems" 826 "Lewmar" 838 "TeamSurv" 844 "Fell Marine" 847 "Oceanvolt" 862 "Prospec" 868 "Data Panel" 890 "L3 Technologies" 894 "Rhodan Marine Systems" 896 "Nexfour Solutions" 905 "ASA Electronics" 909 "Marines Co (South Korea)" 911 "Nautic-on" 917 "Sentinel" 929 "JL Marine Systems" 930 "Ecotronix" 944 "Zontisa Marine" 951 "EXOR International" 962 "Timbolier Industries" 963 "TJC Micro" 968 "Cox Powertrain" 969 "Blue Seas" 981 "Kobelt Manufacturing" 992 "Blue Ocean IOT" 997 "Xenta Systems" 999 "Signal K" 1004 "Ultraflex" 1008 "Lintest SmartBoat" 1011 "Soundmax" 1020 "Team Italia Marine (Onyx Marine Automation s.r.l)" 1021 "Entratech" 1022 "ITC" 1029 "The Marine Guardian" 1047 "Sonic" 1051 "ProNav" 1053 "Vetus Maxwell INC." 1056 "Lithium Pros" 1059 "Boatrax" 1062 "Marol Co ltd" 1065 "CALYPSO Instruments" 1066 "Spot Zero Water" 1069 "Lithionics Battery" 1070 "Quick-teck Electronics" 1075 "Uniden America" 1083 "Nauticoncept" 1084 "Shadow-Caster LED lighting" 1085 "Wet Sounds" 1088 "E-T-A Circuit Breakers" 1092 "Scheiber" 1100 "Smart Yachts International Limited" 1109 "Dockmate" 1114 "Bobs Machine" 1118 "L3Harris ASV" 1119 "Balmar" 1120 "Elettromedia" 1127 "Electromaax" 1140 "Across Oceans Systems" 1145 "Kiwi Yachting" 1150 "BSB Artificial Intelligence" 1151 "Orca Technologies" 1154 "TBS Electronics" 1158 "Technoton Electroics" 1160 "MG Energy Systems" 1169 "Sea Machine Robotics" 1171 "Vista Manufacturing" 1183 "Zipwake" 1186 "Sailmon" 1192 "Airmoniq Pro Kft" 1194 "Sierra Marine" 1200 "Xinuo Information Technology (Xiamen)" 1218 "Septentrio" 1233 "NKE Marine Electronics" 1238 "SuperTrack Aps" 1239 "Honda Electronics" 1245 "Raritan Engineering" 1249 "Integrated Power Solutions AG" 1260 "Interactive Technologies" 1283 "LTG-Tech" 1299 "Energy Solutions (UK)" 1300 "WATT Fuel Cell" 1302 "Pro Mainer" 1305 "Dragonfly Energy" 1306 "Koden Electronics" 1311 "Humphree" 1316 "Hinkley Yachts" 1317 "Global Marine Management GmbH (GMM)" 1320 "Triskel Marine" 1330 "Warwick Control Technologies" 1331 "Dolphin Charger" 1337 "Barnacle Systems" 1348 "Radian IoT" 1353 "Ocean LED Marine" 1359 "BluNav" 1361 "OVA (Nantong Saiyang Electronics Co., Ltd)" 1368 "RAD Propulsion" 1369 "Electric Yacht" 1372 "Elco Motor Yachts" 1384 "Tecnoseal Foundry S.r.l" 1385 "Pro Charging Systems" 1389 "EVEX" 1398 "Gobius Sensor Technology" 1403 "Arco Marine" 1408 "Lenco Marine" 1413 "Naocontrol" 1417 "Revatek" 1438 "Aeolionics" 1439 "PredictWind" 1440 "Egis Mobile Electric" 1445 "Starboard Yacht Group" 1446 "Roswell Marine" 1451 "ePropulsion (Guangdong ePropulsion Technology Ltd.)" 1452 "Micro-Air" 1453 "Vital Battery" 1458 "Ride Controller" 1460 "Tocaro Blue" 1461 "Vanquish Yachts" 1471 "FT Technologies" 1478 "Alps Alpine" 1481 "E-Force Marine" 1482 "CMC Marine" 1483 "Nanjing Sandemarine Information Technology" 1850 "Teleflex Marine (SeaStar Solutions)" 1851 "Raymarine" 1852 "Navionics" 1853 "Japan Radio" 1854 "Northstar Technologies" 1855 "Furuno" 1856 "Trimble" 1857 "Simrad" 1858 "Litton" 1859 "Kvasar" 1860 "MMP" 1861 "Vector Cantech" 1862 "Yamaha Marine" 1863 "Faria Instruments" ;
VAL_ 2381119488 Industry_Code 0 "Global" 1 "Highway" 2 "Agriculture" 3 "Construction" 4 "Marine Industry" 5 "Industrial" ;
VAL_ 2381119488 Function_Code 0 "Request" 1 "Command" 2 "Acknowledge" 3 "Read Fields" 4 "Read Fields Reply" 5 "Write Fields" 6 "Write Fields Reply" ;
VAL_ 2381119488 Manufacturer_Code 69 "ARKS Enterprises" 78 "FW Murphy/Enovation Controls" 80 "Twin Disc" 85 "Kohler Power Systems" 88 "Hemisphere GPS" 135 "Airmar" 137 "Maretron" 140 "Lowrance" 144 "Mercury Marine" 147 "Nautibus Electronic" 148 "Blue Water Data" 154 "Westerbeke" 157 "ISSPRO" 161 "Offshore Systems (UK)" 163 "Evinrude/BRP" 165 "CPAC Systems" 168 "Xantrex Technology" 169 "Marlin Technologies" 172 "Yanmar Marine" 174 "Volvo Penta" 176 "Carling Technologies Inc. (Moritz Aerospace)" 185 "Beede Instruments" 192 "Floscan Instrument" 193 "Nobeltec" 198 "Mystic Valley Communications" 199 "Actia" 201 "Disenos Y Technologia" 211 "Digital Switching Systems" 215 "Xintex/Atena" 224 "EMMI NETWORK" 228 "ZF" 229 "Garmin" 233 "Yacht Monitoring Solutions" 235 "Sailormade Marine Telemetry/Tetra Technology" 243 "Eride" 257 "Honda Motor" 272 "Groco" 273 "Actisense" 274 "Amphenol LTW Technology" 275 "Navico" 283 "Hamilton Jet" 285 "Sea Recovery" 286 "Coelmo SRL Italy" 295 "BEP Marine" 304 "Empir Bus" 305 "NovAtel" 306 "Sleipner Motor" 307 "MBW Technologies" 315 "ICOM" 328 "Qwerty" 329 "Dief" 341 "Boening Automationstechnologie" 345 "Korean Maritime University" 351 "Thrane and Thrane" 355 "Mastervolt" 356 "Fischer Panda Generators" 358 "Victron Energy" 370 "Rolls Royce Marine" 373 "Electronic Design" 374 "Northern Lights" 378 "Glendinning" 381 "B & G" 384 "Rose Point Navigation Systems" 385 "Johnson Outdoors Marine Electronics Inc Geonav" 394 "Capi 2" 396 "Beyond Measure" 400 "Livorsi Marine" 404 "ComNav" 409 "Chetco" 419 "Fusion Electronics" 421 "Standard Horizon" 422 "True Heading" 426 "Egersund Marine Electronics" 427 "em-trak Marine Electronics" 431 "Tohatsu Co, JP" 437 "Digital Yacht" 438 "Comar Systems Limited" 440 "Cummins" 443 "VDO (aka Continental-Corporation)" 451 "Parker Hannifin aka Village Marine Tech" 459 "Alltek Marine Electronics" 460 "SAN GIORGIO S.E.I.N" 466 "Veethree Electronics & Marine" 470 "SI-TEX Marine Electronics" 471 "Sea Cross Marine" 475 "GME aka Standard Communications" 476 "Humminbird Marine Electronics" 478 "Ocean Sat" 481 "Chetco Digital Instruments" 493 "Watcheye" 499 "Lcj Capteurs" 502 "Attwood Marine" 503 "Naviop S.R.L." 504 "Vesper Marine" 510 "Marinesoft" 513 "Simarine" 517 "NoLand Engineering" 518 "Transas USA" 529 "National Instruments Korea" 530 "National Marine Electronics Association" 532 "Onwa Marine" 540 "Webasto" 571 "Marinecraft (South Korea)" 573 "McMurdo Group aka Orolia" 578 "Advansea" 579 "KVH" 580 "San Jose Technology" 583 "Yacht Control" 586 "Suzuki Motor" 591 "US Coast Guard" 595 "Ship Module aka Customware" 600 "Aquatic AV" 605 "Aventics" 606 "Intellian" 612 "SamwonIT" 614 "Arlt Tecnologies" 637 "Bavaria Yachts" 641 "Diverse Yacht Services" 644 "Wema U.S.A dba KUS" 658 "Shenzhen Jiuzhou Himunication" 688 "Rockford" 699 "Harman International" 704 "JL Audio" 708 "Lars Thrane" 715 "Autonnic" 717 "Yacht Devices" 734 "REAP Systems" 735 "AEM Performance Electronics" 739 "LxNav" 741 "Littelfuse, Inc (formerly Carling Technologies)" 743 "DaeMyung" 744 "Woosung" 748 "ISOTTA IFRA srl" 773 "Clarion US" 776 "HMI Systems" 777 "Ocean Signal" 778 "Seakeeper" 781 "Poly Planar" 785 "Fischer Panda DE" 795 "Broyda Industries" 796 "Canadian Automotive" 797 "Tides Marine" 798 "Lumishore" 799 "Still Water Designs and Audio" 802 "BJ Technologies (Beneteau)" 803 "Gill Sensors" 811 "Blue Water Desalination" 815 "FLIR" 824 "Undheim Systems" 826 "Lewmar" 838 "TeamSurv" 844 "Fell Marine" 847 "Oceanvolt" 862 "Prospec" 868 "Data Panel" 890 "L3 Technologies" 894 "Rhodan Marine Systems" 896 "Nexfour Solutions" 905 "ASA Electronics" 909 "Marines Co (South Korea)" 911 "Nautic-on" 917 "Sentinel" 929 "JL Marine Systems" 930 "Ecotronix" 944 "Zontisa Marine" 951 "EXOR International" 962 "Timbolier Industries" 963 "TJC Micro" 968 "Cox Powertrain" 969 "Blue Seas" 981 "Kobelt Manufacturing" 992 "Blue Ocean IOT" 997 "Xenta Systems" 999 "Signal K" 1004 "Ultraflex" 1008 "Lintest SmartBoat" 1011 "Soundmax" 1020 "Team Italia Marine (Onyx Marine Automation s.r.l)" 1021 "Entratech" 1022 "ITC" 1029 "The Marine Guardian" 1047 "Sonic" 1051 "ProNav" 1053 "Vetus Maxwell INC." 1056 "Lithium Pros" 1059 "Boatrax" 1062 "Marol Co ltd" 1065 "CALYPSO Instruments" 1066 "Spot Zero Water" 1069 "Lithionics Battery" 1070 "Quick-teck Electronics" 1075 "Uniden America" 1083 "Nauticoncept" 1084 "Shadow-Caster LED lighting" 1085 "Wet Sounds" 1088 "E-T-A Circuit Breakers" 1092 "Scheiber" 1100 "Smart Yachts International Limited" 1109 "Dockmate" 1114 "Bobs Machine" 1118 "L3Harris ASV" 1119 "Balmar" 1120 "Elettromedia" 1127 "Electromaax" 1140 "Across Oceans Systems" 1145 "Kiwi Yachting" 1150 "BSB Artificial Intelligence" 1151 "Orca Technologies" 1154 "TBS Electronics" 1158 "Technoton Electroics" 1160 "MG Energy Systems" 1169 "Sea Machine Robotics" 1171 "Vista Manufacturing" 1183 "Zipwake" 1186 "Sailmon" 1192 "Airmoniq Pro Kft" 1194 "Sierra Marine" 1200 "Xinuo Information Technology (Xiamen)" 1218 "Septentrio" 1233 "NKE Marine Electronics" 1238 "SuperTrack Aps" 1239 "Honda Electronics" 1245 "Raritan Engineering" 1249 "Integrated Power Solutions AG" 1260 "Interactive Technologies" 1283 "LTG-Tech" 1299 "Energy Solutions (UK)" 1300 "WATT Fuel Cell" 1302 "Pro Mainer" 1305 "Dragonfly Energy" 1306 "Koden Electronics" 1311 "Humphree" 1316 "Hinkley Yachts" 1317 "Global Marine Management GmbH (GMM)" 1320 "Triskel Marine" 1330 "Warwick Control Technologies" 1331 "Dolphin Charger" 1337 "Barnacle Systems" 1348 "Radian IoT" 1353 "Ocean LED Marine" 1359 "BluNav" 1361 "OVA (Nantong Saiyang Electronics Co., Ltd)" 1368 "RAD Propulsion" 1369 "Electric Yacht" 1372 "Elco Motor Yachts" 1384 "Tecnoseal Foundry S.r.l" 1385 "Pro Charging Systems" 1389 "EVEX" 1398 "Gobius Sensor Technology" 1403 "Arco Marine" 1408 "Lenco Marine" 1413 "Naocontrol" 1417 "Revatek" 1438 "Aeolionics" 1439 "PredictWind" 1440 "Egis Mobile Electric" 1445 "Starboard Yacht Group" 1446 "Roswell Marine" 1451 "ePropulsion (Guangdong ePropulsion Technology Ltd.)" 1452 "Micro-Air" 1453 "Vital Battery" 1458 "Ride Controller" 1460 "Tocaro Blue" 1461 "Vanquish Yachts" 1471 "FT Technologies" 1478 "Alps Alpine" 1481 "E-Force Marine" 1482 "CMC Marine" 1483 "Nanjing Sandemarine Information Technology" 1850 "Teleflex Marine (SeaStar Solutions)" 1851 "Raymarine" 1852 "Navionics" 1853 "Japan Radio" 1854 "Northstar Technologies" 1855 "Furuno" 1856 "Trimble" 1857 "Simrad" 1858 "Litton" 1859 "Kvasar" 1860 "MMP" 1861 "Vector Cantech" 1862 "Yamaha Marine" 1863 "Faria Instruments" ;
VAL_ 2381119488 Industry_Code 0 "Global" 1 "Highway" 2 "Agriculture" 3 "Construction" 4 "Marine Industry" 5 "Industrial" ;
VAL_ 2381119488 Function_Code 0 "Request" 1 "Command" 2 "Acknowledge" 3 "Read Fields" 4 "Read Fields Reply" 5 "Write Fields" 6 "Write Fields Reply" ;
VAL_ 2381119488 Function_Code 0 "Request" 1 "Command" 2 "Acknowledge" 3 "Read Fields" 4 "Read Fields Reply" 5 "Write Fields" 6 "Write Fields Reply" ;
VAL_ 2381119488 Manufacturer_Code 69 "ARKS Enterprises" 78 "FW Murphy/Enovation Controls" 80 "Twin Disc" 85 "Kohler Power Systems" 88 "Hemisphere GPS" 135 "Airmar" 137 "Maretron" 140 "Lowrance" 144 "Mercury Marine" 147 "Nautibus Electronic" 148 "Blue Water Data" 154 "Westerbeke" 157 "ISSPRO" 161 "Offshore Systems (UK)" 163 "Evinrude/BRP" 165 "CPAC Systems" 168 "Xantrex Technology" 169 "Marlin Technologies" 172 "Yanmar Marine" 174 "Volvo Penta" 176 "Carling Technologies Inc. (Moritz Aerospace)" 185 "Beede Instruments" 192 "Floscan Instrument" 193 "Nobeltec" 198 "Mystic Valley Communications" 199 "Actia" 201 "Disenos Y Technologia" 211 "Digital Switching Systems" 215 "Xintex/Atena" 224 "EMMI NETWORK" 228 "ZF" 229 "Garmin" 233 "Yacht Monitoring Solutions" 235 "Sailormade Marine Telemetry/Tetra Technology" 243 "Eride" 257 "Honda Motor" 272 "Groco" 273 "Actisense" 274 "Amphenol LTW Technology" 275 "Navico" 283 "Hamilton Jet" 285 "Sea Recovery" 286 "Coelmo SRL Italy" 295 "BEP Marine" 304 "Empir Bus" 305 "NovAtel" 306 "Sleipner Motor" 307 "MBW Technologies" 315 "ICOM" 328 "Qwerty" 329 "Dief" 341 "Boening Automationstechnologie" 345 "Korean Maritime University" 351 "Thrane and Thrane" 355 "Mastervolt" 356 "Fischer Panda Generators" 358 "Victron Energy" 370 "Rolls Royce Marine" 373 "Electronic Design" 374 "Northern Lights" 378 "Glendinning" 381 "B & G" 384 "Rose Point Navigation Systems" 385 "Johnson Outdoors Marine Electronics Inc Geonav" 394 "Capi 2" 396 "Beyond Measure" 400 "Livorsi Marine" 404 "ComNav" 409 "Chetco" 419 "Fusion Electronics" 421 "Standard Horizon" 422 "True Heading" 426 "Egersund Marine Electronics" 427 "em-trak Marine Electronics" 431 "Tohatsu Co, JP" 437 "Digital Yacht" 438 "Comar Systems Limited" 440 "Cummins" 443 "VDO (aka Continental-Corporation)" 451 "Parker Hannifin aka Village Marine Tech" 459 "Alltek Marine Electronics" 460 "SAN GIORGIO S.E.I.N" 466 "Veethree Electronics & Marine" 470 "SI-TEX Marine Electronics" 471 "Sea Cross Marine" 475 "GME aka Standard Communications" 476 "Humminbird Marine Electronics" 478 "Ocean Sat" 481 "Chetco Digital Instruments" 493 "Watcheye" 499 "Lcj Capteurs" 502 "Attwood Marine" 503 "Naviop S.R.L." 504 "Vesper Marine" 510 "Marinesoft" 513 "Simarine" 517 "NoLand Engineering" 518 "Transas USA" 529 "National Instruments Korea" 530 "National Marine Electronics Association" 532 "Onwa Marine" 540 "Webasto" 571 "Marinecraft (South Korea)" 573 "McMurdo Group aka Orolia" 578 "Advansea" 579 "KVH" 580 "San Jose Technology" 583 "Yacht Control" 586 "Suzuki Motor" 591 "US Coast Guard" 595 "Ship Module aka Customware" 600 "Aquatic AV" 605 "Aventics" 606 "Intellian" 612 "SamwonIT" 614 "Arlt Tecnologies" 637 "Bavaria Yachts" 641 "Diverse Yacht Services" 644 "Wema U.S.A dba KUS" 658 "Shenzhen Jiuzhou Himunication" 688 "Rockford" 699 "Harman International" 704 "JL Audio" 708 "Lars Thrane" 715 "Autonnic" 717 "Yacht Devices" 734 "REAP Systems" 735 "AEM Performance Electronics" 739 "LxNav" 741 "Littelfuse, Inc (formerly Carling Technologies)" 743 "DaeMyung" 744 "Woosung" 748 "ISOTTA IFRA srl" 773 "Clarion US" 776 "HMI Systems" 777 "Ocean Signal" 778 "Seakeeper" 781 "Poly Planar" 785 "Fischer Panda DE" 795 "Broyda Industries" 796 "Canadian Automotive" 797 "Tides Marine" 798 "Lumishore" 799 "Still Water Designs and Audio" 802 "BJ Technologies (Beneteau)" 803 "Gill Sensors" 811 "Blue Water Desalination" 815 "FLIR" 824 "Undheim Systems" 826 "Lewmar" 838 "TeamSurv" 844 "Fell Marine" 847 "Oceanvolt" 862 "Prospec" 868 "Data Panel" 890 "L3 Technologies" 894 "Rhodan Marine Systems" 896 "Nexfour Solutions" 905 "ASA Electronics" 909 "Marines Co (South Korea)" 911 "Nautic-on" 917 "Sentinel" 929 "JL Marine Systems" 930 "Ecotronix" 944 "Zontisa Marine" 951 "EXOR International" 962 "Timbolier Industries" 963 "TJC Micro" 968 "Cox Powertrain" 969 "Blue Seas" 981 "Kobelt Manufacturing" 992 "Blue Ocean IOT" 997 "Xenta Systems" 999 "Signal K" 1004 "Ultraflex" 1008 "Lintest SmartBoat" 1011 "Soundmax" 1020 "Team Italia Marine (Onyx Marine Automation s.r.l)" 1021 "Entratech" 1022 "ITC" 1029 "The Marine Guardian" 1047 "Sonic" 1051 "ProNav" 1053 "Vetus Maxwell INC." 1056 "Lithium Pros" 1059 "Boatrax" 1062 "Marol Co ltd" 1065 "CALYPSO Instruments" 1066 "Spot Zero Water" 1069 "Lithionics Battery" 1070 "Quick-teck Electronics" 1075 "Uniden America" 1083 "Nauticoncept" 1084 "Shadow-Caster LED lighting" 1085 "Wet Sounds" 1088 "E-T-A Circuit Breakers" 1092 "Scheiber" 1100 "Smart Yachts International Limited" 1109 "Dockmate" 1114 "Bobs Machine" 1118 "L3Harris ASV" 1119 "Balmar" 1120 "Elettromedia" 1127 "Electromaax" 1140 "Across Oceans Systems" 1145 "Kiwi Yachting" 1150 "BSB Artificial Intelligence" 1151 "Orca Technologies" 1154 "TBS Electronics" 1158 "Technoton Electroics" 1160 "MG Energy Systems" 1169 "Sea Machine Robotics" 1171 "Vista Manufacturing" 1183 "Zipwake" 1186 "Sailmon" 1192 "Airmoniq Pro Kft" 1194 "Sierra Marine" 1200 "Xinuo Information Technology (Xiamen)" 1218 "Septentrio" 1233 "NKE Marine Electronics" 1238 "SuperTrack Aps" 1239 "Honda Electronics" 1245 "Raritan Engineering" 1249 "Integrated Power Solutions AG" 1260 "Interactive Technologies" 1283 "LTG-Tech" 1299 "Energy Solutions (UK)" 1300 "WATT Fuel Cell" 1302 "Pro Mainer" 1305 "Dragonfly Energy" 1306 "Koden Electronics" 1311 "Humphree" 1316 "Hinkley Yachts" 1317 "Global Marine Management GmbH (GMM)" 1320 "Triskel Marine" 1330 "Warwick Control Technologies" 1331 "Dolphin Charger" 1337 "Barnacle Systems" 1348 "Radian IoT" 1353 "Ocean LED Marine" 1359 "BluNav" 1361 "OVA (Nantong Saiyang Electronics Co., Ltd)" 1368 "RAD Propulsion" 1369 "Electric Yacht" 1372 "Elco Motor Yachts" 1384 "Tecnoseal Foundry S.r.l" 1385 "Pro Charging Systems" 1389 "EVEX" 1398 "Gobius Sensor Technology" 1403 "Arco Marine" 1408 "Lenco Marine" 1413 "Naocontrol" 1417 "Revatek" 1438 "Aeolionics" 1439 "PredictWind" 1440 "Egis Mobile Electric" 1445 "Starboard Yacht Group" 1446 "Roswell Marine" 1451 "ePropulsion (Guangdong ePropulsion Technology Ltd.)" 1452 "Micro-Air" 1453 "Vital Battery" 1458 "Ride Controller" 1460 "Tocaro Blue" 1461 "Vanquish Yachts" 1471 "FT Technologies" 1478 "Alps Alpine" 1481 "E-Force Marine" 1482 "CMC Marine" 1483 "Nanjing Sandemarine Information Technology" 1850 "Teleflex Marine (SeaStar Solutions)" 1851 "Raymarine" 1852 "Navionics" 1853 "Japan Radio" 1854 "Northstar Technologies" 1855 "Furuno" 1856 "Trimble" 1857 "Simrad" 1858 "Litton" 1859 "Kvasar" 1860 "MMP" 1861 "Vector Cantech" 1862 "Yamaha Marine" 1863 "Faria Instruments" ;
VAL_ 2381119488 Industry_Code 0 "Global" 1 "Highway" 2 "Agriculture" 3 "Construction" 4 "Marine Industry" 5 "Industrial" ;
VAL_ 2381119488 Function_Code 0 "Request" 1 "Command" 2 "Acknowledge" 3 "Read Fields" 4 "Read Fields Reply" 5 "Write Fields" 6 "Write Fields Reply" ;
VAL_ 2381119488 Manufacturer_Code 69 "ARKS Enterprises" 78 "FW Murphy/Enovation Controls" 80 "Twin Disc" 85 "Kohler Power Systems" 88 "Hemisphere GPS" 135 "Airmar" 137 "Maretron" 140 "Lowrance" 144 "Mercury Marine" 147 "Nautibus Electronic" 148 "Blue Water Data" 154 "Westerbeke" 157 "ISSPRO" 161 "Offshore Systems (UK)" 163 "Evinrude/BRP" 165 "CPAC Systems" 168 "Xantrex Technology" 169 "Marlin Technologies" 172 "Yanmar Marine" 174 "Volvo Penta" 176 "Carling Technologies Inc. (Moritz Aerospace)" 185 "Beede Instruments" 192 "Floscan Instrument" 193 "Nobeltec" 198 "Mystic Valley Communications" 199 "Actia" 201 "Disenos Y Technologia" 211 "Digital Switching Systems" 215 "Xintex/Atena" 224 "EMMI NETWORK" 228 "ZF" 229 "Garmin" 233 "Yacht Monitoring Solutions" 235 "Sailormade Marine Telemetry/Tetra Technology" 243 "Eride" 257 "Honda Motor" 272 "Groco" 273 "Actisense" 274 "Amphenol LTW Technology" 275 "Navico" 283 "Hamilton Jet" 285 "Sea Recovery" 286 "Coelmo SRL Italy" 295 "BEP Marine" 304 "Empir Bus" 305 "NovAtel" 306 "Sleipner Motor" 307 "MBW Technologies" 315 "ICOM" 328 "Qwerty" 329 "Dief" 341 "Boening Automationstechnologie" 345 "Korean Maritime University" 351 "Thrane and Thrane" 355 "Mastervolt" 356 "Fischer Panda Generators" 358 "Victron Energy" 370 "Rolls Royce Marine" 373 "Electronic Design" 374 "Northern Lights" 378 "Glendinning" 381 "B & G" 384 "Rose Point Navigation Systems" 385 "Johnson Outdoors Marine Electronics Inc Geonav" 394 "Capi 2" 396 "Beyond Measure" 400 "Livorsi Marine" 404 "ComNav" 409 "Chetco" 419 "Fusion Electronics" 421 "Standard Horizon" 422 "True Heading" 426 "Egersund Marine Electronics" 427 "em-trak Marine Electronics" 431 "Tohatsu Co, JP" 437 "Digital Yacht" 438 "Comar Systems Limited" 440 "Cummins" 443 "VDO (aka Continental-Corporation)" 451 "Parker Hannifin aka Village Marine Tech" 459 "Alltek Marine Electronics" 460 "SAN GIORGIO S.E.I.N" 466 "Veethree Electronics & Marine" 470 "SI-TEX Marine Electronics" 471 "Sea Cross Marine" 475 "GME aka Standard Communications" 476 "Humminbird Marine Electronics" 478 "Ocean Sat" 481 "Chetco Digital Instruments" 493 "Watcheye" 499 "Lcj Capteurs" 502 "Attwood Marine" 503 "Naviop S.R.L." 504 "Vesper Marine" 510 "Marinesoft" 513 "Simarine" 517 "NoLand Engineering" 518 "Transas USA" 529 "National Instruments Korea" 530 "National Marine Electronics Association" 532 "Onwa Marine" 540 "Webasto" 571 "Marinecraft (South Korea)" 573 "McMurdo Group aka Orolia" 578 "Advansea" 579 "KVH" 580 "San Jose Technology" 583 "Yacht Control" 586 "Suzuki Motor" 591 "US Coast Guard" 595 "Ship Module aka Customware" 600 "Aquatic AV" 605 "Aventics" 606 "Intellian" 612 "SamwonIT" 614 "Arlt Tecnologies" 637 "Bavaria Yachts" 641 "Diverse Yacht Services" 644 "Wema U.S.A dba KUS" 658 "Shenzhen Jiuzhou Himunication" 688 "Rockford" 699 "Harman International" 704 "JL Audio" 708 "Lars Thrane" 715 "Autonnic" 717 "Yacht Devices" 734 "REAP Systems" 735 "AEM Performance Electronics" 739 "LxNav" 741 "Littelfuse, Inc (formerly Carling Technologies)" 743 "DaeMyung" 744 "Woosung" 748 "ISOTTA IFRA srl" 773 "Clarion US" 776 "HMI Systems" 777 "Ocean Signal" 778 "Seakeeper" 781 "Poly Planar" 785 "Fischer Panda DE" 795 "Broyda Industries" 796 "Canadian Automotive" 797 "Tides Marine" 798 "Lumishore" 799 "Still Water Designs and Audio" 802 "BJ Technologies (Beneteau)" 803 "Gill Sensors" 811 "Blue Water Desalination" 815 "FLIR" 824 "Undheim Systems" 826 "Lewmar" 838 "TeamSurv" 844 "Fell Marine" 847 "Oceanvolt" 862 "Prospec" 868 "Data Panel" 890 "L3 Technologies" 894 "Rhodan Marine Systems" 896 "Nexfour Solutions" 905 "ASA Electronics" 909 "Marines Co (South Korea)" 911 "Nautic-on" 917 "Sentinel" 929 "JL Marine Systems" 930 "Ecotronix" 944 "Zontisa Marine" 951 "EXOR International" 962 "Timbolier Industries" 963 "TJC Micro" 968 "Cox Powertrain" 969 "Blue Seas" 981 "Kobelt Manufacturing" 992 "Blue Ocean IOT" 997 "Xenta Systems" 999 "Signal K" 1004 "Ultraflex" 1008 "Lintest SmartBoat" 1011 "Soundmax" 1020 "Team Italia Marine (Onyx Marine Automation s.r.l)" 1021 "Entratech" 1022 "ITC" 1029 "The Marine Guardian" 1047 "Sonic" 1051 "ProNav" 1053 "Vetus Maxwell INC." 1056 "Lithium Pros" 1059 "Boatrax" 1062 "Marol Co ltd" 1065 "CALYPSO Instruments" 1066 "Spot Zero Water" 1069 "Lithionics Battery" 1070 "Quick-teck Electronics" 1075 "Uniden America" 1083 "Nauticoncept" 1084 "Shadow-Caster LED lighting" 1085 "Wet Sounds" 1088 "E-T-A Circuit Breakers" 1092 "Scheiber" 1100 "Smart Yachts International Limited" 1109 "Dockmate" 1114 "Bobs Machine" 1118 "L3Harris ASV" 1119 "Balmar" 1120 "Elettromedia" 1127 "Electromaax" 1140 "Across Oceans Systems" 1145 "Kiwi Yachting" 1150 "BSB Artificial Intelligence" 1151 "Orca Technologies" 1154 "TBS Electronics" 1158 "Technoton Electroics" 1160 "MG Energy Systems" 1169 "Sea Machine Robotics" 1171 "Vista Manufacturing" 1183 "Zipwake" 1186 "Sailmon" 1192 "Airmoniq Pro Kft" 1194 "Sierra Marine" 1200 "Xinuo Information Technology (Xiamen)" 1218 "Septentrio" 1233 "NKE Marine Electronics" 1238 "SuperTrack Aps" 1239 "Honda Electronics" 1245 "Raritan Engineering" 1249 "Integrated Power Solutions AG" 1260 "Interactive Technologies" 1283 "LTG-Tech" 1299 "Energy Solutions (UK)" 1300 "WATT Fuel Cell" 1302 "Pro Mainer" 1305 "Dragonfly Energy" 1306 "Koden Electronics" 1311 "Humphree" 1316 "Hinkley Yachts" 1317 "Global Marine Management GmbH (GMM)" 1320 "Triskel Marine" 1330 "Warwick Control Technologies" 1331 "Dolphin Charger" 1337 "Barnacle Systems" 1348 "Radian IoT" 1353 "Ocean LED Marine" 1359 "BluNav" 1361 "OVA (Nantong Saiyang Electronics Co., Ltd)" 1368 "RAD Propulsion" 1369 "Electric Yacht" 1372 "Elco Motor Yachts" 1384 "Tecnoseal Foundry S.r.l" 1385 "Pro Charging Systems" 1389 "EVEX" 1398 "Gobius Sensor Technology" 1403 "Arco Marine" 1408 "Lenco Marine" 1413 "Naocontrol" 1417 "Revatek" 1438 "Aeolionics" 1439 "PredictWind" 1440 "Egis Mobile Electric" 1445 "Starboard Yacht Group" 1446 "Roswell Marine" 1451 "ePropulsion (Guangdong ePropulsion Technology Ltd.)" 1452 "Micro-Air" 1453 "Vital Battery" 1458 "Ride Controller" 1460 "Tocaro Blue" 1461 "Vanquish Yachts" 1471 "FT Technologies" 1478 "Alps Alpine" 1481 "E-Force Marine" 1482 "CMC Marine" 1483 "Nanjing Sandemarine Information Technology" 1850 "Teleflex Marine (SeaStar Solutions)" 1851 "Raymarine" 1852 "Navionics" 1853 "Japan Radio" 1854 "Northstar Technologies" 1855 "Furuno" 1856 "Trimble" 1857 "Simrad" 1858 "Litton" 1859 "Kvasar" 1860 "MMP" 1861 "Vector Cantech" 1862 "Yamaha Marine" 1863 "Faria Instruments" ;
VAL_ 2381119488 Industry_Code 0 "Global" 1 "Highway" 2 "Agriculture" 3 "Construction" 4 "Marine Industry" 5 "Industrial" ;
VAL_ 2582511616 Function_Code 0 "Transmit PGN list" 1 "Receive PGN list" ;

BA_DEF_ BO_ "GenMsgCycleTime" INT 0 60000;
BA_DEF_ BO_ "ProtocolType" STRING;

BA_DEF_ BO_ "J1939PGN" INT 0 262143;
BA_ "J1939PGN" BO_ 2633977856 65360;
BA_ "J1939PGN" BO_ 2566869248 65361;
BA_ "J1939PGN" BO_ 2566871808 65371;
BA_ "J1939PGN" BO_ 2566872576 65374;
BA_ "J1939PGN" BO_ 2633982720 65379;
BA_ "J1939PGN" BO_ 2566880000 65403;
BA_ "J1939PGN" BO_ 2633990144 65408;
BA_ "J1939PGN" BO_ 2633990400 65409;
BA_ "J1939PGN" BO_ 2633990656 65410;
BA_ "J1939PGN" BO_ 2566884352 65420;
BA_ "GenMsgCycleTime" BO_ 2566884352 1000;
BA_ "J1939PGN" BO_ 2566885376 65424;
BA_ "J1939PGN" BO_ 2566889472 65440;
BA_ "J1939PGN" BO_ 2566889728 65441;
BA_ "J1939PGN" BO_ 2566897664 65472;
BA_ "J1939PGN" BO_ 2566899712 65480;
BA_ "J1939PGN" BO_ 2381119488 126208;
BA_ "J1939PGN" BO_ 2381119488 126208;
BA_ "J1939PGN" BO_ 2381119488 126208;
BA_ "J1939PGN" BO_ 2381119488 126208;
BA_ "J1939PGN" BO_ 2381119488 126208;
BA_ "J1939PGN" BO_ 2381119488 126208;
BA_ "J1939PGN" BO_ 2381119488 126208;
BA_ "J1939PGN" BO_ 2381119488 126208;
BA_ "J1939PGN" BO_ 2582511616 126464;
BA_ "J1939PGN" BO_ 2582577152 126720;
BA_ "J1939PGN" BO_ 2582577152 126720;
BA_ "J1939PGN" BO_ 2582577152 126720;
BA_ "J1939PGN" BO_ 2582577152 126720;
BA_ "J1939PGN" BO_ 2582577152 126720;
BA_ "J1939PGN" BO_ 2582577152 126720;
BA_ "J1939PGN" BO_ 2582577152 126720;
BA_ "J1939PGN" BO_ 2582577152 126720;
BA_ "J1939PGN" BO_ 2582577152 126720;
BA_ "J1939PGN" BO_ 2582577152 126720;
BA_ "J1939PGN" BO_ 2582577152 126720;
BA_ "J1939PGN" BO_ 2582577152 126720;
BA_ "J1939PGN" BO_ 2582577152 126720;
BA_ "J1939PGN" BO_ 2582577152 126720;
BA_ "J1939PGN" BO_ 2582577152 126720;
BA_ "J1939PGN" BO_ 2582577152 126720;
BA_ "J1939PGN" BO_ 2582577152 126720;
BA_ "J1939PGN" BO_ 2582577152 126720;
BA_ "J1939PGN" BO_ 2582577152 126720;
BA_ "J1939PGN" BO_ 2582577152 126720;
BA_ "J1939PGN" BO_ 2582577152 126720;
BA_ "J1939PGN" BO_ 2582577152 126720;
BA_ "J1939PGN" BO_ 2582577152 126720;
BA_ "J1939PGN" BO_ 2582577152 126720;
BA_ "J1939PGN" BO_ 2582577152 126720;
BA_ "J1939PGN" BO_ 2582577152 126720;
BA_ "J1939PGN" BO_ 2582577152 126720;
BA_ "J1939PGN" BO_ 2582577152 126720;
BA_ "J1939PGN" BO_ 2582577152 126720;
BA_ "J1939PGN" BO_ 2582577152 126720;
BA_ "J1939PGN" BO_ 2582577152 126720;
BA_ "J1939PGN" BO_ 2582577152 126720;
BA_ "J1939PGN" BO_ 2582577152 126720;
BA_ "J1939PGN" BO_ 2582577152 126720;
BA_ "J1939PGN" BO_ 2582577152 126720;
BA_ "J1939PGN" BO_ 2582577152 126720;
BA_ "J1939PGN" BO_ 2582577152 126720;
BA_ "J1939PGN" BO_ 2582577152 126720;
BA_ "J1939PGN" BO_ 2582577152 126720;
BA_ "J1939PGN" BO_ 2582577152 126720;
BA_ "J1939PGN" BO_ 2582577152 126720;
BA_ "J1939PGN" BO_ 2582577152 126720;
BA_ "J1939PGN" BO_ 2582577152 126720;
BA_ "J1939PGN" BO_ 2582577152 126720;
